VERSION ""

NS_ :

BS_:

BU_: WPC2 RLPSU DPSU APSU PSB SHVU_RR vHS_B2 FCS EMCU SLB ARS RCM CGW_CCU vDummy_HS_B ATS RLHV SGU PFSU ALBCU DSAU SWRC SHVU_FR RCS RRPSU BLTN_CAM SCM DLBCU OHCL RWPC RRHV WPC HOD ASAU

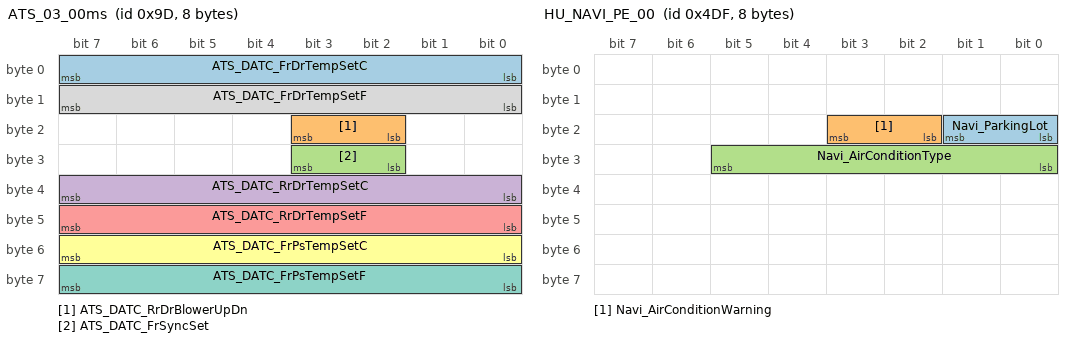
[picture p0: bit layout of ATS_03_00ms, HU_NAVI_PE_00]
BO_ 157 ATS_03_00ms: 8 ATS
 SG_ ATS_DATC_FrDrTempSetC : 0|8@1+ (0.5,14) [0|0] ""  CGW_CCU
 SG_ ATS_DATC_RrDrBlowerUpDn : 18|2@1+ (1,0) [0|0] ""  CGW_CCU
 SG_ ATS_DATC_FrSyncSet : 26|2@1+ (1,0) [0|0] ""  CGW_CCU
 SG_ ATS_DATC_RrDrTempSetC : 32|8@1+ (0.5,14) [0|0] ""  CGW_CCU
 SG_ ATS_DATC_RrDrTempSetF : 40|8@1+ (1,56) [0|0] ""  CGW_CCU
 SG_ ATS_DATC_FrPsTempSetC : 48|8@1+ (0.5,14) [0|0] ""  CGW_CCU
 SG_ ATS_DATC_FrPsTempSetF : 56|8@1+ (1,56) [0|0] ""  CGW_CCU
 SG_ ATS_DATC_FrDrTempSetF : 8|8@1+ (1,56) [0|0] ""  CGW_CCU

BO_ 2176872452 HTCU_05_10ms_4: 8 CGW_CCU

BO_ 158 ATS_02_00ms: 8 ATS
 SG_ ATS_DATC_FrDrBlowerSet : 12|4@1+ (1,0) [0|0] ""  CGW_CCU
 SG_ ATS_DATC_RrDrTempUpDn : 2|2@1+ (1,0) [0|0] ""  CGW_CCU
 SG_ ATS_DATC_RrDrBlowerSet : 20|4@1+ (1,0) [0|0] ""  CGW_CCU
 SG_ ATS_DATC_RrDrModeSet : 24|4@1+ (1,0) [0|0] ""  CGW_CCU
 SG_ ATS_DATC_FrDrModeSet : 28|4@1+ (1,0) [0|0] ""  CGW_CCU
 SG_ ATS_DATC_RrOnOffSet : 32|2@1+ (1,0) [0|0] ""  Vector__XXX
 SG_ ATS_DATC_IntakeSet : 34|2@1+ (1,0) [0|0] ""  CGW_CCU
 SG_ ATS_DATC_OffReq : 36|2@1+ (1,0) [0|0] ""  Vector__XXX
 SG_ ATS_DATC_FrDrAutoSet : 38|2@1+ (1,0) [0|0] ""  CGW_CCU
 SG_ ATS_DATC_FrPsTempUpDn : 4|2@1+ (1,0) [0|0] ""  CGW_CCU
 SG_ ATS_DATC_FrDefog : 42|2@1+ (1,0) [0|0] ""  CGW_CCU
 SG_ ATS_DATC_RrSyncSet : 44|2@1+ (1,0) [0|0] ""  CGW_CCU
 SG_ ATS_DATC_AcSet : 46|2@1+ (1,0) [0|0] ""  CGW_CCU
 SG_ ATS_DATC_AirCleaningSet : 56|2@1+ (1,0) [0|0] ""  CGW_CCU
 SG_ ATS_DATC_FrDrBlowerUpDn : 58|2@1+ (1,0) [0|0] ""  CGW_CCU
 SG_ ATS_DATC_FrDrTempUpDn : 6|2@1+ (1,0) [0|0] ""  CGW_CCU
 SG_ ATS_DATC_RrDrAutoSet : 62|2@1+ (1,0) [0|0] ""  CGW_CCU

BO_ 694 ASAU_02_00ms: 8 APSU
 SG_ ASAU_NotFootMsgOperStaWarn : 0|2@1+ (1,0) [0|0] ""  Vector__XXX

BO_ 1247 HU_NAVI_PE_00: 8 CGW_CCU
 SG_ Navi_ParkingLot : 16|2@1+ (1,0) [0|0] ""  Vector__XXX
 SG_ Navi_AirConditionWarning : 18|2@1+ (1,0) [0|0] ""  RCM
 SG_ Navi_AirConditionType : 24|6@1+ (1,0) [0|0] ""  Vector__XXX

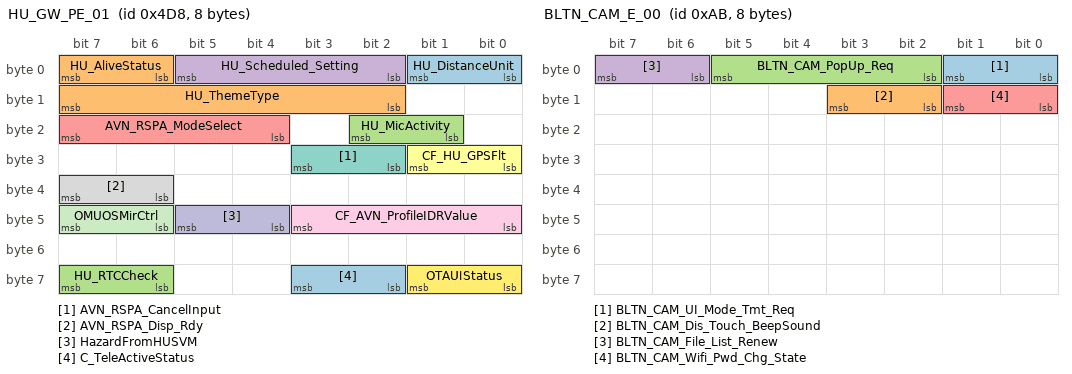
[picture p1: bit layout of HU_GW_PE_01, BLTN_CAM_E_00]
BO_ 1240 HU_GW_PE_01: 8 CGW_CCU
 SG_ HU_DistanceUnit : 0|2@1+ (1,0) [0|0] ""  Vector__XXX
 SG_ HU_ThemeType : 10|6@1+ (1,0) [0|0] ""  ATS,BLTN_CAM
 SG_ HU_MicActivity : 17|2@1+ (1,0) [0|0] ""  Vector__XXX
 SG_ HU_Scheduled_Setting : 2|4@1+ (1,0) [0|0] ""  Vector__XXX
 SG_ AVN_RSPA_ModeSelect : 20|4@1+ (1,0) [0|0] ""  Vector__XXX
 SG_ CF_HU_GPSFlt : 24|2@1+ (1,0) [0|0] ""  Vector__XXX
 SG_ AVN_RSPA_CancelInput : 26|2@1+ (1,0) [0|3] ""  Vector__XXX
 SG_ AVN_RSPA_Disp_Rdy : 38|2@1+ (1,0) [0|0] ""  Vector__XXX
 SG_ CF_AVN_ProfileIDRValue : 40|4@1+ (1,0) [0|0] ""  WPC,RWPC,DPSU,DLBCU,RCM,BLTN_CAM,SGU,WPC2
 SG_ HazardFromHUSVM : 44|2@1+ (1,0) [0|0] ""  Vector__XXX
 SG_ OMUOSMirCtrl : 46|2@1+ (1,0) [0|0] ""  Vector__XXX
 SG_ OTAUIStatus : 56|2@1+ (1,0) [0|0] ""  Vector__XXX
 SG_ C_TeleActiveStatus : 58|2@1+ (1,0) [0|0] ""  Vector__XXX
 SG_ HU_AliveStatus : 6|2@1+ (1,0) [0|0] ""  Vector__XXX
 SG_ HU_RTCCheck : 62|2@1+ (1,0) [0|0] ""  APSU

BO_ 2424580353 DATC_12_200ms_1: 8 CGW_CCU
 SG_ DATC_Crc12Val : 0|16@1+ (1,0) [0|0] ""  Vector__XXX
 SG_ DATC_AlvCnt12Val : 16|8@1+ (1,0) [0|0] ""  Vector__XXX
 SG_ DATC_StrWhlHtrSwReq : 24|2@1+ (1,0) [0|0] ""  Vector__XXX
 SG_ DATC_FRStHtrSwReq : 26|2@1+ (1,0) [0|0] ""  APSU,SHVU_FR,SHVU_RR,DPSU
 SG_ DATC_FRStVentSwReq : 28|2@1+ (1,0) [0|0] ""  APSU,SHVU_FR,SHVU_RR,DPSU
 SG_ DATC_RrDefSw : 30|2@1+ (1,0) [0|0] ""  Vector__XXX
 SG_ DATC_FLStOpReq : 32|4@1+ (1,0) [0|0] ""  APSU,SHVU_FR,SHVU_RR,DPSU
 SG_ DATC_FRStOpReq : 36|4@1+ (1,0) [0|0] ""  APSU,SHVU_FR,SHVU_RR
 SG_ DATC_FLStHtrSwReq : 40|2@1+ (1,0) [0|0] ""  APSU,SHVU_FR,SHVU_RR,DPSU
 SG_ DATC_FLStVentSwReq : 42|2@1+ (1,0) [0|0] ""  APSU,SHVU_FR,SHVU_RR,DPSU
 SG_ DATC_FLStTmblrSwReq : 44|2@1+ (1,0) [0|0] ""  APSU,SHVU_FR
 SG_ DATC_FRStTmblrSwReq : 46|2@1+ (1,0) [0|0] ""  APSU,SHVU_FR
 SG_ DATC_RRStHtrSwReq : 48|2@1+ (1,0) [0|0] ""  RRHV,SHVU_FR,SHVU_RR,RRPSU,RLPSU
 SG_ DATC_RRStVentSwReq : 50|2@1+ (1,0) [0|0] ""  RRHV,SHVU_FR,SHVU_RR,RRPSU,RLPSU
 SG_ DATC_RLStHtrSwReq : 52|2@1+ (1,0) [0|0] ""  RLHV,SHVU_FR,SHVU_RR,RRPSU,RLPSU
 SG_ DATC_RLStVentSwReq : 54|2@1+ (1,0) [0|0] ""  RLHV,SHVU_FR,SHVU_RR,RRPSU,RLPSU
 SG_ DATC_FRWndShldHtSW : 56|2@1+ (1,0) [0|0] ""  Vector__XXX
 SG_ DATC_WhistlelNoise : 58|2@1+ (1,0) [0|0] ""  Vector__XXX
 SG_ DATC_WdwClsReq : 60|2@1+ (1,0) [0|0] ""  Vector__XXX
 SG_ DATC_RRSyncDis : 62|2@1+ (1,0) [0|0] ""  ATS

BO_ 171 BLTN_CAM_E_00: 8 BLTN_CAM
 SG_ BLTN_CAM_UI_Mode_Tmt_Req : 0|2@1+ (1,0) [0|0] ""  CGW_CCU
 SG_ BLTN_CAM_Dis_Touch_BeepSound : 10|2@1+ (1,0) [0|0] ""  Vector__XXX
 SG_ BLTN_CAM_PopUp_Req : 2|4@1+ (1,0) [0|0] ""  CGW_CCU
 SG_ BLTN_CAM_File_List_Renew : 6|2@1+ (1,0) [0|0] ""  CGW_CCU
 SG_ BLTN_CAM_Wifi_Pwd_Chg_State : 8|2@1+ (1,0) [0|0] ""  CGW_CCU

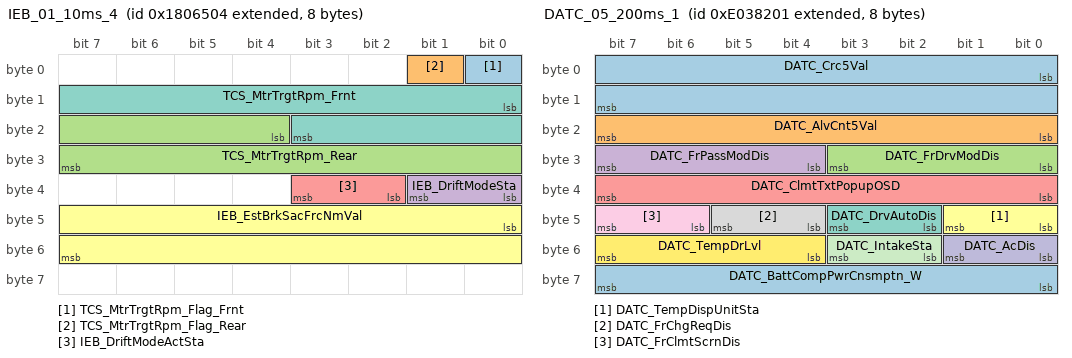
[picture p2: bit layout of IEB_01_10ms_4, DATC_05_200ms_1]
BO_ 2172675332 IEB_01_10ms_4: 8 CGW_CCU
 SG_ TCS_MtrTrgtRpm_Flag_Frnt : 0|1@1+ (1,0) [0|0] ""  Vector__XXX
 SG_ TCS_MtrTrgtRpm_Flag_Rear : 1|1@1+ (1,0) [0|0] ""  Vector__XXX
 SG_ TCS_MtrTrgtRpm_Rear : 20|12@1+ (8,0) [0|0] "rpm"  Vector__XXX
 SG_ IEB_DriftModeSta : 32|2@1+ (1,0) [0|0] ""  Vector__XXX
 SG_ IEB_DriftModeActSta : 34|2@1+ (1,0) [0|0] ""  Vector__XXX
 SG_ IEB_EstBrkSacFrcNmVal : 40|16@1+ (1,0) [0|0] ""  Vector__XXX
 SG_ TCS_MtrTrgtRpm_Frnt : 8|12@1+ (8,0) [0|0] "rpm"  Vector__XXX

BO_ 2382594561 DATC_05_200ms_1: 8 CGW_CCU
 SG_ DATC_Crc5Val : 0|16@1+ (1,0) [0|0] ""  Vector__XXX
 SG_ DATC_AlvCnt5Val : 16|8@1+ (1,0) [0|0] ""  Vector__XXX
 SG_ DATC_FrDrvModDis : 24|4@1+ (1,0) [0|0] ""  ATS
 SG_ DATC_FrPassModDis : 28|4@1+ (1,0) [0|0] ""  ATS
 SG_ DATC_ClmtTxtPopupOSD : 32|8@1+ (1,0) [0|0] ""  ATS
 SG_ DATC_TempDispUnitSta : 40|2@1+ (1,0) [0|0] ""  ATS
 SG_ DATC_DrvAutoDis : 42|2@1+ (1,0) [0|0] ""  ATS
 SG_ DATC_FrChgReqDis : 44|2@1+ (1,0) [0|0] ""  Vector__XXX
 SG_ DATC_FrClmtScrnDis : 46|2@1+ (1,0) [0|0] ""  ATS
 SG_ DATC_AcDis : 48|2@1+ (1,0) [0|0] ""  ATS
 SG_ DATC_IntakeSta : 50|2@1+ (1,0) [0|0] ""  Vector__XXX
 SG_ DATC_TempDrLvl : 52|4@1+ (1,0) [0|0] ""  Vector__XXX
 SG_ DATC_BattCompPwrCnsmptn_W : 56|8@1+ (40,0) [0|0] "W"  Vector__XXX

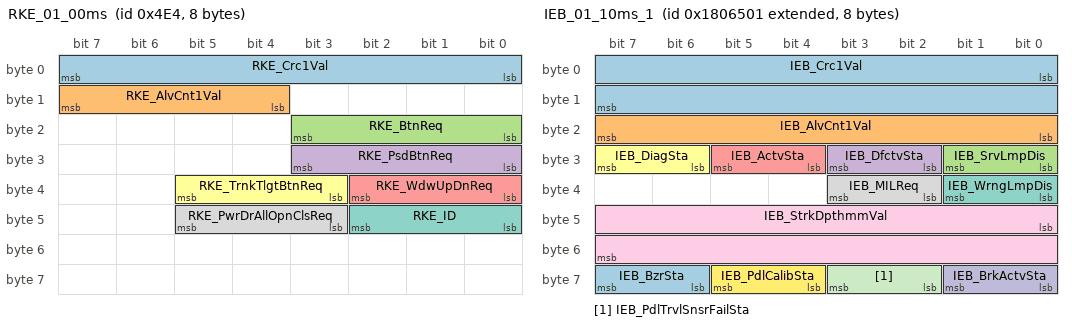
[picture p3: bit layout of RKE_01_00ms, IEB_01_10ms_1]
BO_ 1252 RKE_01_00ms: 8 CGW_CCU
 SG_ RKE_Crc1Val : 0|8@1+ (1,0) [0|0] ""  Vector__XXX
 SG_ RKE_AlvCnt1Val : 12|4@1+ (1,0) [0|0] ""  Vector__XXX
 SG_ RKE_BtnReq : 16|4@1+ (1,0) [0|0] ""  ATS
 SG_ RKE_PsdBtnReq : 24|4@1+ (1,0) [0|0] ""  Vector__XXX
 SG_ RKE_WdwUpDnReq : 32|3@1+ (1,0) [0|0] ""  RCM
 SG_ RKE_TrnkTlgtBtnReq : 35|3@1+ (1,0) [0|0] ""  Vector__XXX
 SG_ RKE_ID : 40|3@1+ (1,0) [0|0] ""  Vector__XXX
 SG_ RKE_PwrDrAllOpnClsReq : 43|3@1+ (1,0) [0|0] ""  Vector__XXX

BO_ 2172675329 IEB_01_10ms_1: 8 CGW_CCU
 SG_ IEB_Crc1Val : 0|16@1+ (1,0) [0|0] ""  Vector__XXX
 SG_ IEB_AlvCnt1Val : 16|8@1+ (1,0) [0|0] ""  Vector__XXX
 SG_ IEB_SrvLmpDis : 24|2@1+ (1,0) [0|0] ""  Vector__XXX
 SG_ IEB_DfctvSta : 26|2@1+ (1,0) [0|0] ""  Vector__XXX
 SG_ IEB_ActvSta : 28|2@1+ (1,0) [0|0] ""  Vector__XXX
 SG_ IEB_DiagSta : 30|2@1+ (1,0) [0|0] ""  Vector__XXX
 SG_ IEB_WrngLmpDis : 32|2@1+ (1,0) [0|0] ""  Vector__XXX
 SG_ IEB_MILReq : 34|2@1+ (1,0) [0|0] ""  Vector__XXX
 SG_ IEB_StrkDpthmmVal : 40|16@1- (0.1,0) [0|0] "mm"  Vector__XXX
 SG_ IEB_BrkActvSta : 56|2@1+ (1,0) [0|0] ""  BLTN_CAM
 SG_ IEB_PdlTrvlSnsrFailSta : 58|2@1+ (1,0) [0|0] ""  Vector__XXX
 SG_ IEB_PdlCalibSta : 60|2@1+ (1,0) [0|0] ""  Vector__XXX
 SG_ IEB_BzrSta : 62|2@1+ (1,0) [0|0] ""  Vector__XXX

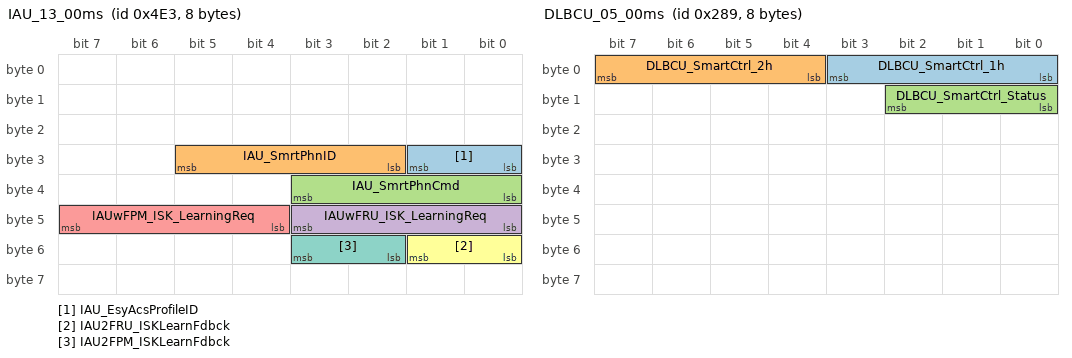
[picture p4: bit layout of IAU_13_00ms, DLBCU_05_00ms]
BO_ 1251 IAU_13_00ms: 8 CGW_CCU
 SG_ IAU_EsyAcsProfileID : 24|2@1+ (1,0) [0|0] ""  DPSU
 SG_ IAU_SmrtPhnID : 26|4@1+ (1,0) [0|0] ""  Vector__XXX
 SG_ IAU_SmrtPhnCmd : 32|4@1+ (1,0) [0|0] ""  Vector__XXX
 SG_ IAUwFRU_ISK_LearningReq : 40|4@1+ (1,0) [0|0] ""  Vector__XXX
 SG_ IAUwFPM_ISK_LearningReq : 44|4@1+ (1,0) [0|0] ""  Vector__XXX
 SG_ IAU2FRU_ISKLearnFdbck : 48|2@1+ (1,0) [0|0] ""  Vector__XXX
 SG_ IAU2FPM_ISKLearnFdbck : 50|2@1+ (1,0) [0|0] ""  Vector__XXX

BO_ 649 DLBCU_05_00ms: 8 DLBCU
 SG_ DLBCU_SmartCtrl_1h : 0|4@1+ (1,0) [0|0] ""  CGW_CCU
 SG_ DLBCU_SmartCtrl_2h : 4|4@1+ (1,0) [0|0] ""  CGW_CCU
 SG_ DLBCU_SmartCtrl_Status : 8|3@1+ (1,0) [0|0] ""  CGW_CCU

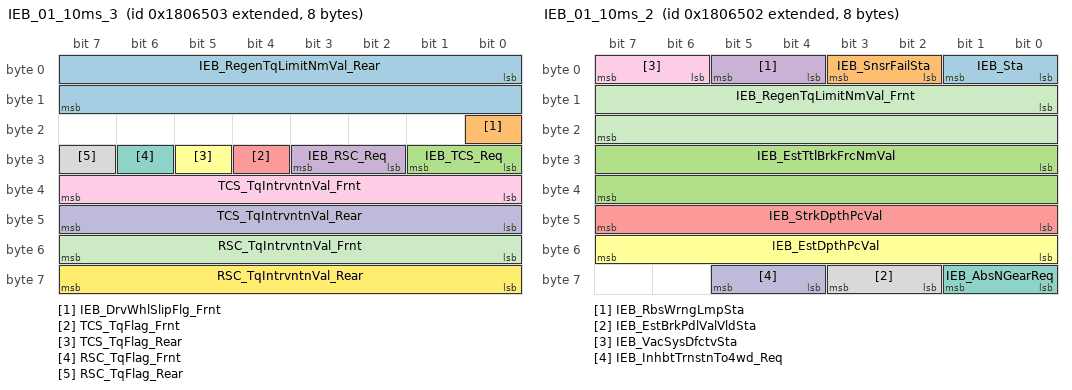
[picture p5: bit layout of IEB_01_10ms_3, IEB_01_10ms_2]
BO_ 2172675331 IEB_01_10ms_3: 8 CGW_CCU
 SG_ IEB_RegenTqLimitNmVal_Rear : 0|16@1+ (1,0) [0|0] "Nm"  Vector__XXX
 SG_ IEB_DrvWhlSlipFlg_Frnt : 16|1@1+ (1,0) [0|0] ""  Vector__XXX
 SG_ IEB_TCS_Req : 24|2@1+ (1,0) [0|0] ""  Vector__XXX
 SG_ IEB_RSC_Req : 26|2@1+ (1,0) [0|0] ""  Vector__XXX
 SG_ TCS_TqFlag_Frnt : 28|1@1+ (1,0) [0|0] ""  Vector__XXX
 SG_ TCS_TqFlag_Rear : 29|1@1+ (1,0) [0|0] ""  Vector__XXX
 SG_ RSC_TqFlag_Frnt : 30|1@1+ (1,0) [0|0] ""  Vector__XXX
 SG_ RSC_TqFlag_Rear : 31|1@1+ (1,0) [0|0] ""  Vector__XXX
 SG_ TCS_TqIntrvntnVal_Frnt : 32|8@1+ (0.390625,0) [0|0] "%"  Vector__XXX
 SG_ TCS_TqIntrvntnVal_Rear : 40|8@1+ (0.390625,0) [0|0] "%"  Vector__XXX
 SG_ RSC_TqIntrvntnVal_Frnt : 48|8@1+ (0.390625,0) [0|0] "%"  Vector__XXX
 SG_ RSC_TqIntrvntnVal_Rear : 56|8@1+ (0.390625,0) [0|0] "%"  Vector__XXX

BO_ 2172675330 IEB_01_10ms_2: 8 CGW_CCU
 SG_ IEB_Sta : 0|2@1+ (1,0) [0|0] ""  Vector__XXX
 SG_ IEB_SnsrFailSta : 2|2@1+ (1,0) [0|0] ""  Vector__XXX
 SG_ IEB_EstTtlBrkFrcNmVal : 24|16@1+ (1,0) [0|0] "Nm"  Vector__XXX
 SG_ IEB_RbsWrngLmpSta : 4|2@1+ (1,0) [0|0] ""  Vector__XXX
 SG_ IEB_StrkDpthPcVal : 40|8@1+ (0.39215,0) [0|0] "%"  Vector__XXX
 SG_ IEB_EstDpthPcVal : 48|8@1+ (0.390625,0) [0|0] "%"  Vector__XXX
 SG_ IEB_AbsNGearReq : 56|2@1+ (1,0) [0|0] ""  Vector__XXX
 SG_ IEB_EstBrkPdlValVldSta : 58|2@1+ (1,0) [0|0] ""  Vector__XXX
 SG_ IEB_VacSysDfctvSta : 6|2@1+ (1,0) [0|0] ""  Vector__XXX
 SG_ IEB_InhbtTrnstnTo4wd_Req : 60|2@1+ (1,0) [0|0] ""  Vector__XXX
 SG_ IEB_RegenTqLimitNmVal_Frnt : 8|16@1+ (1,0) [0|0] "Nm"  Vector__XXX

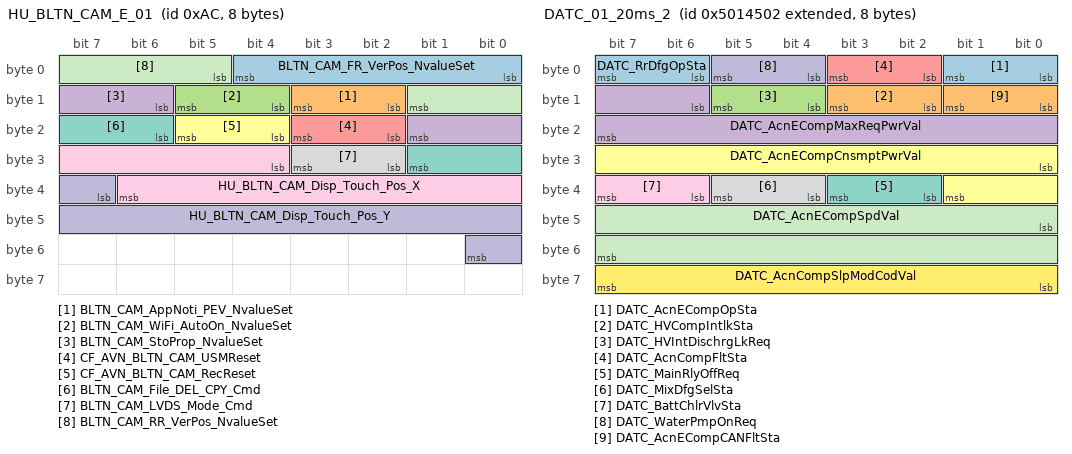
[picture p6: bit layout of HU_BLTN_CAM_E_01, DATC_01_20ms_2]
BO_ 172 HU_BLTN_CAM_E_01: 8 CGW_CCU
 SG_ BLTN_CAM_FR_VerPos_NvalueSet : 0|5@1+ (1,0) [0|0] ""  BLTN_CAM
 SG_ BLTN_CAM_AppNoti_PEV_NvalueSet : 10|2@1+ (1,0) [0|0] ""  BLTN_CAM
 SG_ BLTN_CAM_WiFi_AutoOn_NvalueSet : 12|2@1+ (1,0) [0|0] ""  BLTN_CAM
 SG_ BLTN_CAM_StoProp_NvalueSet : 14|4@1+ (1,0) [0|0] ""  BLTN_CAM
 SG_ CF_AVN_BLTN_CAM_USMReset : 18|2@1+ (1,0) [0|0] ""  BLTN_CAM
 SG_ CF_AVN_BLTN_CAM_RecReset : 20|2@1+ (1,0) [0|0] ""  BLTN_CAM
 SG_ BLTN_CAM_File_DEL_CPY_Cmd : 22|4@1+ (1,0) [0|0] ""  BLTN_CAM
 SG_ BLTN_CAM_LVDS_Mode_Cmd : 26|2@1+ (1,0) [0|0] ""  BLTN_CAM
 SG_ HU_BLTN_CAM_Disp_Touch_Pos_X : 28|11@1+ (1,0) [0|0] ""  BLTN_CAM
 SG_ HU_BLTN_CAM_Disp_Touch_Pos_Y : 39|10@1+ (1,0) [0|0] ""  BLTN_CAM
 SG_ BLTN_CAM_RR_VerPos_NvalueSet : 5|5@1+ (1,0) [0|0] ""  BLTN_CAM

BO_ 2231452930 DATC_01_20ms_2: 8 CGW_CCU
 SG_ DATC_AcnECompOpSta : 0|2@1+ (1,0) [0|0] "flag"  Vector__XXX
 SG_ DATC_HVCompIntlkSta : 10|2@1+ (1,0) [0|0] "flag"  Vector__XXX
 SG_ DATC_HVIntDischrgLkReq : 12|2@1+ (1,0) [0|0] "flag"  Vector__XXX
 SG_ DATC_AcnECompMaxReqPwrVal : 14|10@1+ (20,0) [0|0] "W"  Vector__XXX
 SG_ DATC_AcnCompFltSta : 2|2@1+ (1,0) [0|0] "flag"  Vector__XXX
 SG_ DATC_AcnECompCnsmptPwrVal : 24|10@1+ (20,0) [0|0] "W"  Vector__XXX
 SG_ DATC_MainRlyOffReq : 34|2@1+ (1,0) [0|0] "flag"  Vector__XXX
 SG_ DATC_MixDfgSelSta : 36|2@1+ (1,0) [0|0] "flag"  Vector__XXX
 SG_ DATC_BattChlrVlvSta : 38|2@1+ (1,0) [0|0] ""  Vector__XXX
 SG_ DATC_WaterPmpOnReq : 4|2@1+ (1,0) [0|0] "flag"  Vector__XXX
 SG_ DATC_AcnECompSpdVal : 40|16@1+ (1,0) [0|0] "rpm"  Vector__XXX
 SG_ DATC_AcnCompSlpModCodVal : 56|8@1+ (1,0) [0|0] ""  Vector__XXX
 SG_ DATC_RrDfgOpSta : 6|2@1+ (1,0) [0|0] "flag"  Vector__XXX
 SG_ DATC_AcnECompCANFltSta : 8|2@1+ (1,0) [0|0] "flag"  Vector__XXX

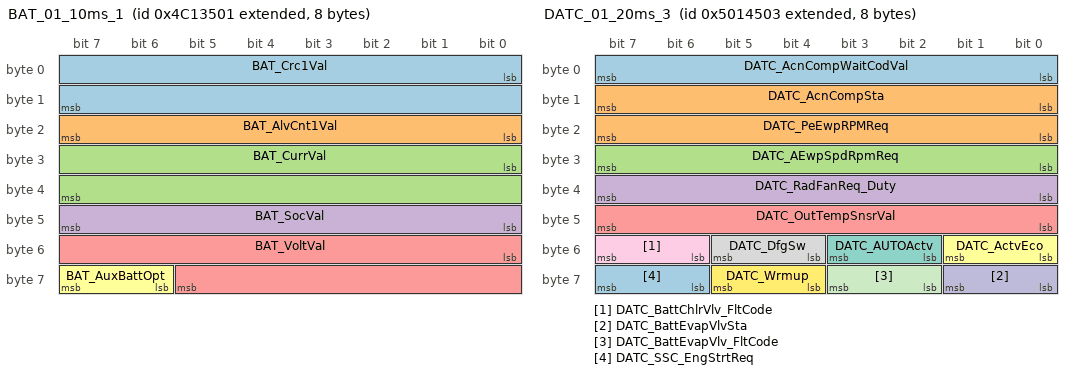
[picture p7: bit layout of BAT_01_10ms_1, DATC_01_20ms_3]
BO_ 2227254529 BAT_01_10ms_1: 8 CGW_CCU
 SG_ BAT_Crc1Val : 0|16@1+ (1,0) [0|0] ""  Vector__XXX
 SG_ BAT_AlvCnt1Val : 16|8@1+ (1,0) [0|0] ""  Vector__XXX
 SG_ BAT_CurrVal : 24|16@1+ (0.01,-327) [0|0] "A"  Vector__XXX
 SG_ BAT_SocVal : 40|8@1+ (1,0) [0|0] "%"  BLTN_CAM
 SG_ BAT_VoltVal : 48|14@1+ (0.001,6) [0|0] "V"  Vector__XXX
 SG_ BAT_AuxBattOpt : 62|2@1+ (1,0) [0|0] ""  Vector__XXX

BO_ 2231452931 DATC_01_20ms_3: 8 CGW_CCU
 SG_ DATC_AcnCompWaitCodVal : 0|8@1+ (1,0) [0|0] ""  Vector__XXX
 SG_ DATC_PeEwpRPMReq : 16|8@1+ (30,0) [0|0] ""  Vector__XXX
 SG_ DATC_AEwpSpdRpmReq : 24|8@1+ (20,0) [0|0] "rpm"  Vector__XXX
 SG_ DATC_RadFanReq_Duty : 32|8@1+ (1,0) [0|0] "%"  Vector__XXX
 SG_ DATC_OutTempSnsrVal : 40|8@1+ (0.5,-40) [0|0] "¡É"  RCM
 SG_ DATC_ActvEco : 48|2@1+ (1,0) [0|0] ""  Vector__XXX
 SG_ DATC_AUTOActv : 50|2@1+ (1,0) [0|0] ""  Vector__XXX
 SG_ DATC_DfgSw : 52|2@1+ (1,0) [0|0] ""  Vector__XXX
 SG_ DATC_BattChlrVlv_FltCode : 54|2@1+ (1,0) [0|0] ""  Vector__XXX
 SG_ DATC_BattEvapVlvSta : 56|2@1+ (1,0) [0|0] ""  Vector__XXX
 SG_ DATC_BattEvapVlv_FltCode : 58|2@1+ (1,0) [0|0] ""  Vector__XXX
 SG_ DATC_Wrmup : 60|2@1+ (1,0) [0|0] ""  Vector__XXX
 SG_ DATC_SSC_EngStrtReq : 62|2@1+ (1,0) [0|0] ""  Vector__XXX
 SG_ DATC_AcnCompSta : 8|8@1+ (1,0) [0|0] ""  Vector__XXX

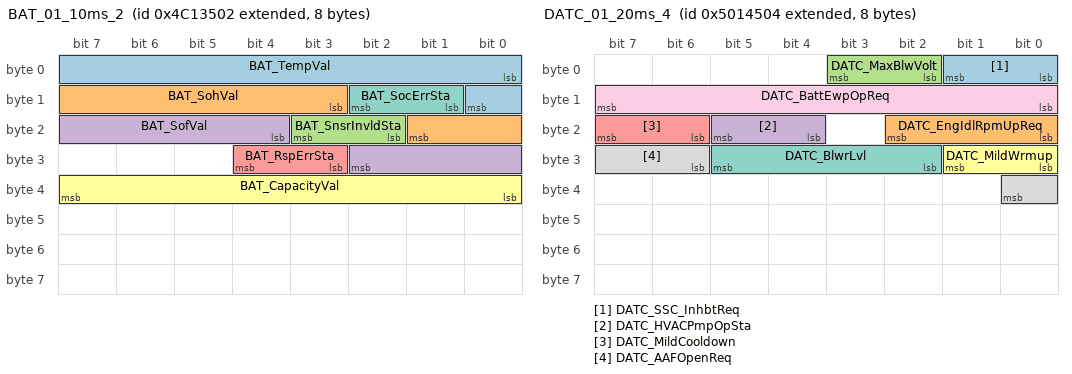
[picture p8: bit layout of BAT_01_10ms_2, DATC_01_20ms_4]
BO_ 2227254530 BAT_01_10ms_2: 8 CGW_CCU
 SG_ BAT_TempVal : 0|9@1+ (0.5,-40) [0|0] "¡É"  Vector__XXX
 SG_ BAT_SohVal : 11|7@1+ (1,0) [0|0] "%"  Vector__XXX
 SG_ BAT_SnsrInvldSta : 18|2@1+ (1,0) [0|0] ""  Vector__XXX
 SG_ BAT_SofVal : 20|7@1+ (0.1,0) [0|0] "V"  Vector__XXX
 SG_ BAT_RspErrSta : 27|2@1+ (1,0) [0|0] ""  Vector__XXX
 SG_ BAT_CapacityVal : 32|8@1+ (1,0) [0|0] ""  Vector__XXX
 SG_ BAT_SocErrSta : 9|2@1+ (1,0) [0|0] ""  Vector__XXX

BO_ 2231452929 DATC_01_20ms_1: 8 CGW_CCU
 SG_ DATC_Crc1Val : 0|16@1+ (1,0) [0|0] ""  Vector__XXX
 SG_ DATC_AlvCnt1Val : 16|8@1+ (1,0) [0|0] ""  Vector__XXX
 SG_ DATC_PtcRlySta : 24|3@1+ (1,0) [0|0] ""  Vector__XXX
 SG_ DATC_ManufacturerTyp : 27|3@1+ (1,0) [0|0] ""  Vector__XXX
 SG_ DATC_DatcPwmSts : 30|2@1+ (1,0) [0|0] ""  Vector__XXX
 SG_ DATC_AcnCompTyp : 32|3@1+ (1,0) [0|0] "flag"  Vector__XXX
 SG_ DATC_EewpRpmLvlReq : 35|3@1+ (1,0) [0|0] ""  Vector__XXX
 SG_ DATC_Cooldown : 38|2@1+ (1,0) [0|0] ""  Vector__XXX
 SG_ DATC_AcnReq : 40|2@1+ (1,0) [0|0] ""  Vector__XXX
 SG_ DATC_BlwSta : 42|2@1+ (1,0) [0|0] ""  Vector__XXX
 SG_ DATC_BlwMaxSta : 44|2@1+ (1,0) [0|0] ""  Vector__XXX
 SG_ DATC_EngStrtReq : 46|2@1+ (1,0) [0|0] ""  Vector__XXX
 SG_ DATC_IsgInhbtReq : 48|2@1+ (1,0) [0|0] ""  Vector__XXX
 SG_ DATC_AcnCompOnReq : 50|2@1+ (1,0) [0|0] "flag"  Vector__XXX
 SG_ DATC_SrvLmpReq : 52|2@1+ (1,0) [0|0] ""  Vector__XXX
 SG_ DATC_EcvFltSta : 54|2@1+ (1,0) [0|0] ""  Vector__XXX
 SG_ DATC_CalcAcnCompTqVal : 56|8@1+ (0.2,0) [0|0] "Nm"  Vector__XXX

BO_ 2231452932 DATC_01_20ms_4: 8 CGW_CCU
 SG_ DATC_SSC_InhbtReq : 0|2@1+ (1,0) [0|0] ""  Vector__XXX
 SG_ DATC_EngIdlRpmUpReq : 16|3@1+ (1,0) [0|0] ""  Vector__XXX
 SG_ DATC_MaxBlwVolt : 2|2@1+ (1,0) [0|0] ""  Vector__XXX
 SG_ DATC_HVACPmpOpSta : 20|2@1+ (1,0) [0|0] ""  Vector__XXX
 SG_ DATC_MildCooldown : 22|2@1+ (1,0) [0|0] ""  Vector__XXX
 SG_ DATC_MildWrmup : 24|2@1+ (1,0) [0|0] ""  Vector__XXX
 SG_ DATC_BlwrLvl : 26|4@1+ (1,0) [0|0] ""  Vector__XXX
 SG_ DATC_AAFOpenReq : 30|3@1+ (1,0) [0|0] ""  Vector__XXX
 SG_ DATC_BattEwpOpReq : 8|8@1+ (30,0) [0|0] "rpm"  Vector__XXX

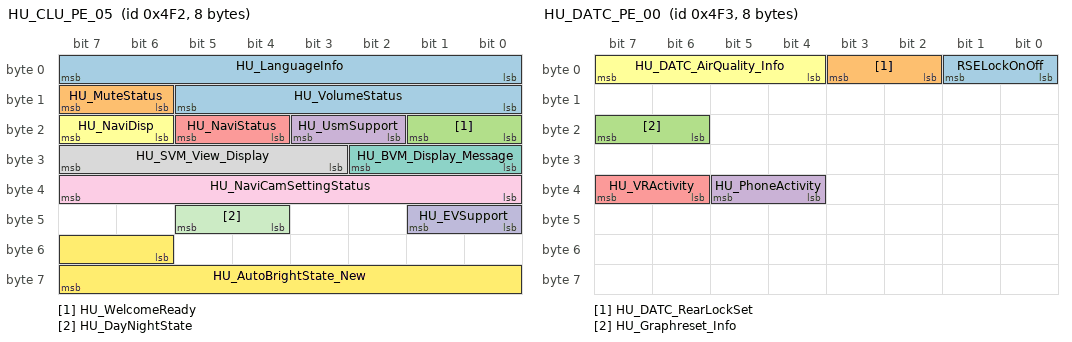
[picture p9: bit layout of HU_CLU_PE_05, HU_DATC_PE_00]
BO_ 1266 HU_CLU_PE_05: 8 CGW_CCU
 SG_ HU_LanguageInfo : 0|8@1+ (1,0) [0|0] ""  ATS,BLTN_CAM
 SG_ HU_MuteStatus : 14|2@1+ (1,0) [0|0] ""  Vector__XXX
 SG_ HU_WelcomeReady : 16|2@1+ (1,0) [0|0] ""  Vector__XXX
 SG_ HU_UsmSupport : 18|2@1+ (1,0) [0|0] ""  Vector__XXX
 SG_ HU_NaviStatus : 20|2@1+ (1,0) [0|0] ""  Vector__XXX
 SG_ HU_NaviDisp : 22|2@1+ (1,0) [0|0] ""  Vector__XXX
 SG_ HU_BVM_Display_Message : 24|3@1+ (1,0) [0|0] ""  Vector__XXX
 SG_ HU_SVM_View_Display : 27|5@1+ (1,0) [0|0] ""  Vector__XXX
 SG_ HU_NaviCamSettingStatus : 32|8@1+ (1,0) [0|0] ""  Vector__XXX
 SG_ HU_EVSupport : 40|2@1+ (1,0) [0|0] ""  Vector__XXX
 SG_ HU_DayNightState : 44|2@1+ (1,0) [0|0] ""  Vector__XXX
 SG_ HU_AutoBrightState_New : 54|10@1+ (1,0) [0|0] ""  Vector__XXX
 SG_ HU_VolumeStatus : 8|6@1+ (1,0) [0|0] ""  Vector__XXX

BO_ 191 RL_SHVU_03_200ms: 8 SHVU_RR
 SG_ RL_SHVU_DTCdisplay : 0|8@1+ (1,0) [0|0] ""  ATS
 SG_ RL_SHVU_DiagMode : 8|2@1+ (1,0) [0|0] ""  ATS

BO_ 1267 HU_DATC_PE_00: 8 CGW_CCU
 SG_ RSELockOnOff : 0|2@1+ (1,0) [0|0] ""  APSU,ATS
 SG_ HU_DATC_RearLockSet : 2|2@1+ (1,0) [0|0] ""  Vector__XXX
 SG_ HU_Graphreset_Info : 22|2@1+ (1,0) [0|0] ""  Vector__XXX
 SG_ HU_PhoneActivity : 36|2@1+ (1,0) [0|0] ""  Vector__XXX
 SG_ HU_VRActivity : 38|2@1+ (1,0) [0|0] ""  Vector__XXX
 SG_ HU_DATC_AirQuality_Info : 4|4@1+ (1,0) [0|0] ""  Vector__XXX

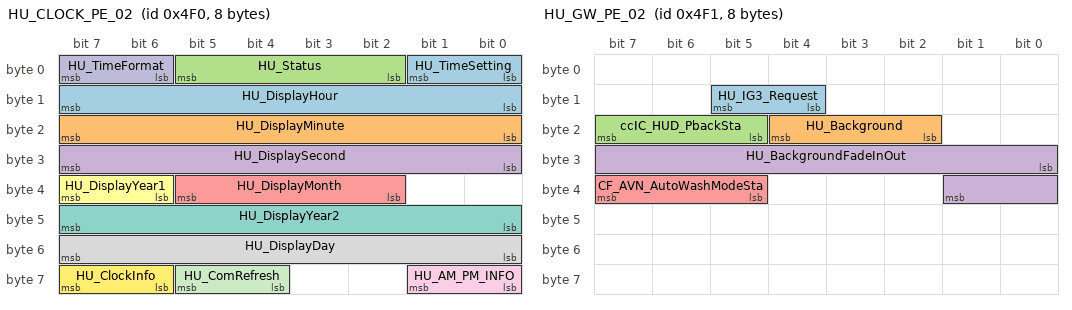
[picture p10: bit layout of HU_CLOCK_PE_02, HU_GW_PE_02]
BO_ 1264 HU_CLOCK_PE_02: 8 CGW_CCU
 SG_ HU_TimeSetting : 0|2@1+ (1,0) [0|0] ""  ATS,BLTN_CAM
 SG_ HU_DisplayMinute : 16|8@1+ (1,0) [0|0] ""  ATS,BLTN_CAM
 SG_ HU_Status : 2|4@1+ (1,0) [0|0] ""  ATS,BLTN_CAM
 SG_ HU_DisplaySecond : 24|8@1+ (1,0) [0|0] ""  ATS,BLTN_CAM
 SG_ HU_DisplayMonth : 34|4@1+ (1,0) [0|0] ""  ATS,BLTN_CAM
 SG_ HU_DisplayYear1 : 38|2@1+ (1,0) [0|0] ""  ATS,BLTN_CAM
 SG_ HU_DisplayYear2 : 40|8@1+ (1,0) [0|0] ""  ATS,BLTN_CAM
 SG_ HU_DisplayDay : 48|8@1+ (1,0) [0|0] ""  ATS,BLTN_CAM
 SG_ HU_AM_PM_INFO : 56|2@1+ (1,0) [0|0] ""  ATS,BLTN_CAM
 SG_ HU_TimeFormat : 6|2@1+ (1,0) [0|0] ""  ATS,BLTN_CAM
 SG_ HU_ComRefresh : 60|2@1+ (1,0) [0|0] ""  ATS,BLTN_CAM
 SG_ HU_ClockInfo : 62|2@1+ (1,0) [0|0] ""  ATS,BLTN_CAM
 SG_ HU_DisplayHour : 8|8@1+ (1,0) [0|0] ""  ATS,BLTN_CAM

BO_ 1265 HU_GW_PE_02: 8 CGW_CCU
 SG_ HU_IG3_Request : 12|2@1+ (1,0) [0|0] ""  Vector__XXX
 SG_ HU_Background : 18|3@1+ (1,0) [0|0] ""  ATS,BLTN_CAM
 SG_ ccIC_HUD_PbackSta : 21|3@1+ (1,0) [0|0] ""  DPSU
 SG_ HU_BackgroundFadeInOut : 24|10@1+ (0.1,0) [0|0] "%"  ATS,BLTN_CAM
 SG_ CF_AVN_AutoWashModeSta : 37|3@1+ (1,0) [0|0] ""  RCM

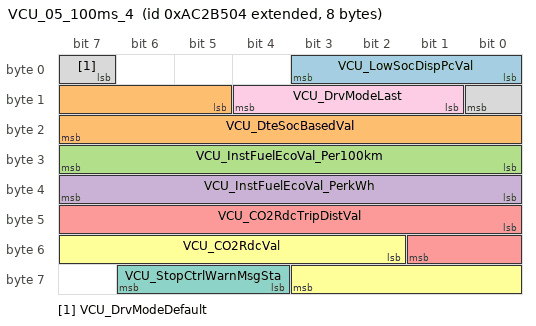
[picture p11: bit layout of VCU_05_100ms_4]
BO_ 2328016132 VCU_05_100ms_4: 8 CGW_CCU
 SG_ VCU_LowSocDispPcVal : 0|4@1+ (1,0) [0|0] ""  Vector__XXX
 SG_ VCU_DteSocBasedVal : 13|11@1+ (1,0) [0|0] "km"  Vector__XXX
 SG_ VCU_InstFuelEcoVal_Per100km : 24|8@1+ (0.5,0) [0|126.5] "kWh/100km"  Vector__XXX
 SG_ VCU_InstFuelEcoVal_PerkWh : 32|8@1+ (0.1,0) [0|25.5] "km/kWh"  Vector__XXX
 SG_ VCU_CO2RdcTripDistVal : 40|10@1+ (1,0) [0|1023] "km"  Vector__XXX
 SG_ VCU_CO2RdcVal : 50|10@1+ (100,0) [0|102300] "g"  Vector__XXX
 SG_ VCU_StopCtrlWarnMsgSta : 60|3@1+ (1,0) [0|0] ""  Vector__XXX
 SG_ VCU_DrvModeDefault : 7|2@1+ (1,0) [0|0] ""  Vector__XXX
 SG_ VCU_DrvModeLast : 9|4@1+ (1,0) [0|0] ""  Vector__XXX

BO_TX_BU_ 191 : SHVU_RR,SHVU_FR,RLHV;
BO_TX_BU_ 694 : APSU,ASAU;
CM_ BO_ 694 "[EC] On Event and On Change";
CM_ SG_ 694 ASAU_NotFootMsgOperStaWarn "Passenger Foot Massage Operation Disable Mode";
CM_ BO_ 158 "[EC] On Event and On Change";
CM_ SG_ 158 ATS_DATC_FrDrBlowerSet "Front Driver side Blower Set";
CM_ SG_ 158 ATS_DATC_RrDrTempUpDn "Rear Driver side Temp Up Down";
CM_ SG_ 158 ATS_DATC_RrDrBlowerSet "Rear Driver side Blower Up Down";
CM_ SG_ 158 ATS_DATC_RrDrModeSet "Rear Driver side Mode Set";
CM_ SG_ 158 ATS_DATC_FrDrModeSet "Front Driver side Mode Set";
CM_ SG_ 158 ATS_DATC_RrOnOffSet "Rear Climate On/Off Set";
CM_ SG_ 158 ATS_DATC_IntakeSet "Intake Set";
CM_ SG_ 158 ATS_DATC_OffReq "Front Climate Off Set";
CM_ SG_ 158 ATS_DATC_FrDrAutoSet "Front Driver side Auto Set";
CM_ SG_ 158 ATS_DATC_FrPsTempUpDn "Front Passenger side Temp Up Down";
CM_ SG_ 158 ATS_DATC_FrDefog "Front Defog set";
CM_ SG_ 158 ATS_DATC_RrSyncSet "Rear Sync Set";
CM_ SG_ 158 ATS_DATC_AcSet "Ac Set";
CM_ SG_ 158 ATS_DATC_AirCleaningSet "AirCleaning Set";
CM_ SG_ 158 ATS_DATC_FrDrBlowerUpDn "Front Driver Blower Up Down";
CM_ SG_ 158 ATS_DATC_FrDrTempUpDn "Front Driver side Temp Up Down";
CM_ SG_ 158 ATS_DATC_RrDrAutoSet "Rear Driver side Auto Set";
CM_ BO_ 157 "[EC] On Event and On Change";
CM_ SG_ 157 ATS_DATC_FrDrTempSetC "Front Driver side Temp Set (Celsius)";
CM_ SG_ 157 ATS_DATC_RrDrBlowerUpDn "Rear Driver side Blower Up Down";
CM_ SG_ 157 ATS_DATC_FrSyncSet "Front Sync Set";
CM_ SG_ 157 ATS_DATC_RrDrTempSetC "Rear Driver side Temp Set (Celsius)";
CM_ SG_ 157 ATS_DATC_RrDrTempSetF "Rear Driver side Temp Set (Fahrenheit)";
CM_ SG_ 157 ATS_DATC_FrPsTempSetC "Front Passenger side Temp Set (Celsius)";
CM_ SG_ 157 ATS_DATC_FrPsTempSetF "Front Passenger side Temp Set (Fahrenheit)";
CM_ SG_ 157 ATS_DATC_FrDrTempSetF "Front Driver side Temp Set (Fahrenheit)";
CM_ BO_ 2227254529 "[P] Periodic";
CM_ SG_ 2227254529 BAT_Crc1Val "BAT_CyclicRedundancyCheck1Value";
CM_ SG_ 2227254529 BAT_AlvCnt1Val "BAT_AliveCounter1Value";
CM_ SG_ 2227254529 BAT_CurrVal "BAT_CurrentValue";
CM_ SG_ 2227254529 BAT_SocVal "BAT_StateOfChargeValue";
CM_ SG_ 2227254529 BAT_VoltVal "BAT_VoltageValue";
CM_ SG_ 2227254529 BAT_AuxBattOpt "12V Battery Option Value(LFP 12V Battery)";
CM_ BO_ 2227254530 "[P] Periodic";
CM_ SG_ 2227254530 BAT_TempVal "BAT_TemperatureValue";
CM_ SG_ 2227254530 BAT_SohVal "BAT_StateOfHealthValue";
CM_ SG_ 2227254530 BAT_SnsrInvldSta "BAT_SensorInvalidStatus";
CM_ SG_ 2227254530 BAT_SofVal "BAT_StateOfFunctionValue";
CM_ SG_ 2227254530 BAT_RspErrSta "BAT_ResponseErrorStatus";
CM_ SG_ 2227254530 BAT_CapacityVal "12V Battery Capacity Value";
CM_ SG_ 2227254530 BAT_SocErrSta "BAT_SoCErrorStatus";
CM_ BO_ 171 "[EC] On Event and On Change";
CM_ SG_ 171 BLTN_CAM_UI_Mode_Tmt_Req "Built-in Cam UI Mode terminate request.";
CM_ SG_ 171 BLTN_CAM_Dis_Touch_BeepSound "Display Touch Beep Sound of valid space touch.";
CM_ SG_ 171 BLTN_CAM_PopUp_Req "Built-in Cam Operating and SD Card related Popup Request on HU Display.";
CM_ SG_ 171 BLTN_CAM_File_List_Renew "The Storage information is renewed inform to HU.";
CM_ SG_ 171 BLTN_CAM_Wifi_Pwd_Chg_State "The Response, when HU change Wifi Passowrd via SOME/IP";
CM_ BO_ 2231452929 "[P] Periodic";
CM_ SG_ 2231452929 DATC_Crc1Val "DATC_CyclicRedundancyCheck1Value";
CM_ SG_ 2231452929 DATC_AlvCnt1Val "DATC_AliveCounter1Value";
CM_ SG_ 2231452929 DATC_PtcRlySta "DATC_PtcRelayStatus";
CM_ SG_ 2231452929 DATC_ManufacturerTyp "DATC_ManufacturerType";
CM_ SG_ 2231452929 DATC_DatcPwmSts "Status of E-comp";
CM_ SG_ 2231452929 DATC_AcnCompTyp "DATC_AirconCompressorType";
CM_ SG_ 2231452929 DATC_EewpRpmLvlReq "DATC_EewpRpmlevelReq";
CM_ SG_ 2231452929 DATC_Cooldown "Complete of cooldown";
CM_ SG_ 2231452929 DATC_AcnReq "DATC_AirconRequest";
CM_ SG_ 2231452929 DATC_BlwSta "DATC_BlowerStatus";
CM_ SG_ 2231452929 DATC_BlwMaxSta "DATC_BlowerMaxStatus";
CM_ SG_ 2231452929 DATC_EngStrtReq "DATC_EngineStartRequest";
CM_ SG_ 2231452929 DATC_IsgInhbtReq "DATC_IsgInhibitRequset";
CM_ SG_ 2231452929 DATC_AcnCompOnReq "DATC_AirconCompressorOnRequest";
CM_ SG_ 2231452929 DATC_SrvLmpReq "DATC_ServiceLampRequest";
CM_ SG_ 2231452929 DATC_EcvFltSta "DATC_EcvFaultStatus";
CM_ SG_ 2231452929 DATC_CalcAcnCompTqVal "DATC_CalculatedAirconCompressortorqueValue";
CM_ BO_ 2231452930 "[P] Periodic";
CM_ SG_ 2231452930 DATC_AcnECompOpSta "DATC_AirconElectricCompressorOperationStatus";
CM_ SG_ 2231452930 DATC_HVCompIntlkSta "DATC_HighVoltageCompressorInterlockStatus";
CM_ SG_ 2231452930 DATC_HVIntDischrgLkReq "DATC_HighVoltageInterlockDischargeRequest";
CM_ SG_ 2231452930 DATC_AcnECompMaxReqPwrVal "DATC_AirconElectricalCompressorMaximumRequestPowerValue";
CM_ SG_ 2231452930 DATC_AcnCompFltSta "DATC_AirconElectricCompressorFaultStatus";
CM_ SG_ 2231452930 DATC_AcnECompCnsmptPwrVal "DATC_AirconElectricalCompressorConsumptionPowerValue";
CM_ SG_ 2231452930 DATC_MainRlyOffReq "DATC_MainRelayoffRequest";
CM_ SG_ 2231452930 DATC_MixDfgSelSta "DATC_MixDefogSelectStatus";
CM_ SG_ 2231452930 DATC_BattChlrVlvSta "Battery chiller valve status";
CM_ SG_ 2231452930 DATC_WaterPmpOnReq "DATC_WaterPumpOnRequest";
CM_ SG_ 2231452930 DATC_AcnECompSpdVal "DATC_AirconElectricalCompressorSpeedValue";
CM_ SG_ 2231452930 DATC_AcnCompSlpModCodVal "DATC_AirconCompressorSleepModeCodeValue";
CM_ SG_ 2231452930 DATC_RrDfgOpSta "DATC_RearDefogOperatingState";
CM_ SG_ 2231452930 DATC_AcnECompCANFltSta "DATC_AirconElectricalCompressorCANFaultStatus";
CM_ BO_ 2231452931 "[P] Periodic";
CM_ SG_ 2231452931 DATC_AcnCompWaitCodVal "DATC_AirconCompressorWaitCode";
CM_ SG_ 2231452931 DATC_PeEwpRPMReq "DATC_PeEwpRpmRequest";
CM_ SG_ 2231452931 DATC_AEwpSpdRpmReq "DATC_AsistenceEwpSpeedRpmRequest";
CM_ SG_ 2231452931 DATC_RadFanReq_Duty "This signal indicates Request cooling fan speed to cool HVAC System (Duty)";
CM_ SG_ 2231452931 DATC_OutTempSnsrVal "DATC_OutsideTemperatureSensorValue";
CM_ SG_ 2231452931 DATC_ActvEco "DATC_ActiveEco";
CM_ SG_ 2231452931 DATC_AUTOActv "DATCAutoActivation";
CM_ SG_ 2231452931 DATC_DfgSw "DATC_DefogSwitch";
CM_ SG_ 2231452931 DATC_BattChlrVlv_FltCode "Battery Chiller Filt Code";
CM_ SG_ 2231452931 DATC_BattEvapVlvSta "BATTERY COOL V/V (EVAP) STATUS";
CM_ SG_ 2231452931 DATC_BattEvapVlv_FltCode "BATTERY COOL V/V (EVAP) FltCode";
CM_ SG_ 2231452931 DATC_Wrmup "Complete of warmup";
CM_ SG_ 2231452931 DATC_SSC_EngStrtReq "Engine start request in SSC state";
CM_ SG_ 2231452931 DATC_AcnCompSta "DATC_AirconCompressorStatus";
CM_ BO_ 2231452932 "[P] Periodic";
CM_ SG_ 2231452932 DATC_SSC_InhbtReq "Request to EMS not to enter SSC";
CM_ SG_ 2231452932 DATC_EngIdlRpmUpReq "DATC_EngineIdleRpmUpRequest";
CM_ SG_ 2231452932 DATC_MaxBlwVolt "DATC_MaxBlowerVoltage";
CM_ SG_ 2231452932 DATC_HVACPmpOpSta "HVAC Pump Operation Status";
CM_ SG_ 2231452932 DATC_MildWrmup "Mild Warmup State";
CM_ SG_ 2231452932 DATC_BattEwpOpReq "Battery EWP Operating Request";
CM_ BO_ 2382594561 "[PE] Periodic and On Event";
CM_ SG_ 2382594561 DATC_Crc5Val "DATC_CyclicRedundancyCheck5Value";
CM_ SG_ 2382594561 DATC_AlvCnt5Val "DATC_AliveCounter5Value";
CM_ SG_ 2382594561 DATC_FrDrvModDis "DATC_FrontDriverModeDisplay";
CM_ SG_ 2382594561 DATC_FrPassModDis "DATC_FrontPassengerModeDisplay";
CM_ SG_ 2382594561 DATC_ClmtTxtPopupOSD "Climate Text Pop-up OSD";
CM_ SG_ 2382594561 DATC_TempDispUnitSta "DATC_TemperatureDiplayUnitStatus";
CM_ SG_ 2382594561 DATC_DrvAutoDis "DATC_DriverAutoDisplay";
CM_ SG_ 2382594561 DATC_FrChgReqDis "DATC_FrontChangeRequestDisplay";
CM_ SG_ 2382594561 DATC_FrClmtScrnDis "DATC_FrontClimateScreenDisplay";
CM_ SG_ 2382594561 DATC_AcDis "DATC_ACDisplay";
CM_ SG_ 2382594561 DATC_IntakeSta "DATC_IntakeStatus";
CM_ SG_ 2382594561 DATC_TempDrLvl "Level of temp door";
CM_ SG_ 2382594561 DATC_BattCompPwrCnsmptn_W "This signal indicates consumption power by e-compressor for battery";
CM_ BO_ 2424580353 "[PE] Periodic and On Event";
CM_ SG_ 2424580353 DATC_Crc12Val "DATC_CyclicRedundancyCheck12Value";
CM_ SG_ 2424580353 DATC_AlvCnt12Val "DATC_AliveCounter12Value";
CM_ SG_ 2424580353 DATC_StrWhlHtrSwReq "DATC_SteeringWheelHeaterSwitchRequest";
CM_ SG_ 2424580353 DATC_FRStHtrSwReq "DATC_FrontRightSeatHeaterSwitchRequest";
CM_ SG_ 2424580353 DATC_FRStVentSwReq "DATC_FrontRightSeatVentilationSwitchRequest";
CM_ SG_ 2424580353 DATC_RrDefSw "Rear Defog Switch";
CM_ SG_ 2424580353 DATC_FLStOpReq "DATC_FrontLeftSeatOperationRequest";
CM_ SG_ 2424580353 DATC_FRStOpReq "DATC_FrontRightSeatOperationRequest";
CM_ SG_ 2424580353 DATC_FLStHtrSwReq "DATC_FrontLeftSeatHeaterSwitchRequest";
CM_ SG_ 2424580353 DATC_FLStVentSwReq "DATC_FrontLefttSeatVentilationSwitchRequest";
CM_ SG_ 2424580353 DATC_FLStTmblrSwReq "DATC_FrontLefttSeatTumblerSwitchRequest";
CM_ SG_ 2424580353 DATC_FRStTmblrSwReq "DATC_FrontRightSeatTumblerSwitchRequest";
CM_ SG_ 2424580353 DATC_RRStHtrSwReq "DATC_RearRightSeatHeaterSwitchRequest";
CM_ SG_ 2424580353 DATC_RRStVentSwReq "DATC_RearRightSeatVentilationSwitchRequest";
CM_ SG_ 2424580353 DATC_RLStHtrSwReq "DATC_RearLeftSeatHeaterSwitchRequest";
CM_ SG_ 2424580353 DATC_RLStVentSwReq "DATC_RearLefttSeatVentilationSwitchRequest";
CM_ SG_ 2424580353 DATC_WdwClsReq "DATC_WindowCloseRequest";
CM_ SG_ 2424580353 DATC_RRSyncDis "DATC_RRSyncDisplay";
CM_ BO_ 649 "[EC] On Event and On Change";
CM_ SG_ 649 DLBCU_SmartCtrl_1h "½º¸¶Æ® ÀÚ¼¼Á¦¾î DLBCU ¿¬µ¿ Á¶Àý¿¡ µû¸¥ °³¼±ÇöÈ² AVN Ç¥½Ã¹®±¸_1½Ã°£";
CM_ SG_ 649 DLBCU_SmartCtrl_2h "½º¸¶Æ® ÀÚ¼¼Á¦¾î DLBCU ¿¬µ¿ Á¶Àý¿¡ µû¸¥ °³¼±ÇöÈ² AVN Ç¥½Ã ¹®±¸_2½Ã°£";
CM_ SG_ 649 DLBCU_SmartCtrl_Status "½º¸¶Æ® ÀÚ¼¼Á¦¾î 2´Ü°è DLBCU ¿¬µ¿ Á¶Àý µ¿ÀÛ ½ÃÀÛ / Á¾·á / Áß´Ü AVN ÆË¾÷";
CM_ BO_ 2176872452 "[P] Periodic";
CM_ BO_ 172 "[EC] On Event and On Change";
CM_ SG_ 172 BLTN_CAM_FR_VerPos_NvalueSet "Front Camera Vertical position setting value.";
CM_ SG_ 172 BLTN_CAM_AppNoti_PEV_NvalueSet "Parked Event notification to Connectivity Phone App. On/Off";
CM_ SG_ 172 BLTN_CAM_WiFi_AutoOn_NvalueSet "Wifi On/Off User setting";
CM_ SG_ 172 BLTN_CAM_StoProp_NvalueSet "Propotion of built-in Cam SD card Propotion set of the Recording Categories";
CM_ SG_ 172 CF_AVN_BLTN_CAM_USMReset "Buit-in Cam USM Reset Request.";
CM_ SG_ 172 CF_AVN_BLTN_CAM_RecReset "Buit-in Cam format(all file delete/Reset) Request.";
CM_ SG_ 172 BLTN_CAM_File_DEL_CPY_Cmd "Buit-in Cam operation control of copying and deleting.";
CM_ SG_ 172 BLTN_CAM_LVDS_Mode_Cmd "This Signal is for LVDS output commend to BLTN_CAM";
CM_ SG_ 172 HU_BLTN_CAM_Disp_Touch_Pos_X "X position of touch of display when BLTN-in CAM Engineer mode in";
CM_ SG_ 172 HU_BLTN_CAM_Disp_Touch_Pos_Y "Y position of touch of display when BLTN-in CAM Engineer mode in";
CM_ SG_ 172 BLTN_CAM_RR_VerPos_NvalueSet "Rear Camera Vertical position setting value.";
CM_ BO_ 1264 "[PE] Periodic and On Event";
CM_ SG_ 1264 HU_TimeSetting "Information for current time setting";
CM_ SG_ 1264 HU_DisplayMinute "Information for time display in Minute unit";
CM_ SG_ 1264 HU_Status "Information for H/U status
Transmitted on H/U status changing";
CM_ SG_ 1264 HU_DisplaySecond "Information for time display in Second unit";
CM_ SG_ 1264 HU_DisplayMonth "Information for Month";
CM_ SG_ 1264 HU_DisplayYear1 "Information for Year (XXOO)
XX : HU_DisplayYear1
OO: HU_DisplayYear2";
CM_ SG_ 1264 HU_DisplayYear2 "Information for Year (XXOO)
XX : HU_DisplayYear1
OO: HU_DisplayYear2";
CM_ SG_ 1264 HU_DisplayDay "Information for Day";
CM_ SG_ 1264 HU_AM_PM_INFO "Information for AM/PM";
CM_ SG_ 1264 HU_TimeFormat "Information for time format
Digital CLOCK only";
CM_ SG_ 1264 HU_DisplayHour "Information for time display in Hour unit";
CM_ BO_ 1266 "[PE] Periodic and On Event";
CM_ SG_ 1266 HU_LanguageInfo "Information for System Language (for Display Font)";
CM_ SG_ 1266 HU_MuteStatus "Information for System Mute Display";
CM_ SG_ 1266 HU_WelcomeReady "HU playback ready signal to play welcome animation video";
CM_ SG_ 1266 HU_UsmSupport "Information whether HU can support USM or not";
CM_ SG_ 1266 HU_NaviStatus "Information for Navigation Status (Booting, Normal Operation, No SD card)
-AVN NAVI Transmission Signal";
CM_ SG_ 1266 HU_NaviDisp "Information for Navi Display status on Front Monitor";
CM_ SG_ 1266 HU_BVM_Display_Message "BVM Operation Message";
CM_ SG_ 1266 HU_SVM_View_Display "BVM View display to cluster";
CM_ SG_ 1266 HU_NaviCamSettingStatus "Information for Navi Camera alert setting status

+ Bit-coded field (On 1, Off 0)
   - bit 0 : Fixed Camera
   - bit 1 : Signal/Speed Violation Camera
   - bit 2 : Movable Camera
   - bit 3 : User Registration Fixed Camera
   - bit 4 : User Registration Signal/Speed Violation Camera
   - bit 5~6 : Reserved
-AVN NAVI Transmission Signal";
CM_ SG_ 1266 HU_EVSupport "Notification whether EV function support or not.";
CM_ SG_ 1266 HU_AutoBrightState_New "HU Display Brightness State(When automatically adjusted)";
CM_ SG_ 1266 HU_VolumeStatus "Information for AVN Volume";
CM_ BO_ 1267 "[PE] Periodic and On Event";
CM_ SG_ 1267 RSELockOnOff "Command for RSE Lock Requst from Head Unit";
CM_ SG_ 1267 HU_DATC_RearLockSet "This signal is rear DATC(MTC) lock siganl when no RRC option";
CM_ SG_ 1267 HU_Graphreset_Info "Command for Hybrid Vehicle Fuel Economy Graph Reset Information
-Transmitting to Cluster when drivers agree 'Graph Reset'
-Keep the Value of Avergae Fuel Consumption and Line on the Graph";
CM_ SG_ 1267 HU_PhoneActivity "Information for Acitivity of Phone Call (For All area)";
CM_ SG_ 1267 HU_VRActivity "Information for Acitivity of VR (For All area)";
CM_ SG_ 1267 HU_DATC_AirQuality_Info "AirQuality Information";
CM_ BO_ 1240 "[PE] Periodic and On Event";
CM_ SG_ 1240 HU_DistanceUnit "Request to set CLU Distance Unit";
CM_ SG_ 1240 HU_MicActivity "HU send this signal to eCall for MIC using status.
eCall unit stop the diagonosis when received 0x1:Activated from HU
Otherwise, eCall unit keep diagnosis every 1 sec. and HU can not use MIC";
CM_ SG_ 1240 CF_HU_GPSFlt "Information of GPS Fault 

0x0: Normal
0x1 : Fault operation
0x2 : Reserved
0x3:Invalid";
CM_ SG_ 1240 AVN_RSPA_CancelInput "Request Signal to cancel RSPA function";
CM_ SG_ 1240 AVN_RSPA_Disp_Rdy "Signal to inform RSPA of AVN's display ready status
(RSPA È­¸é Ç¥½Ã °¡´É/ºÒ°¡´É »óÅÂ¸¦ ¾Ë¸®±â À§ÇÑ ½ÅÈ£)";
CM_ SG_ 1240 CF_AVN_ProfileIDRValue "This signal is User ID value in H/Unit.";
CM_ SG_ 1240 HazardFromHUSVM "This signal is for Hazard control";
CM_ SG_ 1240 OMUOSMirCtrl "This signal is for the OutSide Mirror Control (Fold or Unfold)";
CM_ SG_ 1240 OTAUIStatus "Information of the status of Head Unit";
CM_ SG_ 1240 C_TeleActiveStatus "This signal is for check TMS active status";
CM_ SG_ 1240 HU_AliveStatus "Information of the status of Head Unit
0x00 : Headunit is booting so, Headunit cant display any state
0x01 : Headunit is normal state, Headunit could display according to MM CAN  command.
0x02 : Headunit is doing their internal process, so Headunit cant communicate with other node.
For CLU/SCC/eCall
-AVN System transmission signal";
CM_ SG_ 1240 HU_RTCCheck "Checking whether RTC of AVN and HCU is operationg normally.";
CM_ BO_ 1265 "[PE] Periodic and On Event";
CM_ SG_ 1265 HU_IG3_Request "IG3 wake up and sleep request for EV/PHEV";
CM_ SG_ 1265 HU_Background "HU Backgound image info";
CM_ SG_ 1265 ccIC_HUD_PbackSta "Status signal for HUD interoperation with IMS";
CM_ SG_ 1265 HU_BackgroundFadeInOut "HU Background Fade in/out info - (HEX * Factor) %";
CM_ BO_ 1247 "[PE] Periodic and On Event";
CM_ SG_ 1247 Navi_ParkingLot "Parking Lot Information";
CM_ SG_ 1247 Navi_AirConditionWarning "this signal describe the circumstance and window state.";
CM_ SG_ 1247 Navi_AirConditionType "bit1 : Odour(On : 1, Off : 0)
bit2 : Tunnel(On : 1, Off : 0)
bit3 ~ 5 : Reserved";
CM_ BO_ 1251 "[EC] On Event and On Change";
CM_ BO_ 2172675329 "[P] Periodic";
CM_ SG_ 2172675329 IEB_Crc1Val "IEB_CyclicRedundancyCheck1Value";
CM_ SG_ 2172675329 IEB_AlvCnt1Val "IEB_AliveCounter1Value";
CM_ SG_ 2172675329 IEB_SrvLmpDis "IEB_ServiceLampDisplay ##2G##ESC - AHB1 - CF_Ahb_SLmp";
CM_ SG_ 2172675329 IEB_DfctvSta "IEB_DefectiveStatus ##2G##ESC - AHB1 - CF_Ahb_Def";
CM_ SG_ 2172675329 IEB_ActvSta "IEB_ActiveStatus ##2G##ESC - AHB1 - CF_Ahb_Act";
CM_ SG_ 2172675329 IEB_DiagSta "IEB_DiagnosticStatus ##2G##ESC - AHB1 - CF_Ahb_Diag";
CM_ SG_ 2172675329 IEB_WrngLmpDis "IEB_WarningLampDisplay ##2G##ESC - AHB1 - CF_Ahb_WLmp";
CM_ SG_ 2172675329 IEB_MILReq "MIL Requeset";
CM_ SG_ 2172675329 IEB_StrkDpthmmVal "IEB_StrokeDepthmmValue ##2G##ESC - AHB1 - CR_Ahb_StDep_mm";
CM_ SG_ 2172675329 IEB_BrkActvSta "IEB_BrakeActiveStatus ##2G##ESC - AHB1 - CF_Esc_BrakeAct";
CM_ SG_ 2172675329 IEB_PdlTrvlSnsrFailSta "IEB_PedalTravelSensorFailStatus ##2G##ESC - AHB1 - CF_Ahb_SnsFail";
CM_ SG_ 2172675329 IEB_PdlCalibSta "IEB_PedalCalibrationStatus ##2G##ESC - AHB1 - CF_Ahb_PedalCalStat";
CM_ SG_ 2172675329 IEB_BzrSta "IEB_BuzzerStatus ##2G##ESC - AHB1 - CF_Ahb_Bzzr";
CM_ BO_ 2172675330 "[P] Periodic";
CM_ SG_ 2172675330 IEB_Sta "IEB_Status ##2G##ESC - EBS1 - CF_Brk_EBSStat";
CM_ SG_ 2172675330 IEB_SnsrFailSta "IEB_SensorFailStatus ##2G##ESC - EBS1 - CF_Brk_SnsFail";
CM_ SG_ 2172675330 IEB_EstTtlBrkFrcNmVal "IEB_EstimatedTotalBrakeForceValue ##2G##ESC - EBS1 - CR_Brk_EstTot_Nm";
CM_ SG_ 2172675330 IEB_RbsWrngLmpSta "IEB_RbsWarningLamp ##2G##ESC - EBS1 - CF_Brk_RBSWLamp";
CM_ SG_ 2172675330 IEB_StrkDpthPcVal "IEB_StrokeDepthPcValue ##2G##ESC - EBS2 - CR_Brk_StkDep_Pc";
CM_ SG_ 2172675330 IEB_EstDpthPcVal "IEB_EstimatedPedalDepthValue ##2G##ESC - EBS2 - CR_Brk_Est_StkDep_Pc";
CM_ SG_ 2172675330 IEB_AbsNGearReq "IEB_AbsNGearRequest ##2G##ESC - TCS11 - CF_Brk_AbsNReq";
CM_ SG_ 2172675330 IEB_EstBrkPdlValVldSta "IEB_EstimatedBrakePedalValueValidityStatus ##2G##ESC - EBS2 - CF_Brk_Est_StkValid";
CM_ SG_ 2172675330 IEB_VacSysDfctvSta "IEB_VacuumSystemDefectiveStatus ##2G##ESC - EBS1 - CF_Brk_VacuumSysDef";
CM_ SG_ 2172675330 IEB_RegenTqLimitNmVal_Frnt "IEB_RegenTorqueLimitValue ##2G##ESC - EBS1 - CR_Brk_RegenTqLimit_Nm";
CM_ BO_ 2172675331 "[P] Periodic";
CM_ SG_ 2172675331 IEB_RegenTqLimitNmVal_Rear "IEB_RegenTorqueLimitValue Rear";
CM_ SG_ 2172675331 IEB_DrvWhlSlipFlg_Frnt "Slip status of driving wheel ##2G##ESC ? EBS2 ? CF_Brk_DrvWhlSlipFlg";
CM_ SG_ 2172675331 IEB_TCS_Req "IEB_TCS_Request";
CM_ SG_ 2172675331 IEB_RSC_Req "IEB_RSC_Request";
CM_ SG_ 2172675331 TCS_TqFlag_Frnt "TCS_TorqueFlag_Front";
CM_ SG_ 2172675331 TCS_TqFlag_Rear "TCS_TorqueFlag_Rear";
CM_ SG_ 2172675331 RSC_TqFlag_Frnt "RSC_TorqueFlag_Front";
CM_ SG_ 2172675331 RSC_TqFlag_Rear "RSC_TorqueFlag_Rear";
CM_ SG_ 2172675331 TCS_TqIntrvntnVal_Frnt "TCS_TorqueInterventionValue_Front";
CM_ SG_ 2172675331 TCS_TqIntrvntnVal_Rear "TCS_TorqueInterventionValue_Rear";
CM_ SG_ 2172675331 RSC_TqIntrvntnVal_Frnt "RSC_TorqueInterventionValue_Front";
CM_ SG_ 2172675331 RSC_TqIntrvntnVal_Rear "RSC_TorqueInterventionValue_Rear";
CM_ BO_ 2172675332 "[P] Periodic";
CM_ SG_ 2172675332 TCS_MtrTrgtRpm_Flag_Frnt "TCS_MotorTargetRPM_Flag_Front";
CM_ SG_ 2172675332 TCS_MtrTrgtRpm_Flag_Rear "TCS_MotorTargetRPM_Flag_Rear";
CM_ SG_ 2172675332 TCS_MtrTrgtRpm_Rear "TCS_MotorTargetRPM_Rear";
CM_ SG_ 2172675332 IEB_DriftModeSta "Display";
CM_ SG_ 2172675332 IEB_DriftModeActSta "ON/OFF status, Symbol";
CM_ SG_ 2172675332 IEB_EstBrkSacFrcNmVal "Estimated brake force value for stop assist control";
CM_ SG_ 2172675332 TCS_MtrTrgtRpm_Frnt "TCS_MotorTargetRPM_Front";
CM_ BO_ 1252 "[EC] On Event and On Change";
CM_ SG_ 1252 RKE_Crc1Val "RKE_CyclicRedundancyCheck1Value";
CM_ SG_ 1252 RKE_AlvCnt1Val "RKE_AliveCounter1Value";
CM_ SG_ 1252 RKE_BtnReq "RemoteKey_ButtonRequest ##2G##BCM - BCMmsg01 - C_RKECmd";
CM_ SG_ 1252 RKE_PsdBtnReq "RemoteKey_PowerSlindingDoorButtonRequest ##2G##BCM - BCMmsg01 - C_RKEPSDCmd";
CM_ SG_ 1252 RKE_WdwUpDnReq "RemoteKey_WindowUpDownRequest ##2G##BCM - BCMmsg01 - C_WdwComfortCMDBCM";
CM_ SG_ 1252 RKE_TrnkTlgtBtnReq "RemoteKey_Trunk/TailgateButtonRequest ##2G##BCM - BCMmsg01 - C_TailgateTrunkRKECMD";
CM_ SG_ 1252 RKE_ID "RemoteKey_ID ##2G##BCM - BCMmsg01 - C_BCMRKEID";
CM_ BO_ 191 "[PE] Periodic and On Event";
CM_ SG_ 191 RL_SHVU_DTCdisplay "0x00: DTC is not exist(Fail is not exist)/0x01:IGN2 Fuse Open Detection/0x02:Switch Input Detection at Same Time/0x03:NTC/Heating wire Open Detection/0x04:NTC+/NTC- Terminal Short Detection/0x05:NTC+/Heater+ Terminal Short Detection/0x06:NTC+/Heater-, Heater+/Heater-, Heater+/NTC- Terminal Short Detection/0x07:NTC+/Heater- Wiring Short Detection/0x08:NTC+/Heater-, Heater+/Heater-, Heater+/NTC- Wiring Short Detection/0x09:Target Temperature Dissatisfied/0x0A:Blower+/Blower- Short, Blower+/Blower Speed, Blower-/Blower Speed Wiring Short Detection/0x0B:Blower+/Blower RPM, Blower-/Blower RPM, Blower Speed/Blower RPM Short Detection/0x0C:Blower+, Blower-, Blower Speed Signal open Detection/0x0D:Blower RPM signal Open Detection/0x0E~0xFD:Unused/0xFE:No Display/0xFF:Invalid";
CM_ SG_ 191 RL_SHVU_DiagMode "0x0:Default/0x1:DTC Mode/0x2:Normal Mode/0x3:Invalid";
CM_ BO_ 2328016132 "[P] Periodic";
CM_ SG_ 2328016132 VCU_LowSocDispPcVal "VCU_LowSocDisplayPercentValue";
CM_ SG_ 2328016132 VCU_DteSocBasedVal "VCU_DteSocBasedValue";
CM_ SG_ 2328016132 VCU_InstFuelEcoVal_Per100km "VCU_InstantFuelEconomy(kWh/100km) ##2G##VCU - VCU5 - CR_Vcu_FuelEco_KP100km";
CM_ SG_ 2328016132 VCU_InstFuelEcoVal_PerkWh "VCU_InstantFuelEconomyValue_(km/kWh) ##2G##VCU - VCU5 - CR_Vcu_FuelEco_KPK";
CM_ SG_ 2328016132 VCU_CO2RdcTripDistVal "VCU_CO2ReductionTripDistanceValue ##2G##VCU - VCU4 - CF_Vcu_CO2RdcTripDist";
CM_ SG_ 2328016132 VCU_CO2RdcVal "VCU_CO2ReductionValue ##2G##VCU - VCU4 - CF_Vcu_CO2Rdc";
CM_ SG_ 2328016132 VCU_StopCtrlWarnMsgSta "i-Pedal Warning Message Status";
CM_ SG_ 2328016132 VCU_DrvModeDefault "Drive Mode(Default Mode) Value for Cluster Display(EV)";
CM_ SG_ 2328016132 VCU_DrvModeLast "This signal is the drive mode that needs to maintain on restart";
BA_DEF_ BO_ "DiagState" ENUM "No","Yes" ;
BA_DEF_ BO_ "DiagResponse" ENUM "No","Yes" ;
BA_DEF_ BO_ "DiagRequest" ENUM "No","Yes" ;
BA_DEF_ BO_ "TpMessage" ENUM "No","Yes" ;
BA_DEF_ BO_ "UsrMsgIDSforwardDeviation" INT 0 100 ;
BA_DEF_ BO_ "UsrMsgIDSbackwardDeviation" INT 50 1000 ;
BA_DEF_ BO_ "GenMsgCycleTime" INT 0 2000 ;
BA_DEF_ BO_ "GenMsgStartDelayTime" INT 0 2000 ;
BA_DEF_ BO_ "GenMsgSendType" ENUM "Cyclic","NoMsgSendType" ;
BA_DEF_ BO_ "GenMsgCycleTimeFast" INT 0 500 ;
BA_DEF_ BO_ "GenMsgDelayTime" INT 0 20 ;
BA_DEF_ BO_ "GenMsgILSupport" ENUM "No","Yes" ;
BA_DEF_ BO_ "GenMsgNrOfRepetition" INT 0 3 ;
BA_DEF_ BO_ "NmMessage" ENUM "No","Yes" ;
BA_DEF_ BO_ "NWM-Botschaft" ENUM "No","Yes" ;
BA_DEF_ BO_ "TpTxIndex" INT 0 255 ;
BA_DEF_ BO_ "VFrameFormat" ENUM "StandardCAN","ExtendedCAN","reserved","reserved","reserved","reserved","reserved","reserved","reserved","reserved","reserved","reserved","reserved","reserved","StandardCAN_FD","ExtendedCAN_FD" ;
BA_DEF_ SG_ "UserSigValidity" ENUM "B+","ACC","IG","IG1","IG2","IG3","IG1 or IG2","IG1 or IG3","Undef" ;
BA_DEF_ SG_ "TimeoutValue" STRING ;
BA_DEF_ SG_ "UsrSigPurpose" ENUM "Undef","FN","DIAG","DIAG(Req)","DIAG(Res)","DIAG(Phy)","DEV","CCP(Req)","CCP(Res)","NM","TP" ;
BA_DEF_ SG_ "GenSigStartValue" INT 0 1215752192 ;
BA_DEF_ SG_ "NetworkRequest" ENUM "Yes","No" ;
BA_DEF_ SG_ "NetworkRequestHoldingTime" INT 0 65535 ;
BA_DEF_ SG_ "Description" STRING ;
BA_DEF_ SG_ "Version" STRING ;
BA_DEF_ SG_ "GenSigEnvVarType" ENUM "Int","Float","Undef" ;
BA_DEF_ SG_ "GenSigSendType" ENUM "Cyclic","OnWrite","OnWriteWithRepetition","OnChange","OnChangeWithRepetition","IfActive","IfActiveWithRepetition","NoSigSendType","OnChangeAndIfActive","OnChangeAndIfActiveWithRepetition" ;
BA_DEF_ SG_ "GwSigLatencyTime" INT 0 65536 ;
BA_DEF_ SG_ "GwSigMissingSourceType" ENUM "Undef","OldValue","DefaultValue","InitialValue" ;
BA_DEF_ SG_ "NWM-WakeupAllowed" ENUM "<n.a.>" ;
BA_DEF_ SG_ "RoutingFactor" INT 1 1215752192 ;
BA_DEF_REL_ BU_SG_REL_ "GenSigTimeoutTime" INT 0 7000 ;
BA_DEF_DEF_ "DiagState" "No" ;
BA_DEF_DEF_ "DiagResponse" "No" ;
BA_DEF_DEF_ "DiagRequest" "No" ;
BA_DEF_DEF_ "TpMessage" "No" ;
BA_DEF_DEF_ "UsrMsgIDSforwardDeviation" 10 ;
BA_DEF_DEF_ "UsrMsgIDSbackwardDeviation" 100 ;
BA_DEF_DEF_ "GenMsgCycleTime" 200 ;
BA_DEF_DEF_ "GenMsgStartDelayTime" 0 ;
BA_DEF_DEF_ "GenMsgSendType" "NoMsgSendType" ;
BA_DEF_DEF_ "GenMsgCycleTimeFast" 40 ;
BA_DEF_DEF_ "GenMsgDelayTime" 20 ;
BA_DEF_DEF_ "GenMsgILSupport" "Yes" ;
BA_DEF_DEF_ "GenMsgNrOfRepetition" 3 ;
BA_DEF_DEF_ "NmMessage" "No" ;
BA_DEF_DEF_ "NWM-Botschaft" "No" ;
BA_DEF_DEF_ "TpTxIndex" 0 ;
BA_DEF_DEF_ "VFrameFormat" "StandardCAN" ;
BA_DEF_DEF_ "UserSigValidity" "IG" ;
BA_DEF_DEF_ "TimeoutValue" "" ;
BA_DEF_DEF_ "UsrSigPurpose" "FN" ;
BA_DEF_DEF_ "GenSigStartValue" 0 ;
BA_DEF_DEF_ "NetworkRequest" "No" ;
BA_DEF_DEF_ "NetworkRequestHoldingTime" 0 ;
BA_DEF_DEF_ "Description" "" ;
BA_DEF_DEF_ "Version" "" ;
BA_DEF_DEF_ "GenSigEnvVarType" "Undef" ;
BA_DEF_DEF_ "GenSigSendType" "NoSigSendType" ;
BA_DEF_DEF_ "GwSigLatencyTime" 40 ;
BA_DEF_DEF_ "GwSigMissingSourceType" "Undef" ;
BA_DEF_DEF_ "NWM-WakeupAllowed" "<n.a.>" ;
BA_DEF_DEF_ "RoutingFactor" 1 ;
BA_DEF_DEF_REL_ "GenSigTimeoutTime" 500 ;
BA_ "GenMsgCycleTime" BO_ 694 0;
BA_ "Description" SG_ 694 ASAU_NotFootMsgOperStaWarn "Passenger Foot Massage Operation Disable Mode";
BA_ "GenSigSendType" SG_ 694 ASAU_NotFootMsgOperStaWarn 4;
BA_ "UserSigValidity" SG_ 694 ASAU_NotFootMsgOperStaWarn 3;
BA_ "NetworkRequest" SG_ 694 ASAU_NotFootMsgOperStaWarn 0;
BA_ "NetworkRequestHoldingTime" SG_ 694 ASAU_NotFootMsgOperStaWarn 5000;
BA_ "RoutingFactor" SG_ 694 ASAU_NotFootMsgOperStaWarn 0;
BA_ "Version" SG_ 694 ASAU_NotFootMsgOperStaWarn "20.08.00";
BA_ "GenMsgCycleTime" BO_ 158 0;
BA_ "Description" SG_ 158 ATS_DATC_FrDrBlowerSet "Àü¼® ¿îÀü¼® Ãø ºí·Î¿ö ´Ü¼ö ¼³Á¤";
BA_ "GenSigSendType" SG_ 158 ATS_DATC_FrDrBlowerSet 4;
BA_ "GenSigStartValue" SG_ 158 ATS_DATC_FrDrBlowerSet 15;
BA_ "UserSigValidity" SG_ 158 ATS_DATC_FrDrBlowerSet 3;
BA_REL_ "GenSigTimeoutTime" BU_SG_REL_ CGW_CCU SG_ 158 ATS_DATC_FrDrBlowerSet 0;
BA_ "Version" SG_ 158 ATS_DATC_FrDrBlowerSet "19.12.08";
BA_ "Description" SG_ 158 ATS_DATC_RrDrTempUpDn "ÈÄ¼® ¿îÀü¼® Ãø ¼³Á¤¿Âµµ Áõ°¨ ¼³Á¤";
BA_ "GenSigSendType" SG_ 158 ATS_DATC_RrDrTempUpDn 4;
BA_ "UserSigValidity" SG_ 158 ATS_DATC_RrDrTempUpDn 3;
BA_REL_ "GenSigTimeoutTime" BU_SG_REL_ CGW_CCU SG_ 158 ATS_DATC_RrDrTempUpDn 0;
BA_ "Version" SG_ 158 ATS_DATC_RrDrTempUpDn "19.12.08";
BA_ "Description" SG_ 158 ATS_DATC_RrDrBlowerSet "ÈÄ¼® ¿îÀü¼® Ãø ºí·Î¿ö Áõ°¨ ¼³Á¤";
BA_ "GenSigSendType" SG_ 158 ATS_DATC_RrDrBlowerSet 4;
BA_ "GenSigStartValue" SG_ 158 ATS_DATC_RrDrBlowerSet 15;
BA_ "UserSigValidity" SG_ 158 ATS_DATC_RrDrBlowerSet 3;
BA_REL_ "GenSigTimeoutTime" BU_SG_REL_ CGW_CCU SG_ 158 ATS_DATC_RrDrBlowerSet 0;
BA_ "Version" SG_ 158 ATS_DATC_RrDrBlowerSet "19.12.08";
BA_ "Description" SG_ 158 ATS_DATC_RrDrModeSet "ÈÄ¼® ¿îÀü¼® Ãø ¸ðµå ¼³Á¤";
BA_ "GenSigSendType" SG_ 158 ATS_DATC_RrDrModeSet 4;
BA_ "GenSigStartValue" SG_ 158 ATS_DATC_RrDrModeSet 15;
BA_ "UserSigValidity" SG_ 158 ATS_DATC_RrDrModeSet 3;
BA_REL_ "GenSigTimeoutTime" BU_SG_REL_ CGW_CCU SG_ 158 ATS_DATC_RrDrModeSet 0;
BA_ "Version" SG_ 158 ATS_DATC_RrDrModeSet "19.12.08";
BA_ "Description" SG_ 158 ATS_DATC_FrDrModeSet "Àü¼® ¿îÀü¼® Ãø ¸ðµå ¼³Á¤";
BA_ "GenSigSendType" SG_ 158 ATS_DATC_FrDrModeSet 4;
BA_ "UserSigValidity" SG_ 158 ATS_DATC_FrDrModeSet 3;
BA_REL_ "GenSigTimeoutTime" BU_SG_REL_ CGW_CCU SG_ 158 ATS_DATC_FrDrModeSet 0;
BA_ "Version" SG_ 158 ATS_DATC_FrDrModeSet "19.12.08";
BA_ "Description" SG_ 158 ATS_DATC_RrOnOffSet "ÈÄ¼® °øÁ¶ ¿Â¿ÀÇÁ ¼³Á¤";
BA_ "GenSigSendType" SG_ 158 ATS_DATC_RrOnOffSet 4;
BA_ "GenSigStartValue" SG_ 158 ATS_DATC_RrOnOffSet 3;
BA_ "UserSigValidity" SG_ 158 ATS_DATC_RrOnOffSet 3;
BA_ "Version" SG_ 158 ATS_DATC_RrOnOffSet "19.12.08";
BA_ "Description" SG_ 158 ATS_DATC_IntakeSet "³»¿Ü±â ¼³Á¤";
BA_ "GenSigSendType" SG_ 158 ATS_DATC_IntakeSet 4;
BA_ "GenSigStartValue" SG_ 158 ATS_DATC_IntakeSet 3;
BA_ "UserSigValidity" SG_ 158 ATS_DATC_IntakeSet 3;
BA_REL_ "GenSigTimeoutTime" BU_SG_REL_ CGW_CCU SG_ 158 ATS_DATC_IntakeSet 0;
BA_ "Version" SG_ 158 ATS_DATC_IntakeSet "19.12.08";
BA_ "Description" SG_ 158 ATS_DATC_OffReq "Àü¼® °øÁ¶ ¿ÀÇÁ ¼³Á¤";
BA_ "GenSigSendType" SG_ 158 ATS_DATC_OffReq 4;
BA_ "UserSigValidity" SG_ 158 ATS_DATC_OffReq 3;
BA_ "Version" SG_ 158 ATS_DATC_OffReq "19.12.08";
BA_ "Description" SG_ 158 ATS_DATC_FrDrAutoSet "Àü¼® ¿îÀü¼® Ãø AUTO ¼³Á¤";
BA_ "GenSigSendType" SG_ 158 ATS_DATC_FrDrAutoSet 4;
BA_ "UserSigValidity" SG_ 158 ATS_DATC_FrDrAutoSet 3;
BA_REL_ "GenSigTimeoutTime" BU_SG_REL_ CGW_CCU SG_ 158 ATS_DATC_FrDrAutoSet 0;
BA_ "Version" SG_ 158 ATS_DATC_FrDrAutoSet "19.12.08";
BA_ "Description" SG_ 158 ATS_DATC_FrPsTempUpDn "Àü¼® Á¶¼ö¼® Ãø ¼³Á¤¿Âµµ Áõ°¨ ¼³Á¤";
BA_ "GenSigSendType" SG_ 158 ATS_DATC_FrPsTempUpDn 4;
BA_ "UserSigValidity" SG_ 158 ATS_DATC_FrPsTempUpDn 3;
BA_REL_ "GenSigTimeoutTime" BU_SG_REL_ CGW_CCU SG_ 158 ATS_DATC_FrPsTempUpDn 0;
BA_ "Version" SG_ 158 ATS_DATC_FrPsTempUpDn "19.12.08";
BA_ "Description" SG_ 158 ATS_DATC_FrDefog "Àü¼® DEF ¼³Á¤";
BA_ "GenSigSendType" SG_ 158 ATS_DATC_FrDefog 4;
BA_ "GenSigStartValue" SG_ 158 ATS_DATC_FrDefog 3;
BA_ "UserSigValidity" SG_ 158 ATS_DATC_FrDefog 3;
BA_REL_ "GenSigTimeoutTime" BU_SG_REL_ CGW_CCU SG_ 158 ATS_DATC_FrDefog 0;
BA_ "Version" SG_ 158 ATS_DATC_FrDefog "19.12.08";
BA_ "Description" SG_ 158 ATS_DATC_RrSyncSet "ÈÄ¼® SYNC ¼³Á¤";
BA_ "GenSigSendType" SG_ 158 ATS_DATC_RrSyncSet 4;
BA_ "UserSigValidity" SG_ 158 ATS_DATC_RrSyncSet 3;
BA_REL_ "GenSigTimeoutTime" BU_SG_REL_ CGW_CCU SG_ 158 ATS_DATC_RrSyncSet 0;
BA_ "Version" SG_ 158 ATS_DATC_RrSyncSet "19.12.08";
BA_ "Description" SG_ 158 ATS_DATC_AcSet "AC ¼³Á¤";
BA_ "GenSigSendType" SG_ 158 ATS_DATC_AcSet 4;
BA_ "GenSigStartValue" SG_ 158 ATS_DATC_AcSet 3;
BA_ "UserSigValidity" SG_ 158 ATS_DATC_AcSet 3;
BA_REL_ "GenSigTimeoutTime" BU_SG_REL_ CGW_CCU SG_ 158 ATS_DATC_AcSet 0;
BA_ "Version" SG_ 158 ATS_DATC_AcSet "19.12.08";
BA_ "Description" SG_ 158 ATS_DATC_AirCleaningSet "°ø±âÃ»Á¤¸ðµå ¼³Á¤";
BA_ "GenSigSendType" SG_ 158 ATS_DATC_AirCleaningSet 4;
BA_ "GenSigStartValue" SG_ 158 ATS_DATC_AirCleaningSet 3;
BA_ "UserSigValidity" SG_ 158 ATS_DATC_AirCleaningSet 3;
BA_REL_ "GenSigTimeoutTime" BU_SG_REL_ CGW_CCU SG_ 158 ATS_DATC_AirCleaningSet 0;
BA_ "Version" SG_ 158 ATS_DATC_AirCleaningSet "19.12.08";
BA_ "Description" SG_ 158 ATS_DATC_FrDrBlowerUpDn "Àü¼® ¿îÀü¼® Ãø ºí·Î¿ö Áõ°¨ ¼³Á¤";
BA_ "GenSigSendType" SG_ 158 ATS_DATC_FrDrBlowerUpDn 4;
BA_ "UserSigValidity" SG_ 158 ATS_DATC_FrDrBlowerUpDn 3;
BA_REL_ "GenSigTimeoutTime" BU_SG_REL_ CGW_CCU SG_ 158 ATS_DATC_FrDrBlowerUpDn 0;
BA_ "Version" SG_ 158 ATS_DATC_FrDrBlowerUpDn "19.12.08";
BA_ "Description" SG_ 158 ATS_DATC_FrDrTempUpDn "Àü¼® ¿îÀü¼® Ãø ¼³Á¤¿Âµµ Áõ°¨ ¼³Á¤";
BA_ "GenSigSendType" SG_ 158 ATS_DATC_FrDrTempUpDn 4;
BA_ "UserSigValidity" SG_ 158 ATS_DATC_FrDrTempUpDn 3;
BA_REL_ "GenSigTimeoutTime" BU_SG_REL_ CGW_CCU SG_ 158 ATS_DATC_FrDrTempUpDn 0;
BA_ "Version" SG_ 158 ATS_DATC_FrDrTempUpDn "19.12.08";
BA_ "Description" SG_ 158 ATS_DATC_RrDrAutoSet "ÈÄ¼® ¿îÀü¼® Ãø AUTO ¼³Á¤";
BA_ "GenSigSendType" SG_ 158 ATS_DATC_RrDrAutoSet 4;
BA_ "GenSigStartValue" SG_ 158 ATS_DATC_RrDrAutoSet 3;
BA_ "UserSigValidity" SG_ 158 ATS_DATC_RrDrAutoSet 3;
BA_REL_ "GenSigTimeoutTime" BU_SG_REL_ CGW_CCU SG_ 158 ATS_DATC_RrDrAutoSet 0;
BA_ "Version" SG_ 158 ATS_DATC_RrDrAutoSet "19.12.08";
BA_ "GenMsgCycleTime" BO_ 157 0;
BA_ "Description" SG_ 157 ATS_DATC_FrDrTempSetC "Àü¼® ¿îÀü¼® Ãø ¼³Á¤¿Âµµ°ª(¼·¾¾) ¼³Á¤";
BA_ "GenSigSendType" SG_ 157 ATS_DATC_FrDrTempSetC 4;
BA_ "GenSigStartValue" SG_ 157 ATS_DATC_FrDrTempSetC 255;
BA_ "UserSigValidity" SG_ 157 ATS_DATC_FrDrTempSetC 3;
BA_REL_ "GenSigTimeoutTime" BU_SG_REL_ CGW_CCU SG_ 157 ATS_DATC_FrDrTempSetC 0;
BA_ "Version" SG_ 157 ATS_DATC_FrDrTempSetC "19.12.08";
BA_ "Description" SG_ 157 ATS_DATC_RrDrBlowerUpDn "ÈÄ¼® ¿îÀü¼® Ãø ºí·Î¿ö Áõ°¨ ¼³Á¤";
BA_ "GenSigSendType" SG_ 157 ATS_DATC_RrDrBlowerUpDn 4;
BA_ "UserSigValidity" SG_ 157 ATS_DATC_RrDrBlowerUpDn 3;
BA_REL_ "GenSigTimeoutTime" BU_SG_REL_ CGW_CCU SG_ 157 ATS_DATC_RrDrBlowerUpDn 0;
BA_ "Version" SG_ 157 ATS_DATC_RrDrBlowerUpDn "19.12.08";
BA_ "Description" SG_ 157 ATS_DATC_FrSyncSet "Àü¼® SYNC ¼³Á¤";
BA_ "GenSigSendType" SG_ 157 ATS_DATC_FrSyncSet 4;
BA_ "UserSigValidity" SG_ 157 ATS_DATC_FrSyncSet 3;
BA_REL_ "GenSigTimeoutTime" BU_SG_REL_ CGW_CCU SG_ 157 ATS_DATC_FrSyncSet 0;
BA_ "Version" SG_ 157 ATS_DATC_FrSyncSet "19.12.08";
BA_ "Description" SG_ 157 ATS_DATC_RrDrTempSetC "ÈÄ¼® ¿îÀü¼® Ãø ¼³Á¤¿Âµµ°ª(¼·¾¾) ¼³Á¤";
BA_ "GenSigSendType" SG_ 157 ATS_DATC_RrDrTempSetC 4;
BA_ "GenSigStartValue" SG_ 157 ATS_DATC_RrDrTempSetC 255;
BA_ "UserSigValidity" SG_ 157 ATS_DATC_RrDrTempSetC 3;
BA_REL_ "GenSigTimeoutTime" BU_SG_REL_ CGW_CCU SG_ 157 ATS_DATC_RrDrTempSetC 0;
BA_ "Version" SG_ 157 ATS_DATC_RrDrTempSetC "19.12.08";
BA_ "Description" SG_ 157 ATS_DATC_RrDrTempSetF "ÈÄ¼® ¿îÀü¼® Ãø ¼³Á¤¿Âµµ°ª(È­¾¾) ¼³Á¤";
BA_ "GenSigSendType" SG_ 157 ATS_DATC_RrDrTempSetF 4;
BA_ "GenSigStartValue" SG_ 157 ATS_DATC_RrDrTempSetF 255;
BA_ "UserSigValidity" SG_ 157 ATS_DATC_RrDrTempSetF 3;
BA_REL_ "GenSigTimeoutTime" BU_SG_REL_ CGW_CCU SG_ 157 ATS_DATC_RrDrTempSetF 0;
BA_ "Version" SG_ 157 ATS_DATC_RrDrTempSetF "19.12.08";
BA_ "Description" SG_ 157 ATS_DATC_FrPsTempSetC "Àü¼® Á¶¼ö¼® Ãø ¼³Á¤¿Âµµ°ª(¼·¾¾) ¼³Á¤";
BA_ "GenSigSendType" SG_ 157 ATS_DATC_FrPsTempSetC 4;
BA_ "GenSigStartValue" SG_ 157 ATS_DATC_FrPsTempSetC 255;
BA_ "UserSigValidity" SG_ 157 ATS_DATC_FrPsTempSetC 3;
BA_REL_ "GenSigTimeoutTime" BU_SG_REL_ CGW_CCU SG_ 157 ATS_DATC_FrPsTempSetC 0;
BA_ "Version" SG_ 157 ATS_DATC_FrPsTempSetC "19.12.08";
BA_ "Description" SG_ 157 ATS_DATC_FrPsTempSetF "Àü¼® Á¶¼ö¼® Ãø ¼³Á¤¿Âµµ°ª(È­¾¾) ¼³Á¤";
BA_ "GenSigSendType" SG_ 157 ATS_DATC_FrPsTempSetF 4;
BA_ "GenSigStartValue" SG_ 157 ATS_DATC_FrPsTempSetF 255;
BA_ "UserSigValidity" SG_ 157 ATS_DATC_FrPsTempSetF 3;
BA_REL_ "GenSigTimeoutTime" BU_SG_REL_ CGW_CCU SG_ 157 ATS_DATC_FrPsTempSetF 0;
BA_ "Version" SG_ 157 ATS_DATC_FrPsTempSetF "19.12.08";
BA_ "Description" SG_ 157 ATS_DATC_FrDrTempSetF "Àü¼® ¿îÀü¼® Ãø ¼³Á¤¿Âµµ°ª(È­¾¾) ¼³Á¤";
BA_ "GenSigSendType" SG_ 157 ATS_DATC_FrDrTempSetF 4;
BA_ "GenSigStartValue" SG_ 157 ATS_DATC_FrDrTempSetF 255;
BA_ "UserSigValidity" SG_ 157 ATS_DATC_FrDrTempSetF 3;
BA_REL_ "GenSigTimeoutTime" BU_SG_REL_ CGW_CCU SG_ 157 ATS_DATC_FrDrTempSetF 0;
BA_ "Version" SG_ 157 ATS_DATC_FrDrTempSetF "19.12.08";
BA_ "GenMsgSendType" BO_ 2227254529 0;
BA_ "GenMsgCycleTime" BO_ 2227254529 50;
BA_ "GenMsgCycleTimeFast" BO_ 2227254529 0;
BA_ "GenMsgNrOfRepetition" BO_ 2227254529 0;
BA_ "VFrameFormat" BO_ 2227254529 1;
BA_ "Description" SG_ 2227254529 BAT_Crc1Val "The data area for CRC calculation is based on the data length (DLC) of the message DB.

The CRC shall be calculated over the entire data block (excluding the CRC bytes) including the user data, alive counter and Data ID

 

- CRC Polynomial (0x1021) , Initial Value : 0xFFFF, XOR value : 0x0000, Data ID : Message ID + 0xF800 

- The initial value is for CRC calculation and the message should be sent with the calculated result value. 

- The mathematical expression to 16 bit CRC polynomial is given here. G(x) = x16 + x12 + x5 + 1";
BA_ "GenSigStartValue" SG_ 2227254529 BAT_Crc1Val 65535;
BA_ "UserSigValidity" SG_ 2227254529 BAT_Crc1Val 7;
BA_ "RoutingFactor" SG_ 2227254529 BAT_Crc1Val 5;
BA_ "Version" SG_ 2227254529 BAT_Crc1Val "18.11.08";
BA_ "Description" SG_ 2227254529 BAT_AlvCnt1Val "For the first transmission request for a data element the counter shall be initialized with 0 and shall be incremented by 1 for every subsequent send request. 

When the counter reaches the maximum value(0xFF), then it shall restart with 0 for the next send request";
BA_ "UserSigValidity" SG_ 2227254529 BAT_AlvCnt1Val 7;
BA_ "RoutingFactor" SG_ 2227254529 BAT_AlvCnt1Val 5;
BA_ "Version" SG_ 2227254529 BAT_AlvCnt1Val "18.11.08";
BA_ "Description" SG_ 2227254529 BAT_CurrVal "[For 12V Lithium Battery vehicle model]

This is Battery current as measured by battery sensor.

This value is  

   - IRANGE : 1 (medium current)

   - Resolution : 10mA";
BA_ "GenSigStartValue" SG_ 2227254529 BAT_CurrVal 65535;
BA_ "UserSigValidity" SG_ 2227254529 BAT_CurrVal 7;
BA_ "RoutingFactor" SG_ 2227254529 BAT_CurrVal 5;
BA_ "Version" SG_ 2227254529 BAT_CurrVal "17.11.00";
BA_ "Description" SG_ 2227254529 BAT_SocVal "[For 12V Lithium Battery vehicle model]

This signal is battery State of Charge as calculated by battery sensor.";
BA_ "UserSigValidity" SG_ 2227254529 BAT_SocVal 7;
BA_ "RoutingFactor" SG_ 2227254529 BAT_SocVal 5;
BA_ "Version" SG_ 2227254529 BAT_SocVal "19.01.00";
BA_ "Description" SG_ 2227254529 BAT_VoltVal "[For 12V Lithium Battery vehicle model]

This is the actual battery voltage as measured on the battery pole by battery sensor.

The Resolution is 1mV.";
BA_ "GenSigStartValue" SG_ 2227254529 BAT_VoltVal 16383;
BA_ "UserSigValidity" SG_ 2227254529 BAT_VoltVal 7;
BA_ "RoutingFactor" SG_ 2227254529 BAT_VoltVal 5;
BA_ "Version" SG_ 2227254529 BAT_VoltVal "17.11.00";
BA_ "Description" SG_ 2227254529 BAT_AuxBattOpt "12V Battery Option Value(LFP 12V Battery)";
BA_ "UserSigValidity" SG_ 2227254529 BAT_AuxBattOpt 7;
BA_ "RoutingFactor" SG_ 2227254529 BAT_AuxBattOpt 5;
BA_ "Version" SG_ 2227254529 BAT_AuxBattOpt "21.10.05";
BA_ "GenMsgSendType" BO_ 2227254530 0;
BA_ "GenMsgCycleTime" BO_ 2227254530 50;
BA_ "GenMsgCycleTimeFast" BO_ 2227254530 0;
BA_ "GenMsgNrOfRepetition" BO_ 2227254530 0;
BA_ "VFrameFormat" BO_ 2227254530 1;
BA_ "Description" SG_ 2227254530 BAT_TempVal "This is actual battery electrolyte temperature value by battery sensor.

The value is calculated by a Battery Temperature Model, depending on measured temperature of the battery pole.

The resolution is 0.5¡É.";
BA_ "GenSigStartValue" SG_ 2227254530 BAT_TempVal 511;
BA_ "UserSigValidity" SG_ 2227254530 BAT_TempVal 7;
BA_ "RoutingFactor" SG_ 2227254530 BAT_TempVal 5;
BA_ "Version" SG_ 2227254530 BAT_TempVal "20.03.05";
BA_ "Description" SG_ 2227254530 BAT_SohVal "[For 12V Lithium Battery vehicle model]

This signal is battery State of Health(SOH) as calculated by battery sensor.

This value shows reduction rate of nominal capacity.

This value can be used for diagnosis information of application system.";
BA_ "GenSigStartValue" SG_ 2227254530 BAT_SohVal 127;
BA_ "UserSigValidity" SG_ 2227254530 BAT_SohVal 7;
BA_ "RoutingFactor" SG_ 2227254530 BAT_SohVal 5;
BA_ "Version" SG_ 2227254530 BAT_SohVal "17.11.00";
BA_ "Description" SG_ 2227254530 BAT_SnsrInvldSta "[For 12V Lithium Battery vehicle model]

This bit is Battery Sensor Invalid flag and setting condition is depending on Battery Sensor self diagnosis information.

 BS Invalid = 0 : BS is Valid Condition

 BS Invalid = 1 : BS is Invalid Condition";
BA_ "GenSigStartValue" SG_ 2227254530 BAT_SnsrInvldSta 1;
BA_ "UserSigValidity" SG_ 2227254530 BAT_SnsrInvldSta 7;
BA_ "RoutingFactor" SG_ 2227254530 BAT_SnsrInvldSta 5;
BA_ "Version" SG_ 2227254530 BAT_SnsrInvldSta "17.11.00";
BA_ "Description" SG_ 2227254530 BAT_SofVal "[For 12V Lithium Battery vehicle model]

This signal is battery State of Function(SOF) as calculated by battery sensor.

This value shows information about the battery ability to crank the engine (both of warm & cold cranking).

This value is prediction value of the minimum voltage for the next cranking.";
BA_ "GenSigStartValue" SG_ 2227254530 BAT_SofVal 127;
BA_ "UserSigValidity" SG_ 2227254530 BAT_SofVal 7;
BA_ "RoutingFactor" SG_ 2227254530 BAT_SofVal 5;
BA_ "Version" SG_ 2227254530 BAT_SofVal "17.11.00";
BA_ "Description" SG_ 2227254530 BAT_RspErrSta "[For 12V Lithium Battery vehicle model]

Battery Sensor shall send one status bit signal, Response_Error. Response_Error shall be set whenever a frame received by the node or a frame transmitted by the node contains an error in the response field.

Response_Error shall be cleared after transmission.

Based on this single bit the master node can conclude the following:

 -Response_Error = 0 : the node is operating correctly

 -Response_Error = 1 : the node has intermittent problems

 -The node did not answer : the node (or bus or master) has serious problems.";
BA_ "GenSigStartValue" SG_ 2227254530 BAT_RspErrSta 1;
BA_ "UserSigValidity" SG_ 2227254530 BAT_RspErrSta 7;
BA_ "RoutingFactor" SG_ 2227254530 BAT_RspErrSta 5;
BA_ "Version" SG_ 2227254530 BAT_RspErrSta "17.11.00";
BA_ "Description" SG_ 2227254530 BAT_CapacityVal "12V Battery Capacity Value";
BA_ "UserSigValidity" SG_ 2227254530 BAT_CapacityVal 7;
BA_ "RoutingFactor" SG_ 2227254530 BAT_CapacityVal 5;
BA_ "Version" SG_ 2227254530 BAT_CapacityVal "21.07.06";
BA_ "Description" SG_ 2227254530 BAT_SocErrSta "[For 12V Lithium Battery vehicle model]

This bit is flags for indication whether battery SOC detection value is plausible or not by battery sensor.

If it is set to value 0, then it means battery SOC is normal state.

If it is set to value 1, then it means battery SOC is implausible state.

 * Conditions to set value = 1

  1) There has no chance to recalibrate SOC after power on reset

  2) There has no SOC recalibration after last recalibration

  3) There has no chance to get a plausible CNOM value";
BA_ "GenSigStartValue" SG_ 2227254530 BAT_SocErrSta 1;
BA_ "UserSigValidity" SG_ 2227254530 BAT_SocErrSta 7;
BA_ "RoutingFactor" SG_ 2227254530 BAT_SocErrSta 5;
BA_ "Version" SG_ 2227254530 BAT_SocErrSta "19.01.00";
BA_ "GenMsgCycleTime" BO_ 171 0;
BA_ "Description" SG_ 171 BLTN_CAM_UI_Mode_Tmt_Req "Built-in Cam UI Mode terminate request.";
BA_ "GenSigSendType" SG_ 171 BLTN_CAM_UI_Mode_Tmt_Req 4;
BA_ "UserSigValidity" SG_ 171 BLTN_CAM_UI_Mode_Tmt_Req 1;
BA_REL_ "GenSigTimeoutTime" BU_SG_REL_ CGW_CCU SG_ 171 BLTN_CAM_UI_Mode_Tmt_Req 0;
BA_ "Version" SG_ 171 BLTN_CAM_UI_Mode_Tmt_Req "21.05.02";
BA_ "Description" SG_ 171 BLTN_CAM_Dis_Touch_BeepSound "Display Touch Beep Sound of valid space touch.";
BA_ "GenSigSendType" SG_ 171 BLTN_CAM_Dis_Touch_BeepSound 4;
BA_ "UserSigValidity" SG_ 171 BLTN_CAM_Dis_Touch_BeepSound 1;
BA_ "Version" SG_ 171 BLTN_CAM_Dis_Touch_BeepSound "21.05.02";
BA_ "Description" SG_ 171 BLTN_CAM_PopUp_Req "Built-in Cam Operating and SD Card related Popup Request on HU Display.";
BA_ "GenSigSendType" SG_ 171 BLTN_CAM_PopUp_Req 4;
BA_ "UserSigValidity" SG_ 171 BLTN_CAM_PopUp_Req 1;
BA_REL_ "GenSigTimeoutTime" BU_SG_REL_ CGW_CCU SG_ 171 BLTN_CAM_PopUp_Req 0;
BA_ "Version" SG_ 171 BLTN_CAM_PopUp_Req "21.11.07";
BA_ "Description" SG_ 171 BLTN_CAM_File_List_Renew "The Storage information is renewed inform to HU.";
BA_ "GenSigSendType" SG_ 171 BLTN_CAM_File_List_Renew 4;
BA_ "UserSigValidity" SG_ 171 BLTN_CAM_File_List_Renew 1;
BA_REL_ "GenSigTimeoutTime" BU_SG_REL_ CGW_CCU SG_ 171 BLTN_CAM_File_List_Renew 0;
BA_ "Version" SG_ 171 BLTN_CAM_File_List_Renew "21.05.02";
BA_ "Description" SG_ 171 BLTN_CAM_Wifi_Pwd_Chg_State "The Response, when HU change Wifi Passowrd via SOME/IP";
BA_ "GenSigSendType" SG_ 171 BLTN_CAM_Wifi_Pwd_Chg_State 4;
BA_ "UserSigValidity" SG_ 171 BLTN_CAM_Wifi_Pwd_Chg_State 1;
BA_REL_ "GenSigTimeoutTime" BU_SG_REL_ CGW_CCU SG_ 171 BLTN_CAM_Wifi_Pwd_Chg_State 0;
BA_ "Version" SG_ 171 BLTN_CAM_Wifi_Pwd_Chg_State "21.05.04";
BA_ "GenMsgSendType" BO_ 2231452929 0;
BA_ "GenMsgCycleTime" BO_ 2231452929 100;
BA_ "GenMsgCycleTimeFast" BO_ 2231452929 0;
BA_ "GenMsgNrOfRepetition" BO_ 2231452929 0;
BA_ "VFrameFormat" BO_ 2231452929 1;
BA_ "Description" SG_ 2231452929 DATC_Crc1Val "The data area for CRC calculation is based on the data length (DLC) of the message DB.

The CRC shall be calculated over the entire data block (excluding the CRC bytes) including the user data, alive counter and Data ID

 

- CRC Polynomial (0x1021) , Initial Value : 0xFFFF, XOR value : 0x0000, Data ID : Message ID + 0xF800 

- The initial value is for CRC calculation and the message should be sent with the calculated result value. 

- The mathematical expression to 16 bit CRC polynomial is given here. G(x) = x16 + x12 + x5 + 1";
BA_ "GenSigStartValue" SG_ 2231452929 DATC_Crc1Val 65535;
BA_ "UserSigValidity" SG_ 2231452929 DATC_Crc1Val 7;
BA_ "RoutingFactor" SG_ 2231452929 DATC_Crc1Val 5;
BA_ "Version" SG_ 2231452929 DATC_Crc1Val "18.11.08";
BA_ "Description" SG_ 2231452929 DATC_AlvCnt1Val "For the first transmission request for a data element the counter shall be initialized with 0 and shall be incremented by 1 for every subsequent send request. 

When the counter reaches the maximum value(0xFF), then it shall restart with 0 for the next send request";
BA_ "UserSigValidity" SG_ 2231452929 DATC_AlvCnt1Val 7;
BA_ "RoutingFactor" SG_ 2231452929 DATC_AlvCnt1Val 5;
BA_ "Version" SG_ 2231452929 DATC_AlvCnt1Val "18.11.08";
BA_ "Description" SG_ 2231452929 DATC_PtcRlySta "This signal indicates PTC relay operation condition of gasoline engine. This signal is used for EMS to decide engine RPM up.";
BA_ "UserSigValidity" SG_ 2231452929 DATC_PtcRlySta 7;
BA_ "RoutingFactor" SG_ 2231452929 DATC_PtcRlySta 5;
BA_ "Version" SG_ 2231452929 DATC_PtcRlySta "17.11.00";
BA_ "Description" SG_ 2231452929 DATC_ManufacturerTyp "This signal FATC_ID identifies FATC Maker.";
BA_ "UserSigValidity" SG_ 2231452929 DATC_ManufacturerTyp 3;
BA_ "RoutingFactor" SG_ 2231452929 DATC_ManufacturerTyp 5;
BA_ "Version" SG_ 2231452929 DATC_ManufacturerTyp "17.11.00";
BA_ "Description" SG_ 2231452929 DATC_DatcPwmSts "This signal indicates operating status of E-comp.";
BA_ "UserSigValidity" SG_ 2231452929 DATC_DatcPwmSts 3;
BA_ "RoutingFactor" SG_ 2231452929 DATC_DatcPwmSts 5;
BA_ "Version" SG_ 2231452929 DATC_DatcPwmSts "18.09.00";
BA_ "Description" SG_ 2231452929 DATC_AcnCompTyp "Heater Control(FATC/MTC) information generated by HVAC Compressor type.";
BA_ "UserSigValidity" SG_ 2231452929 DATC_AcnCompTyp 3;
BA_ "RoutingFactor" SG_ 2231452929 DATC_AcnCompTyp 5;
BA_ "Version" SG_ 2231452929 DATC_AcnCompTyp "17.11.00";
BA_ "Description" SG_ 2231452929 DATC_EewpRpmLvlReq "EEWP Target RPM level



00h : MAX A/C

01h : Low

02h : Mid

03h : High";
BA_ "UserSigValidity" SG_ 2231452929 DATC_EewpRpmLvlReq 3;
BA_ "RoutingFactor" SG_ 2231452929 DATC_EewpRpmLvlReq 5;
BA_ "Version" SG_ 2231452929 DATC_EewpRpmLvlReq "17.11.00";
BA_ "Description" SG_ 2231452929 DATC_Cooldown "This signal indicates complete of cooldown.";
BA_ "UserSigValidity" SG_ 2231452929 DATC_Cooldown 3;
BA_ "RoutingFactor" SG_ 2231452929 DATC_Cooldown 5;
BA_ "Version" SG_ 2231452929 DATC_Cooldown "18.09.00";
BA_ "Description" SG_ 2231452929 DATC_AcnReq "This signal indicates A/C request switch by FATC

This signal occurs when A/C switch(button) is selected either manually or automatically.

EMS decides the torque compensation value to avoid torque shortage while A/C on";
BA_ "UserSigValidity" SG_ 2231452929 DATC_AcnReq 7;
BA_ "RoutingFactor" SG_ 2231452929 DATC_AcnReq 5;
BA_ "Version" SG_ 2231452929 DATC_AcnReq "17.11.00";
BA_ "Description" SG_ 2231452929 DATC_BlwSta "This signal indicates HVAC blower motor operation condition.

The signal is used for EMS to decide PTC on or manage battery level.";
BA_ "UserSigValidity" SG_ 2231452929 DATC_BlwSta 7;
BA_ "RoutingFactor" SG_ 2231452929 DATC_BlwSta 5;
BA_ "Version" SG_ 2231452929 DATC_BlwSta "17.11.00";
BA_ "Description" SG_ 2231452929 DATC_BlwMaxSta "This signal indicates that FATC operates HVAC blower by maximum speed.";
BA_ "UserSigValidity" SG_ 2231452929 DATC_BlwMaxSta 7;
BA_ "RoutingFactor" SG_ 2231452929 DATC_BlwMaxSta 5;
BA_ "Version" SG_ 2231452929 DATC_BlwMaxSta "17.11.00";
BA_ "Description" SG_ 2231452929 DATC_EngStrtReq "FATC requests Engine Auto Start to EMS by this signal during idle stop.";
BA_ "UserSigValidity" SG_ 2231452929 DATC_EngStrtReq 3;
BA_ "RoutingFactor" SG_ 2231452929 DATC_EngStrtReq 5;
BA_ "Version" SG_ 2231452929 DATC_EngStrtReq "17.11.00";
BA_ "Description" SG_ 2231452929 DATC_IsgInhbtReq "FATC requests EMS that ISG is prohibited (ISG function is not operating) by this signal.

FATC send the disable signal in the condition, for example HVAC Blower is Max.";
BA_ "UserSigValidity" SG_ 2231452929 DATC_IsgInhbtReq 3;
BA_ "RoutingFactor" SG_ 2231452929 DATC_IsgInhbtReq 5;
BA_ "Version" SG_ 2231452929 DATC_IsgInhbtReq "17.11.00";
BA_ "Description" SG_ 2231452929 DATC_AcnCompOnReq "FATC requests A/C compressor clutch on or off to EMS by this signal

This signal is off to maintain a/c refrigerant flow and air flow smoothly and avoid abnormal a/c compressor torque rising even though A/C request switch on, if the surface temperature of evaporator is below the certain icing temperature.";
BA_ "UserSigValidity" SG_ 2231452929 DATC_AcnCompOnReq 3;
BA_ "RoutingFactor" SG_ 2231452929 DATC_AcnCompOnReq 5;
BA_ "Version" SG_ 2231452929 DATC_AcnCompOnReq "17.11.00";
BA_ "Description" SG_ 2231452929 DATC_SrvLmpReq "This signal indicates request of service Lamp";
BA_ "UserSigValidity" SG_ 2231452929 DATC_SrvLmpReq 7;
BA_ "RoutingFactor" SG_ 2231452929 DATC_SrvLmpReq 5;
BA_ "Version" SG_ 2231452929 DATC_SrvLmpReq "19.08.04";
BA_ "Description" SG_ 2231452929 DATC_EcvFltSta "This signal indicates ECV control fault.

The detailed fault state is in the error identifiers of CR_Fatc_TqAcnOut signal";
BA_ "UserSigValidity" SG_ 2231452929 DATC_EcvFltSta 3;
BA_ "RoutingFactor" SG_ 2231452929 DATC_EcvFltSta 5;
BA_ "Version" SG_ 2231452929 DATC_EcvFltSta "17.11.00";
BA_ "Description" SG_ 2231452929 DATC_CalcAcnCompTqVal "This signal indicates the torque output of A/C compressor calculated by FATC.

EMS decides the torque compensation value or A/C compressor clutch disengagement (off) by receiving of this signal.";
BA_ "UserSigValidity" SG_ 2231452929 DATC_CalcAcnCompTqVal 3;
BA_ "RoutingFactor" SG_ 2231452929 DATC_CalcAcnCompTqVal 5;
BA_ "Version" SG_ 2231452929 DATC_CalcAcnCompTqVal "17.11.00";
BA_ "GenMsgSendType" BO_ 2231452930 0;
BA_ "GenMsgCycleTime" BO_ 2231452930 100;
BA_ "GenMsgCycleTimeFast" BO_ 2231452930 0;
BA_ "GenMsgNrOfRepetition" BO_ 2231452930 0;
BA_ "VFrameFormat" BO_ 2231452930 1;
BA_ "UserSigValidity" SG_ 2231452930 DATC_AcnECompOpSta 7;
BA_ "RoutingFactor" SG_ 2231452930 DATC_AcnECompOpSta 5;
BA_ "Version" SG_ 2231452930 DATC_AcnECompOpSta "17.11.00";
BA_ "UserSigValidity" SG_ 2231452930 DATC_HVCompIntlkSta 7;
BA_ "RoutingFactor" SG_ 2231452930 DATC_HVCompIntlkSta 5;
BA_ "Version" SG_ 2231452930 DATC_HVCompIntlkSta "17.11.00";
BA_ "Description" SG_ 2231452930 DATC_HVIntDischrgLkReq "This signal indicates forced discharge request when HV PTC Interlock or E-Compressor Interlock is open.";
BA_ "UserSigValidity" SG_ 2231452930 DATC_HVIntDischrgLkReq 7;
BA_ "RoutingFactor" SG_ 2231452930 DATC_HVIntDischrgLkReq 5;
BA_ "Version" SG_ 2231452930 DATC_HVIntDischrgLkReq "17.11.00";
BA_ "Description" SG_ 2231452930 DATC_AcnECompMaxReqPwrVal "0....20440[W] = 00H...3FEH (PH)= 20 * (HEX)[W]";
BA_ "UserSigValidity" SG_ 2231452930 DATC_AcnECompMaxReqPwrVal 7;
BA_ "RoutingFactor" SG_ 2231452930 DATC_AcnECompMaxReqPwrVal 5;
BA_ "Version" SG_ 2231452930 DATC_AcnECompMaxReqPwrVal "19.08.04";
BA_ "UserSigValidity" SG_ 2231452930 DATC_AcnCompFltSta 7;
BA_ "RoutingFactor" SG_ 2231452930 DATC_AcnCompFltSta 5;
BA_ "Version" SG_ 2231452930 DATC_AcnCompFltSta "17.11.00";
BA_ "Description" SG_ 2231452930 DATC_AcnECompCnsmptPwrVal "0¡¦20440[W] = 00H...3FEH (PH)= 20 * (HEX)[W]";
BA_ "UserSigValidity" SG_ 2231452930 DATC_AcnECompCnsmptPwrVal 7;
BA_ "RoutingFactor" SG_ 2231452930 DATC_AcnECompCnsmptPwrVal 5;
BA_ "Version" SG_ 2231452930 DATC_AcnECompCnsmptPwrVal "19.08.04";
BA_ "UserSigValidity" SG_ 2231452930 DATC_MainRlyOffReq 3;
BA_ "RoutingFactor" SG_ 2231452930 DATC_MainRlyOffReq 5;
BA_ "Version" SG_ 2231452930 DATC_MainRlyOffReq "17.11.00";
BA_ "Description" SG_ 2231452930 DATC_MixDfgSelSta "DATC will send this request signal to BMS when controlled in Mix/Def mode.";
BA_ "UserSigValidity" SG_ 2231452930 DATC_MixDfgSelSta 3;
BA_ "RoutingFactor" SG_ 2231452930 DATC_MixDfgSelSta 5;
BA_ "Version" SG_ 2231452930 DATC_MixDfgSelSta "17.11.00";
BA_ "Description" SG_ 2231452930 DATC_BattChlrVlvSta "Battery chiller valve status";
BA_ "UserSigValidity" SG_ 2231452930 DATC_BattChlrVlvSta 3;
BA_ "RoutingFactor" SG_ 2231452930 DATC_BattChlrVlvSta 5;
BA_ "Version" SG_ 2231452930 DATC_BattChlrVlvSta "19.07.02";
BA_ "UserSigValidity" SG_ 2231452930 DATC_WaterPmpOnReq 3;
BA_ "RoutingFactor" SG_ 2231452930 DATC_WaterPmpOnReq 5;
BA_ "Version" SG_ 2231452930 DATC_WaterPmpOnReq "17.11.00";
BA_ "Description" SG_ 2231452930 DATC_AcnECompSpdVal "0 ¡¦65534 [rpm] = 0000H ¡¦ FFFEH, (PH) = 1*(HEX) [rpm]";
BA_ "UserSigValidity" SG_ 2231452930 DATC_AcnECompSpdVal 7;
BA_ "RoutingFactor" SG_ 2231452930 DATC_AcnECompSpdVal 5;
BA_ "Version" SG_ 2231452930 DATC_AcnECompSpdVal "17.11.00";
BA_ "Description" SG_ 2231452930 DATC_AcnCompSlpModCodVal "(PH) = 1 * (HEX) [-]";
BA_ "UserSigValidity" SG_ 2231452930 DATC_AcnCompSlpModCodVal 7;
BA_ "RoutingFactor" SG_ 2231452930 DATC_AcnCompSlpModCodVal 5;
BA_ "Version" SG_ 2231452930 DATC_AcnCompSlpModCodVal "17.11.00";
BA_ "UserSigValidity" SG_ 2231452930 DATC_RrDfgOpSta 3;
BA_ "RoutingFactor" SG_ 2231452930 DATC_RrDfgOpSta 5;
BA_ "Version" SG_ 2231452930 DATC_RrDfgOpSta "17.11.00";
BA_ "UserSigValidity" SG_ 2231452930 DATC_AcnECompCANFltSta 3;
BA_ "RoutingFactor" SG_ 2231452930 DATC_AcnECompCANFltSta 5;
BA_ "Version" SG_ 2231452930 DATC_AcnECompCANFltSta "17.11.00";
BA_ "GenMsgSendType" BO_ 2231452931 0;
BA_ "GenMsgCycleTime" BO_ 2231452931 100;
BA_ "GenMsgCycleTimeFast" BO_ 2231452931 0;
BA_ "GenMsgNrOfRepetition" BO_ 2231452931 0;
BA_ "VFrameFormat" BO_ 2231452931 1;
BA_ "Description" SG_ 2231452931 DATC_AcnCompWaitCodVal "(PH) = 1 * (HEX) [-]";
BA_ "UserSigValidity" SG_ 2231452931 DATC_AcnCompWaitCodVal 7;
BA_ "RoutingFactor" SG_ 2231452931 DATC_AcnCompWaitCodVal 5;
BA_ "Version" SG_ 2231452931 DATC_AcnCompWaitCodVal "17.11.00";
BA_ "Description" SG_ 2231452931 DATC_PeEwpRPMReq "This signal indicates Cooling For High V Component (for A/C or Heatpump)

ÀüÀå¿ë ³Ã°¢¼ö¿ë, ÀüÀåÆó¿­À» ÀÌ¿ëÇÑ ¸®È÷ÆÃ¿ë";
BA_ "UserSigValidity" SG_ 2231452931 DATC_PeEwpRPMReq 3;
BA_ "RoutingFactor" SG_ 2231452931 DATC_PeEwpRPMReq 5;
BA_ "Version" SG_ 2231452931 DATC_PeEwpRPMReq "20.05.02";
BA_ "Description" SG_ 2231452931 DATC_AEwpSpdRpmReq "This signal indicates Request EWP speed to recover heat in HVAC System.(ENG COOLING ¿ë È¸·Î / È÷ÅÍÄÚ¾î ¿¬°ü)";
BA_ "UserSigValidity" SG_ 2231452931 DATC_AEwpSpdRpmReq 7;
BA_ "RoutingFactor" SG_ 2231452931 DATC_AEwpSpdRpmReq 5;
BA_ "Version" SG_ 2231452931 DATC_AEwpSpdRpmReq "17.11.00";
BA_ "Description" SG_ 2231452931 DATC_RadFanReq_Duty "This signal indicates Request cooling fan speed to cool HVAC System (Duty)

(0xFE value is only used to wake up EMS )";
BA_ "UserSigValidity" SG_ 2231452931 DATC_RadFanReq_Duty 5;
BA_ "RoutingFactor" SG_ 2231452931 DATC_RadFanReq_Duty 5;
BA_ "Version" SG_ 2231452931 DATC_RadFanReq_Duty "20.02.05";
BA_ "Description" SG_ 2231452931 DATC_OutTempSnsrVal "Actual temperature of Ambient Sensor via an A/D converter; converted into degrees

centigrade (¡É).

This is raw data of ambient sensor; just transferred from Ambient Sensor Voltage.";
BA_ "UserSigValidity" SG_ 2231452931 DATC_OutTempSnsrVal 7;
BA_REL_ "GenSigTimeoutTime" BU_SG_REL_ RCM SG_ 2231452931 DATC_OutTempSnsrVal 1500;
BA_ "RoutingFactor" SG_ 2231452931 DATC_OutTempSnsrVal 5;
BA_ "Version" SG_ 2231452931 DATC_OutTempSnsrVal "17.11.00";
BA_ "Description" SG_ 2231452931 DATC_ActvEco "This signal indicates the operating condition (ON or OFF) of Active ECO Button.";
BA_ "UserSigValidity" SG_ 2231452931 DATC_ActvEco 7;
BA_ "RoutingFactor" SG_ 2231452931 DATC_ActvEco 5;
BA_ "Version" SG_ 2231452931 DATC_ActvEco "17.11.00";
BA_ "Description" SG_ 2231452931 DATC_AUTOActv "As soon as FATC receive activation message from TMU, 

For 5 Seconds, FATC Send The massage ¡° Automatic control is Active(01H) ¡° and 

control 23¡É Auto.

After 5 seconds FATC send the initial value(00H) massage";
BA_ "UserSigValidity" SG_ 2231452931 DATC_AUTOActv 7;
BA_ "RoutingFactor" SG_ 2231452931 DATC_AUTOActv 5;
BA_ "Version" SG_ 2231452931 DATC_AUTOActv "17.11.00";
BA_ "Description" SG_ 2231452931 DATC_DfgSw "This signal indicates whether FRONT DEF switch is selected or not.";
BA_ "UserSigValidity" SG_ 2231452931 DATC_DfgSw 7;
BA_ "RoutingFactor" SG_ 2231452931 DATC_DfgSw 5;
BA_ "Version" SG_ 2231452931 DATC_DfgSw "17.11.00";
BA_ "Description" SG_ 2231452931 DATC_BattChlrVlv_FltCode "Battery Chiller Filt Code";
BA_ "UserSigValidity" SG_ 2231452931 DATC_BattChlrVlv_FltCode 3;
BA_ "RoutingFactor" SG_ 2231452931 DATC_BattChlrVlv_FltCode 5;
BA_ "Version" SG_ 2231452931 DATC_BattChlrVlv_FltCode "18.09.00";
BA_ "Description" SG_ 2231452931 DATC_BattEvapVlvSta "BATTERY COOL V/V (EVAP) STATUS";
BA_ "UserSigValidity" SG_ 2231452931 DATC_BattEvapVlvSta 5;
BA_ "RoutingFactor" SG_ 2231452931 DATC_BattEvapVlvSta 5;
BA_ "Version" SG_ 2231452931 DATC_BattEvapVlvSta "18.09.00";
BA_ "Description" SG_ 2231452931 DATC_BattEvapVlv_FltCode "BATTERY COOL V/V (EVAP) FltCode";
BA_ "UserSigValidity" SG_ 2231452931 DATC_BattEvapVlv_FltCode 5;
BA_ "RoutingFactor" SG_ 2231452931 DATC_BattEvapVlv_FltCode 5;
BA_ "Version" SG_ 2231452931 DATC_BattEvapVlv_FltCode "18.09.00";
BA_ "Description" SG_ 2231452931 DATC_Wrmup "This signal indicates complete of warmup";
BA_ "UserSigValidity" SG_ 2231452931 DATC_Wrmup 5;
BA_ "RoutingFactor" SG_ 2231452931 DATC_Wrmup 5;
BA_ "Version" SG_ 2231452931 DATC_Wrmup "18.09.00";
BA_ "Description" SG_ 2231452931 DATC_SSC_EngStrtReq "Engine start request in SSC state";
BA_ "UserSigValidity" SG_ 2231452931 DATC_SSC_EngStrtReq 3;
BA_ "RoutingFactor" SG_ 2231452931 DATC_SSC_EngStrtReq 5;
BA_ "Version" SG_ 2231452931 DATC_SSC_EngStrtReq "19.04.00";
BA_ "Description" SG_ 2231452931 DATC_AcnCompSta "1 : Initialize Mode, 2: Standby Mode, 4 : Wait Mode, 8 : Sleep Mode, 10H: Operating Mode";
BA_ "UserSigValidity" SG_ 2231452931 DATC_AcnCompSta 3;
BA_ "RoutingFactor" SG_ 2231452931 DATC_AcnCompSta 5;
BA_ "Version" SG_ 2231452931 DATC_AcnCompSta "17.11.00";
BA_ "GenMsgSendType" BO_ 2231452932 0;
BA_ "GenMsgCycleTime" BO_ 2231452932 100;
BA_ "GenMsgCycleTimeFast" BO_ 2231452932 0;
BA_ "GenMsgNrOfRepetition" BO_ 2231452932 0;
BA_ "VFrameFormat" BO_ 2231452932 1;
BA_ "Description" SG_ 2231452932 DATC_SSC_InhbtReq "Request to EMS not to enter SSC";
BA_ "UserSigValidity" SG_ 2231452932 DATC_SSC_InhbtReq 3;
BA_ "RoutingFactor" SG_ 2231452932 DATC_SSC_InhbtReq 5;
BA_ "Version" SG_ 2231452932 DATC_SSC_InhbtReq "19.04.00";
BA_ "Description" SG_ 2231452932 DATC_EngIdlRpmUpReq "This signal is information of A/C Comp_Load by FATC.";
BA_ "UserSigValidity" SG_ 2231452932 DATC_EngIdlRpmUpReq 3;
BA_ "RoutingFactor" SG_ 2231452932 DATC_EngIdlRpmUpReq 5;
BA_ "Version" SG_ 2231452932 DATC_EngIdlRpmUpReq "20.07.12";
BA_ "Description" SG_ 2231452932 DATC_MaxBlwVolt "Max blower voltage that only B+ status send to LDC";
BA_ "UserSigValidity" SG_ 2231452932 DATC_MaxBlwVolt 7;
BA_ "RoutingFactor" SG_ 2231452932 DATC_MaxBlwVolt 5;
BA_ "Version" SG_ 2231452932 DATC_MaxBlwVolt "20.05.01";
BA_ "Description" SG_ 2231452932 DATC_HVACPmpOpSta "HVAC Pump Operation Status";
BA_ "UserSigValidity" SG_ 2231452932 DATC_HVACPmpOpSta 3;
BA_ "RoutingFactor" SG_ 2231452932 DATC_HVACPmpOpSta 5;
BA_ "Version" SG_ 2231452932 DATC_HVACPmpOpSta "18.09.00";
BA_ "Description" SG_ 2231452932 DATC_MildCooldown "Mild Cooldown State";
BA_ "UserSigValidity" SG_ 2231452932 DATC_MildCooldown 7;
BA_ "RoutingFactor" SG_ 2231452932 DATC_MildCooldown 5;
BA_ "Version" SG_ 2231452932 DATC_MildCooldown "18.10.06";
BA_ "Description" SG_ 2231452932 DATC_MildWrmup "Mild Warmup State";
BA_ "UserSigValidity" SG_ 2231452932 DATC_MildWrmup 5;
BA_ "RoutingFactor" SG_ 2231452932 DATC_MildWrmup 5;
BA_ "Version" SG_ 2231452932 DATC_MildWrmup "18.09.00";
BA_ "Description" SG_ 2231452932 DATC_BlwrLvl "This signal indicates step of Front blower operation .";
BA_ "UserSigValidity" SG_ 2231452932 DATC_BlwrLvl 7;
BA_ "RoutingFactor" SG_ 2231452932 DATC_BlwrLvl 5;
BA_ "Version" SG_ 2231452932 DATC_BlwrLvl "18.10.06";
BA_ "Description" SG_ 2231452932 DATC_AAFOpenReq "Open Reqest Active Air Flap(AAF) before Compressor max rpm";
BA_ "UserSigValidity" SG_ 2231452932 DATC_AAFOpenReq 7;
BA_ "RoutingFactor" SG_ 2231452932 DATC_AAFOpenReq 5;
BA_ "Version" SG_ 2231452932 DATC_AAFOpenReq "19.06.03";
BA_ "Description" SG_ 2231452932 DATC_BattEwpOpReq "This signal requests the operation of BATT EWP for heat recovery technique.";
BA_ "UserSigValidity" SG_ 2231452932 DATC_BattEwpOpReq 5;
BA_ "RoutingFactor" SG_ 2231452932 DATC_BattEwpOpReq 5;
BA_ "Version" SG_ 2231452932 DATC_BattEwpOpReq "18.12.03";
BA_ "GenMsgSendType" BO_ 2382594561 0;
BA_ "VFrameFormat" BO_ 2382594561 1;
BA_ "Description" SG_ 2382594561 DATC_Crc5Val "The data area for CRC calculation is based on the data length (DLC) of the message DB.

The CRC shall be calculated over the entire data block (excluding the CRC bytes) including the user data, alive counter and Data ID

 

- CRC Polynomial (0x1021) , Initial Value : 0xFFFF, XOR value : 0x0000, Data ID : Message ID + 0xF800 

- The initial value is for CRC calculation and the message should be sent with the calculated result value. 

- The mathematical expression to 16 bit CRC polynomial is given here. G(x) = x16 + x12 + x5 + 1";
BA_ "GenSigSendType" SG_ 2382594561 DATC_Crc5Val 4;
BA_ "GenSigStartValue" SG_ 2382594561 DATC_Crc5Val 65535;
BA_ "UserSigValidity" SG_ 2382594561 DATC_Crc5Val 3;
BA_ "Version" SG_ 2382594561 DATC_Crc5Val "18.11.08";
BA_ "Description" SG_ 2382594561 DATC_AlvCnt5Val "For the first transmission request for a data element the counter shall be initialized with 0 and shall be incremented by 1 for every subsequent send request. 

When the counter reaches the maximum value(0xFF), then it shall restart with 0 for the next send request";
BA_ "GenSigSendType" SG_ 2382594561 DATC_AlvCnt5Val 4;
BA_ "UserSigValidity" SG_ 2382594561 DATC_AlvCnt5Val 3;
BA_ "Version" SG_ 2382594561 DATC_AlvCnt5Val "18.11.08";
BA_ "Description" SG_ 2382594561 DATC_FrDrvModDis "This signal indicates MODE of HTR Control (VENT, B/L, FLOOR, MIX, DEF, AUTO Defog).

This signal occurs when MODE switch(button) is selected either manually or automatically.";
BA_ "GenSigSendType" SG_ 2382594561 DATC_FrDrvModDis 4;
BA_ "UserSigValidity" SG_ 2382594561 DATC_FrDrvModDis 7;
BA_REL_ "GenSigTimeoutTime" BU_SG_REL_ ATS SG_ 2382594561 DATC_FrDrvModDis 1500;
BA_ "Version" SG_ 2382594561 DATC_FrDrvModDis "18.11.06";
BA_ "Description" SG_ 2382594561 DATC_FrPassModDis "This signal indicates Passenger MODE of HTR Control

 (VENT, B/L, FLOOR, MIX, DEF, AUTO Defog)

This signal occurs when MODE switch(button) is selected either manually or automatically";
BA_ "GenSigSendType" SG_ 2382594561 DATC_FrPassModDis 4;
BA_ "UserSigValidity" SG_ 2382594561 DATC_FrPassModDis 7;
BA_REL_ "GenSigTimeoutTime" BU_SG_REL_ ATS SG_ 2382594561 DATC_FrPassModDis 1500;
BA_ "Version" SG_ 2382594561 DATC_FrPassModDis "18.11.05";
BA_ "Description" SG_ 2382594561 DATC_ClmtTxtPopupOSD "Climate Text Pop-up OSD";
BA_ "GenSigSendType" SG_ 2382594561 DATC_ClmtTxtPopupOSD 4;
BA_ "TimeoutValue" SG_ 2382594561 DATC_ClmtTxtPopupOSD "0x0";
BA_ "UserSigValidity" SG_ 2382594561 DATC_ClmtTxtPopupOSD 7;
BA_REL_ "GenSigTimeoutTime" BU_SG_REL_ ATS SG_ 2382594561 DATC_ClmtTxtPopupOSD 1500;
BA_ "Version" SG_ 2382594561 DATC_ClmtTxtPopupOSD "21.04.10";
BA_ "Description" SG_ 2382594561 DATC_TempDispUnitSta "This signal indicates Temp unit of HTR Control (¡É, ¢µ).";
BA_ "GenSigSendType" SG_ 2382594561 DATC_TempDispUnitSta 4;
BA_ "UserSigValidity" SG_ 2382594561 DATC_TempDispUnitSta 6;
BA_REL_ "GenSigTimeoutTime" BU_SG_REL_ ATS SG_ 2382594561 DATC_TempDispUnitSta 1500;
BA_ "Version" SG_ 2382594561 DATC_TempDispUnitSta "17.11.00";
BA_ "Description" SG_ 2382594561 DATC_DrvAutoDis "This signal indicates AUTO Graphic On & Off.

This signal occurs when AUTO switch(button) is selected either manually or automatically.";
BA_ "GenSigSendType" SG_ 2382594561 DATC_DrvAutoDis 4;
BA_ "UserSigValidity" SG_ 2382594561 DATC_DrvAutoDis 6;
BA_REL_ "GenSigTimeoutTime" BU_SG_REL_ ATS SG_ 2382594561 DATC_DrvAutoDis 1500;
BA_ "Version" SG_ 2382594561 DATC_DrvAutoDis "17.11.00";
BA_ "Description" SG_ 2382594561 DATC_FrChgReqDis "This signal indicates to show Climate Pop-up screen.

This signal occurs when any kinds of climate switch(button)s are selected manually.";
BA_ "GenSigSendType" SG_ 2382594561 DATC_FrChgReqDis 4;
BA_ "UserSigValidity" SG_ 2382594561 DATC_FrChgReqDis 6;
BA_ "Version" SG_ 2382594561 DATC_FrChgReqDis "17.11.00";
BA_ "Description" SG_ 2382594561 DATC_FrClmtScrnDis "This signal indicates that screen change to Climate Full screen.



This signal occurs when Climate switch(button) is selected manually.";
BA_ "GenSigSendType" SG_ 2382594561 DATC_FrClmtScrnDis 4;
BA_ "UserSigValidity" SG_ 2382594561 DATC_FrClmtScrnDis 6;
BA_REL_ "GenSigTimeoutTime" BU_SG_REL_ ATS SG_ 2382594561 DATC_FrClmtScrnDis 1500;
BA_ "Version" SG_ 2382594561 DATC_FrClmtScrnDis "17.11.00";
BA_ "Description" SG_ 2382594561 DATC_AcDis "This signal indicates A/C Graphic On & Off.

This signal occurs when A/C switch(button) is selected either manually or automatically.";
BA_ "GenSigSendType" SG_ 2382594561 DATC_AcDis 4;
BA_ "UserSigValidity" SG_ 2382594561 DATC_AcDis 6;
BA_REL_ "GenSigTimeoutTime" BU_SG_REL_ ATS SG_ 2382594561 DATC_AcDis 1500;
BA_ "Version" SG_ 2382594561 DATC_AcDis "17.11.00";
BA_ "Description" SG_ 2382594561 DATC_IntakeSta "This signal indicates Intake status (REC or FRE).";
BA_ "GenSigSendType" SG_ 2382594561 DATC_IntakeSta 4;
BA_ "UserSigValidity" SG_ 2382594561 DATC_IntakeSta 7;
BA_ "Version" SG_ 2382594561 DATC_IntakeSta "17.11.00";
BA_ "Description" SG_ 2382594561 DATC_TempDrLvl "This signal indicates level of temp door.";
BA_ "GenSigSendType" SG_ 2382594561 DATC_TempDrLvl 4;
BA_ "UserSigValidity" SG_ 2382594561 DATC_TempDrLvl 3;
BA_ "Version" SG_ 2382594561 DATC_TempDrLvl "18.09.00";
BA_ "Description" SG_ 2382594561 DATC_BattCompPwrCnsmptn_W "This signal indicates consumption power by e-compressor for battery";
BA_ "GenSigSendType" SG_ 2382594561 DATC_BattCompPwrCnsmptn_W 4;
BA_ "UserSigValidity" SG_ 2382594561 DATC_BattCompPwrCnsmptn_W 5;
BA_ "Version" SG_ 2382594561 DATC_BattCompPwrCnsmptn_W "18.09.00";
BA_ "GenMsgSendType" BO_ 2424580353 0;
BA_ "VFrameFormat" BO_ 2424580353 1;
BA_ "Description" SG_ 2424580353 DATC_Crc12Val "The data area for CRC calculation is based on the data length (DLC) of the message DB.

The CRC shall be calculated over the entire data block (excluding the CRC bytes) including the user data, alive counter and Data ID

 

- CRC Polynomial (0x1021) , Initial Value : 0xFFFF, XOR value : 0x0000, Data ID : Message ID + 0xF800 

- The initial value is for CRC calculation and the message should be sent with the calculated result value. 

- The mathematical expression to 16 bit CRC polynomial is given here. G(x) = x16 + x12 + x5 + 1";
BA_ "GenSigSendType" SG_ 2424580353 DATC_Crc12Val 4;
BA_ "GenSigStartValue" SG_ 2424580353 DATC_Crc12Val 65535;
BA_ "UserSigValidity" SG_ 2424580353 DATC_Crc12Val 3;
BA_ "Version" SG_ 2424580353 DATC_Crc12Val "18.11.08";
BA_ "Description" SG_ 2424580353 DATC_AlvCnt12Val "For the first transmission request for a data element the counter shall be initialized with 0 and shall be incremented by 1 for every subsequent send request. 

When the counter reaches the maximum value(0xFF), then it shall restart with 0 for the next send request";
BA_ "GenSigSendType" SG_ 2424580353 DATC_AlvCnt12Val 4;
BA_ "UserSigValidity" SG_ 2424580353 DATC_AlvCnt12Val 3;
BA_ "Version" SG_ 2424580353 DATC_AlvCnt12Val "18.11.08";
BA_ "Description" SG_ 2424580353 DATC_StrWhlHtrSwReq "Steering Wheel heater S/W";
BA_ "GenSigSendType" SG_ 2424580353 DATC_StrWhlHtrSwReq 4;
BA_ "UserSigValidity" SG_ 2424580353 DATC_StrWhlHtrSwReq 7;
BA_ "Version" SG_ 2424580353 DATC_StrWhlHtrSwReq "17.11.00";
BA_ "Description" SG_ 2424580353 DATC_FRStHtrSwReq "Front Right Seat heater S/W";
BA_ "GenSigSendType" SG_ 2424580353 DATC_FRStHtrSwReq 4;
BA_ "UserSigValidity" SG_ 2424580353 DATC_FRStHtrSwReq 7;
BA_REL_ "GenSigTimeoutTime" BU_SG_REL_ APSU SG_ 2424580353 DATC_FRStHtrSwReq 1500;
BA_REL_ "GenSigTimeoutTime" BU_SG_REL_ SHVU_FR SG_ 2424580353 DATC_FRStHtrSwReq 1500;
BA_REL_ "GenSigTimeoutTime" BU_SG_REL_ SHVU_RR SG_ 2424580353 DATC_FRStHtrSwReq 1500;
BA_REL_ "GenSigTimeoutTime" BU_SG_REL_ DPSU SG_ 2424580353 DATC_FRStHtrSwReq 1500;
BA_ "Version" SG_ 2424580353 DATC_FRStHtrSwReq "17.11.00";
BA_ "Description" SG_ 2424580353 DATC_FRStVentSwReq "Front Right Seat cooler S/W";
BA_ "GenSigSendType" SG_ 2424580353 DATC_FRStVentSwReq 4;
BA_ "UserSigValidity" SG_ 2424580353 DATC_FRStVentSwReq 7;
BA_REL_ "GenSigTimeoutTime" BU_SG_REL_ APSU SG_ 2424580353 DATC_FRStVentSwReq 1500;
BA_REL_ "GenSigTimeoutTime" BU_SG_REL_ SHVU_FR SG_ 2424580353 DATC_FRStVentSwReq 1500;
BA_REL_ "GenSigTimeoutTime" BU_SG_REL_ SHVU_RR SG_ 2424580353 DATC_FRStVentSwReq 1500;
BA_REL_ "GenSigTimeoutTime" BU_SG_REL_ DPSU SG_ 2424580353 DATC_FRStVentSwReq 1500;
BA_ "Version" SG_ 2424580353 DATC_FRStVentSwReq "17.11.00";
BA_ "Description" SG_ 2424580353 DATC_RrDefSw "Rear Defog Switch";
BA_ "GenSigSendType" SG_ 2424580353 DATC_RrDefSw 4;
BA_ "UserSigValidity" SG_ 2424580353 DATC_RrDefSw 3;
BA_ "Version" SG_ 2424580353 DATC_RrDefSw "19.04.06";
BA_ "Description" SG_ 2424580353 DATC_FLStOpReq "Left Seat warmer / Ventilation Operation request";
BA_ "GenSigSendType" SG_ 2424580353 DATC_FLStOpReq 4;
BA_ "UserSigValidity" SG_ 2424580353 DATC_FLStOpReq 7;
BA_REL_ "GenSigTimeoutTime" BU_SG_REL_ APSU SG_ 2424580353 DATC_FLStOpReq 1500;
BA_REL_ "GenSigTimeoutTime" BU_SG_REL_ SHVU_FR SG_ 2424580353 DATC_FLStOpReq 1500;
BA_REL_ "GenSigTimeoutTime" BU_SG_REL_ SHVU_RR SG_ 2424580353 DATC_FLStOpReq 1500;
BA_REL_ "GenSigTimeoutTime" BU_SG_REL_ DPSU SG_ 2424580353 DATC_FLStOpReq 1500;
BA_ "Version" SG_ 2424580353 DATC_FLStOpReq "17.11.00";
BA_ "Description" SG_ 2424580353 DATC_FRStOpReq "Right Seat Warmer / Ventilation Operation request";
BA_ "GenSigSendType" SG_ 2424580353 DATC_FRStOpReq 4;
BA_ "UserSigValidity" SG_ 2424580353 DATC_FRStOpReq 7;
BA_REL_ "GenSigTimeoutTime" BU_SG_REL_ APSU SG_ 2424580353 DATC_FRStOpReq 1500;
BA_REL_ "GenSigTimeoutTime" BU_SG_REL_ SHVU_FR SG_ 2424580353 DATC_FRStOpReq 1500;
BA_REL_ "GenSigTimeoutTime" BU_SG_REL_ SHVU_RR SG_ 2424580353 DATC_FRStOpReq 1500;
BA_ "Version" SG_ 2424580353 DATC_FRStOpReq "17.11.00";
BA_ "Description" SG_ 2424580353 DATC_FLStHtrSwReq "Front Left Seat heater S/W";
BA_ "GenSigSendType" SG_ 2424580353 DATC_FLStHtrSwReq 4;
BA_ "UserSigValidity" SG_ 2424580353 DATC_FLStHtrSwReq 7;
BA_REL_ "GenSigTimeoutTime" BU_SG_REL_ APSU SG_ 2424580353 DATC_FLStHtrSwReq 1500;
BA_REL_ "GenSigTimeoutTime" BU_SG_REL_ SHVU_FR SG_ 2424580353 DATC_FLStHtrSwReq 1500;
BA_REL_ "GenSigTimeoutTime" BU_SG_REL_ SHVU_RR SG_ 2424580353 DATC_FLStHtrSwReq 1500;
BA_REL_ "GenSigTimeoutTime" BU_SG_REL_ DPSU SG_ 2424580353 DATC_FLStHtrSwReq 1500;
BA_ "Version" SG_ 2424580353 DATC_FLStHtrSwReq "17.11.00";
BA_ "Description" SG_ 2424580353 DATC_FLStVentSwReq "Front Left Seat cooler S/W";
BA_ "GenSigSendType" SG_ 2424580353 DATC_FLStVentSwReq 4;
BA_ "UserSigValidity" SG_ 2424580353 DATC_FLStVentSwReq 7;
BA_REL_ "GenSigTimeoutTime" BU_SG_REL_ APSU SG_ 2424580353 DATC_FLStVentSwReq 1500;
BA_REL_ "GenSigTimeoutTime" BU_SG_REL_ SHVU_FR SG_ 2424580353 DATC_FLStVentSwReq 1500;
BA_REL_ "GenSigTimeoutTime" BU_SG_REL_ SHVU_RR SG_ 2424580353 DATC_FLStVentSwReq 1500;
BA_REL_ "GenSigTimeoutTime" BU_SG_REL_ DPSU SG_ 2424580353 DATC_FLStVentSwReq 1500;
BA_ "Version" SG_ 2424580353 DATC_FLStVentSwReq "17.11.00";
BA_ "Description" SG_ 2424580353 DATC_FLStTmblrSwReq "Front Left Seat cooler S/W";
BA_ "GenSigSendType" SG_ 2424580353 DATC_FLStTmblrSwReq 4;
BA_ "UserSigValidity" SG_ 2424580353 DATC_FLStTmblrSwReq 3;
BA_REL_ "GenSigTimeoutTime" BU_SG_REL_ APSU SG_ 2424580353 DATC_FLStTmblrSwReq 1500;
BA_REL_ "GenSigTimeoutTime" BU_SG_REL_ SHVU_FR SG_ 2424580353 DATC_FLStTmblrSwReq 1500;
BA_ "Version" SG_ 2424580353 DATC_FLStTmblrSwReq "18.01.07";
BA_ "Description" SG_ 2424580353 DATC_FRStTmblrSwReq "Front Left Seat cooler S/W";
BA_ "GenSigSendType" SG_ 2424580353 DATC_FRStTmblrSwReq 4;
BA_ "UserSigValidity" SG_ 2424580353 DATC_FRStTmblrSwReq 3;
BA_REL_ "GenSigTimeoutTime" BU_SG_REL_ APSU SG_ 2424580353 DATC_FRStTmblrSwReq 1500;
BA_REL_ "GenSigTimeoutTime" BU_SG_REL_ SHVU_FR SG_ 2424580353 DATC_FRStTmblrSwReq 1500;
BA_ "Version" SG_ 2424580353 DATC_FRStTmblrSwReq "18.01.07";
BA_ "Description" SG_ 2424580353 DATC_RRStHtrSwReq "This signal indicate DATC Rear Right Seat Heater Switch Request";
BA_ "GenSigSendType" SG_ 2424580353 DATC_RRStHtrSwReq 4;
BA_ "UserSigValidity" SG_ 2424580353 DATC_RRStHtrSwReq 7;
BA_REL_ "GenSigTimeoutTime" BU_SG_REL_ RRHV SG_ 2424580353 DATC_RRStHtrSwReq 1500;
BA_REL_ "GenSigTimeoutTime" BU_SG_REL_ SHVU_FR SG_ 2424580353 DATC_RRStHtrSwReq 1500;
BA_REL_ "GenSigTimeoutTime" BU_SG_REL_ SHVU_RR SG_ 2424580353 DATC_RRStHtrSwReq 1500;
BA_REL_ "GenSigTimeoutTime" BU_SG_REL_ RRPSU SG_ 2424580353 DATC_RRStHtrSwReq 1500;
BA_REL_ "GenSigTimeoutTime" BU_SG_REL_ RLPSU SG_ 2424580353 DATC_RRStHtrSwReq 1500;
BA_ "Version" SG_ 2424580353 DATC_RRStHtrSwReq "18.03.05";
BA_ "Description" SG_ 2424580353 DATC_RRStVentSwReq "This signal indicates DATC Rear Right Seat Ventilation Switch Request";
BA_ "GenSigSendType" SG_ 2424580353 DATC_RRStVentSwReq 4;
BA_ "UserSigValidity" SG_ 2424580353 DATC_RRStVentSwReq 7;
BA_REL_ "GenSigTimeoutTime" BU_SG_REL_ RRHV SG_ 2424580353 DATC_RRStVentSwReq 1500;
BA_REL_ "GenSigTimeoutTime" BU_SG_REL_ SHVU_FR SG_ 2424580353 DATC_RRStVentSwReq 1500;
BA_REL_ "GenSigTimeoutTime" BU_SG_REL_ SHVU_RR SG_ 2424580353 DATC_RRStVentSwReq 1500;
BA_REL_ "GenSigTimeoutTime" BU_SG_REL_ RRPSU SG_ 2424580353 DATC_RRStVentSwReq 1500;
BA_REL_ "GenSigTimeoutTime" BU_SG_REL_ RLPSU SG_ 2424580353 DATC_RRStVentSwReq 1500;
BA_ "Version" SG_ 2424580353 DATC_RRStVentSwReq "18.03.05";
BA_ "Description" SG_ 2424580353 DATC_RLStHtrSwReq "This signal indicates DATC Rear Left Seat Heater Switch Request";
BA_ "GenSigSendType" SG_ 2424580353 DATC_RLStHtrSwReq 4;
BA_ "UserSigValidity" SG_ 2424580353 DATC_RLStHtrSwReq 7;
BA_REL_ "GenSigTimeoutTime" BU_SG_REL_ RLHV SG_ 2424580353 DATC_RLStHtrSwReq 1500;
BA_REL_ "GenSigTimeoutTime" BU_SG_REL_ SHVU_FR SG_ 2424580353 DATC_RLStHtrSwReq 1500;
BA_REL_ "GenSigTimeoutTime" BU_SG_REL_ SHVU_RR SG_ 2424580353 DATC_RLStHtrSwReq 1500;
BA_REL_ "GenSigTimeoutTime" BU_SG_REL_ RRPSU SG_ 2424580353 DATC_RLStHtrSwReq 1500;
BA_REL_ "GenSigTimeoutTime" BU_SG_REL_ RLPSU SG_ 2424580353 DATC_RLStHtrSwReq 1500;
BA_ "Version" SG_ 2424580353 DATC_RLStHtrSwReq "19.06.00";
BA_ "Description" SG_ 2424580353 DATC_RLStVentSwReq "This signal indicates DATC Rear Left Seat Ventilation Switch Request";
BA_ "GenSigSendType" SG_ 2424580353 DATC_RLStVentSwReq 4;
BA_ "UserSigValidity" SG_ 2424580353 DATC_RLStVentSwReq 7;
BA_REL_ "GenSigTimeoutTime" BU_SG_REL_ RLHV SG_ 2424580353 DATC_RLStVentSwReq 1500;
BA_REL_ "GenSigTimeoutTime" BU_SG_REL_ SHVU_FR SG_ 2424580353 DATC_RLStVentSwReq 1500;
BA_REL_ "GenSigTimeoutTime" BU_SG_REL_ SHVU_RR SG_ 2424580353 DATC_RLStVentSwReq 1500;
BA_REL_ "GenSigTimeoutTime" BU_SG_REL_ RRPSU SG_ 2424580353 DATC_RLStVentSwReq 1500;
BA_REL_ "GenSigTimeoutTime" BU_SG_REL_ RLPSU SG_ 2424580353 DATC_RLStVentSwReq 1500;
BA_ "Version" SG_ 2424580353 DATC_RLStVentSwReq "18.03.05";
BA_ "Description" SG_ 2424580353 DATC_FRWndShldHtSW "Front windshield glass heating switch

(Russia / Canada regions applied)";
BA_ "GenSigSendType" SG_ 2424580353 DATC_FRWndShldHtSW 4;
BA_ "UserSigValidity" SG_ 2424580353 DATC_FRWndShldHtSW 3;
BA_ "Version" SG_ 2424580353 DATC_FRWndShldHtSW "19.04.06";
BA_ "Description" SG_ 2424580353 DATC_WhistlelNoise "This signal is to prevent whistle noise from the door glass

(Fresh & Blower more than 4 Step condition)";
BA_ "GenSigSendType" SG_ 2424580353 DATC_WhistlelNoise 4;
BA_ "UserSigValidity" SG_ 2424580353 DATC_WhistlelNoise 3;
BA_ "Version" SG_ 2424580353 DATC_WhistlelNoise "19.04.06";
BA_ "Description" SG_ 2424580353 DATC_WdwClsReq "This signal indicates Window Close Request.

(This signal is used for Closing Control of Window when AirClean Switch is selecting)";
BA_ "GenSigSendType" SG_ 2424580353 DATC_WdwClsReq 4;
BA_ "UserSigValidity" SG_ 2424580353 DATC_WdwClsReq 7;
BA_ "Version" SG_ 2424580353 DATC_WdwClsReq "19.07.06";
BA_ "Description" SG_ 2424580353 DATC_RRSyncDis "This signal indicates SYNC Graphic On & Off.

This signal occurs when Rear SYNC switch(button) is selected either manually or automatically.";
BA_ "GenSigSendType" SG_ 2424580353 DATC_RRSyncDis 4;
BA_ "UserSigValidity" SG_ 2424580353 DATC_RRSyncDis 7;
BA_REL_ "GenSigTimeoutTime" BU_SG_REL_ ATS SG_ 2424580353 DATC_RRSyncDis 1500;
BA_ "Version" SG_ 2424580353 DATC_RRSyncDis "19.12.00";
BA_ "GenMsgCycleTime" BO_ 649 0;
BA_ "Description" SG_ 649 DLBCU_SmartCtrl_1h "½º¸¶Æ® ÀÚ¼¼Á¦¾î DLBCU ¿¬µ¿ Á¶Àý¿¡ µû¸¥ °³¼±ÇöÈ² AVN Ç¥½Ã¹®±¸_1½Ã°£";
BA_ "GenSigSendType" SG_ 649 DLBCU_SmartCtrl_1h 4;
BA_ "UserSigValidity" SG_ 649 DLBCU_SmartCtrl_1h 1;
BA_REL_ "GenSigTimeoutTime" BU_SG_REL_ CGW_CCU SG_ 649 DLBCU_SmartCtrl_1h 0;
BA_ "Version" SG_ 649 DLBCU_SmartCtrl_1h "19.10.02";
BA_ "Description" SG_ 649 DLBCU_SmartCtrl_2h "½º¸¶Æ® ÀÚ¼¼Á¦¾î DLBCU ¿¬µ¿ Á¶Àý¿¡ µû¸¥ °³¼±ÇöÈ² AVN Ç¥½Ã ¹®±¸_2½Ã°£";
BA_ "GenSigSendType" SG_ 649 DLBCU_SmartCtrl_2h 4;
BA_ "UserSigValidity" SG_ 649 DLBCU_SmartCtrl_2h 1;
BA_REL_ "GenSigTimeoutTime" BU_SG_REL_ CGW_CCU SG_ 649 DLBCU_SmartCtrl_2h 0;
BA_ "Version" SG_ 649 DLBCU_SmartCtrl_2h "19.10.02";
BA_ "Description" SG_ 649 DLBCU_SmartCtrl_Status "½º¸¶Æ® ÀÚ¼¼Á¦¾î 2´Ü°è DLBCU ¿¬µ¿ Á¶Àý µ¿ÀÛ ½ÃÀÛ / Á¾·á / Áß´Ü AVN ÆË¾÷";
BA_ "GenSigSendType" SG_ 649 DLBCU_SmartCtrl_Status 4;
BA_ "UserSigValidity" SG_ 649 DLBCU_SmartCtrl_Status 1;
BA_REL_ "GenSigTimeoutTime" BU_SG_REL_ CGW_CCU SG_ 649 DLBCU_SmartCtrl_Status 0;
BA_ "Version" SG_ 649 DLBCU_SmartCtrl_Status "19.10.03";
BA_ "GenMsgSendType" BO_ 2176872452 0;
BA_ "GenMsgCycleTime" BO_ 2176872452 50;
BA_ "GenMsgCycleTimeFast" BO_ 2176872452 0;
BA_ "GenMsgNrOfRepetition" BO_ 2176872452 0;
BA_ "VFrameFormat" BO_ 2176872452 1;
BA_ "GenMsgCycleTime" BO_ 172 0;
BA_ "Description" SG_ 172 BLTN_CAM_FR_VerPos_NvalueSet "Front Camera Vertical position setting value.";
BA_ "GenSigSendType" SG_ 172 BLTN_CAM_FR_VerPos_NvalueSet 4;
BA_ "UserSigValidity" SG_ 172 BLTN_CAM_FR_VerPos_NvalueSet 0;
BA_REL_ "GenSigTimeoutTime" BU_SG_REL_ BLTN_CAM SG_ 172 BLTN_CAM_FR_VerPos_NvalueSet 0;
BA_ "Version" SG_ 172 BLTN_CAM_FR_VerPos_NvalueSet "21.05.02";
BA_ "Description" SG_ 172 BLTN_CAM_AppNoti_PEV_NvalueSet "Parked Event notification to Connectivity Phone App. On/Off";
BA_ "GenSigSendType" SG_ 172 BLTN_CAM_AppNoti_PEV_NvalueSet 4;
BA_ "UserSigValidity" SG_ 172 BLTN_CAM_AppNoti_PEV_NvalueSet 0;
BA_REL_ "GenSigTimeoutTime" BU_SG_REL_ BLTN_CAM SG_ 172 BLTN_CAM_AppNoti_PEV_NvalueSet 0;
BA_ "Version" SG_ 172 BLTN_CAM_AppNoti_PEV_NvalueSet "21.05.02";
BA_ "Description" SG_ 172 BLTN_CAM_WiFi_AutoOn_NvalueSet "Wifi On/Off User setting";
BA_ "GenSigSendType" SG_ 172 BLTN_CAM_WiFi_AutoOn_NvalueSet 4;
BA_ "UserSigValidity" SG_ 172 BLTN_CAM_WiFi_AutoOn_NvalueSet 0;
BA_REL_ "GenSigTimeoutTime" BU_SG_REL_ BLTN_CAM SG_ 172 BLTN_CAM_WiFi_AutoOn_NvalueSet 0;
BA_ "Version" SG_ 172 BLTN_CAM_WiFi_AutoOn_NvalueSet "21.05.02";
BA_ "Description" SG_ 172 BLTN_CAM_StoProp_NvalueSet "Propotion of built-in Cam SD card Propotion set of the Recording Categories";
BA_ "GenSigSendType" SG_ 172 BLTN_CAM_StoProp_NvalueSet 4;
BA_ "UserSigValidity" SG_ 172 BLTN_CAM_StoProp_NvalueSet 0;
BA_REL_ "GenSigTimeoutTime" BU_SG_REL_ BLTN_CAM SG_ 172 BLTN_CAM_StoProp_NvalueSet 0;
BA_ "Version" SG_ 172 BLTN_CAM_StoProp_NvalueSet "21.05.02";
BA_ "Description" SG_ 172 CF_AVN_BLTN_CAM_USMReset "Buit-in Cam USM Reset Request.";
BA_ "GenSigSendType" SG_ 172 CF_AVN_BLTN_CAM_USMReset 4;
BA_ "UserSigValidity" SG_ 172 CF_AVN_BLTN_CAM_USMReset 0;
BA_REL_ "GenSigTimeoutTime" BU_SG_REL_ BLTN_CAM SG_ 172 CF_AVN_BLTN_CAM_USMReset 0;
BA_ "Version" SG_ 172 CF_AVN_BLTN_CAM_USMReset "21.05.02";
BA_ "Description" SG_ 172 CF_AVN_BLTN_CAM_RecReset "Buit-in Cam format(all file delete/Reset) Request.";
BA_ "GenSigSendType" SG_ 172 CF_AVN_BLTN_CAM_RecReset 4;
BA_ "UserSigValidity" SG_ 172 CF_AVN_BLTN_CAM_RecReset 0;
BA_REL_ "GenSigTimeoutTime" BU_SG_REL_ BLTN_CAM SG_ 172 CF_AVN_BLTN_CAM_RecReset 0;
BA_ "Version" SG_ 172 CF_AVN_BLTN_CAM_RecReset "21.05.02";
BA_ "Description" SG_ 172 BLTN_CAM_File_DEL_CPY_Cmd "Buit-in Cam operation control of copying and deleting.";
BA_ "GenSigSendType" SG_ 172 BLTN_CAM_File_DEL_CPY_Cmd 4;
BA_ "UserSigValidity" SG_ 172 BLTN_CAM_File_DEL_CPY_Cmd 0;
BA_REL_ "GenSigTimeoutTime" BU_SG_REL_ BLTN_CAM SG_ 172 BLTN_CAM_File_DEL_CPY_Cmd 0;
BA_ "Version" SG_ 172 BLTN_CAM_File_DEL_CPY_Cmd "21.05.02";
BA_ "Description" SG_ 172 BLTN_CAM_LVDS_Mode_Cmd "This Signal is for LVDS output commend to BLTN_CAM";
BA_ "GenSigSendType" SG_ 172 BLTN_CAM_LVDS_Mode_Cmd 4;
BA_ "UserSigValidity" SG_ 172 BLTN_CAM_LVDS_Mode_Cmd 0;
BA_REL_ "GenSigTimeoutTime" BU_SG_REL_ BLTN_CAM SG_ 172 BLTN_CAM_LVDS_Mode_Cmd 0;
BA_ "Version" SG_ 172 BLTN_CAM_LVDS_Mode_Cmd "21.05.02";
BA_ "Description" SG_ 172 HU_BLTN_CAM_Disp_Touch_Pos_X "X position of touch of display when BLTN-in CAM Engineer mode in";
BA_ "GenSigSendType" SG_ 172 HU_BLTN_CAM_Disp_Touch_Pos_X 4;
BA_ "UserSigValidity" SG_ 172 HU_BLTN_CAM_Disp_Touch_Pos_X 0;
BA_REL_ "GenSigTimeoutTime" BU_SG_REL_ BLTN_CAM SG_ 172 HU_BLTN_CAM_Disp_Touch_Pos_X 0;
BA_ "Version" SG_ 172 HU_BLTN_CAM_Disp_Touch_Pos_X "21.05.02";
BA_ "Description" SG_ 172 HU_BLTN_CAM_Disp_Touch_Pos_Y "Y position of touch of display when BLTN-in CAM Engineer mode in";
BA_ "GenSigSendType" SG_ 172 HU_BLTN_CAM_Disp_Touch_Pos_Y 4;
BA_ "UserSigValidity" SG_ 172 HU_BLTN_CAM_Disp_Touch_Pos_Y 0;
BA_REL_ "GenSigTimeoutTime" BU_SG_REL_ BLTN_CAM SG_ 172 HU_BLTN_CAM_Disp_Touch_Pos_Y 0;
BA_ "Version" SG_ 172 HU_BLTN_CAM_Disp_Touch_Pos_Y "21.05.02";
BA_ "Description" SG_ 172 BLTN_CAM_RR_VerPos_NvalueSet "Rear Camera Vertical position setting value.";
BA_ "GenSigSendType" SG_ 172 BLTN_CAM_RR_VerPos_NvalueSet 4;
BA_ "UserSigValidity" SG_ 172 BLTN_CAM_RR_VerPos_NvalueSet 0;
BA_REL_ "GenSigTimeoutTime" BU_SG_REL_ BLTN_CAM SG_ 172 BLTN_CAM_RR_VerPos_NvalueSet 0;
BA_ "Version" SG_ 172 BLTN_CAM_RR_VerPos_NvalueSet "21.05.02";
BA_ "GenMsgSendType" BO_ 1264 0;
BA_ "GenMsgCycleTime" BO_ 1264 1000;
BA_ "Description" SG_ 1264 HU_TimeSetting "18.08.09_";
BA_ "GenSigSendType" SG_ 1264 HU_TimeSetting 4;
BA_ "GenSigStartValue" SG_ 1264 HU_TimeSetting 3;
BA_ "UserSigValidity" SG_ 1264 HU_TimeSetting 0;
BA_REL_ "GenSigTimeoutTime" BU_SG_REL_ ATS SG_ 1264 HU_TimeSetting 5000;
BA_REL_ "GenSigTimeoutTime" BU_SG_REL_ BLTN_CAM SG_ 1264 HU_TimeSetting 5000;
BA_ "NetworkRequest" SG_ 1264 HU_TimeSetting 0;
BA_ "Version" SG_ 1264 HU_TimeSetting "18.09.02";
BA_ "Description" SG_ 1264 HU_DisplayMinute "18.08.09_";
BA_ "GenSigSendType" SG_ 1264 HU_DisplayMinute 4;
BA_ "GenSigStartValue" SG_ 1264 HU_DisplayMinute 255;
BA_ "UserSigValidity" SG_ 1264 HU_DisplayMinute 0;
BA_REL_ "GenSigTimeoutTime" BU_SG_REL_ ATS SG_ 1264 HU_DisplayMinute 5000;
BA_REL_ "GenSigTimeoutTime" BU_SG_REL_ BLTN_CAM SG_ 1264 HU_DisplayMinute 5000;
BA_ "NetworkRequest" SG_ 1264 HU_DisplayMinute 0;
BA_ "Version" SG_ 1264 HU_DisplayMinute "18.09.02";
BA_ "Description" SG_ 1264 HU_Status "18.08.09_";
BA_ "GenSigSendType" SG_ 1264 HU_Status 4;
BA_ "GenSigStartValue" SG_ 1264 HU_Status 15;
BA_ "UserSigValidity" SG_ 1264 HU_Status 0;
BA_REL_ "GenSigTimeoutTime" BU_SG_REL_ ATS SG_ 1264 HU_Status 5000;
BA_REL_ "GenSigTimeoutTime" BU_SG_REL_ BLTN_CAM SG_ 1264 HU_Status 5000;
BA_ "NetworkRequest" SG_ 1264 HU_Status 0;
BA_ "Version" SG_ 1264 HU_Status "18.09.02";
BA_ "Description" SG_ 1264 HU_DisplaySecond "18.08.09_";
BA_ "GenSigSendType" SG_ 1264 HU_DisplaySecond 4;
BA_ "GenSigStartValue" SG_ 1264 HU_DisplaySecond 255;
BA_ "UserSigValidity" SG_ 1264 HU_DisplaySecond 0;
BA_REL_ "GenSigTimeoutTime" BU_SG_REL_ ATS SG_ 1264 HU_DisplaySecond 5000;
BA_REL_ "GenSigTimeoutTime" BU_SG_REL_ BLTN_CAM SG_ 1264 HU_DisplaySecond 5000;
BA_ "NetworkRequest" SG_ 1264 HU_DisplaySecond 0;
BA_ "Version" SG_ 1264 HU_DisplaySecond "18.09.02";
BA_ "Description" SG_ 1264 HU_DisplayMonth "18.08.09_";
BA_ "GenSigSendType" SG_ 1264 HU_DisplayMonth 4;
BA_ "GenSigStartValue" SG_ 1264 HU_DisplayMonth 15;
BA_ "UserSigValidity" SG_ 1264 HU_DisplayMonth 0;
BA_REL_ "GenSigTimeoutTime" BU_SG_REL_ ATS SG_ 1264 HU_DisplayMonth 5000;
BA_REL_ "GenSigTimeoutTime" BU_SG_REL_ BLTN_CAM SG_ 1264 HU_DisplayMonth 5000;
BA_ "NetworkRequest" SG_ 1264 HU_DisplayMonth 0;
BA_ "Version" SG_ 1264 HU_DisplayMonth "18.09.02";
BA_ "Description" SG_ 1264 HU_DisplayYear1 "18.08.09_";
BA_ "GenSigSendType" SG_ 1264 HU_DisplayYear1 4;
BA_ "GenSigStartValue" SG_ 1264 HU_DisplayYear1 3;
BA_ "UserSigValidity" SG_ 1264 HU_DisplayYear1 0;
BA_REL_ "GenSigTimeoutTime" BU_SG_REL_ ATS SG_ 1264 HU_DisplayYear1 5000;
BA_REL_ "GenSigTimeoutTime" BU_SG_REL_ BLTN_CAM SG_ 1264 HU_DisplayYear1 5000;
BA_ "NetworkRequest" SG_ 1264 HU_DisplayYear1 0;
BA_ "Version" SG_ 1264 HU_DisplayYear1 "18.09.02";
BA_ "Description" SG_ 1264 HU_DisplayYear2 "18.08.09_";
BA_ "GenSigSendType" SG_ 1264 HU_DisplayYear2 4;
BA_ "GenSigStartValue" SG_ 1264 HU_DisplayYear2 255;
BA_ "UserSigValidity" SG_ 1264 HU_DisplayYear2 0;
BA_REL_ "GenSigTimeoutTime" BU_SG_REL_ ATS SG_ 1264 HU_DisplayYear2 5000;
BA_REL_ "GenSigTimeoutTime" BU_SG_REL_ BLTN_CAM SG_ 1264 HU_DisplayYear2 5000;
BA_ "NetworkRequest" SG_ 1264 HU_DisplayYear2 0;
BA_ "Version" SG_ 1264 HU_DisplayYear2 "18.09.02";
BA_ "Description" SG_ 1264 HU_DisplayDay "18.08.09_";
BA_ "GenSigSendType" SG_ 1264 HU_DisplayDay 4;
BA_ "GenSigStartValue" SG_ 1264 HU_DisplayDay 255;
BA_ "UserSigValidity" SG_ 1264 HU_DisplayDay 0;
BA_REL_ "GenSigTimeoutTime" BU_SG_REL_ ATS SG_ 1264 HU_DisplayDay 5000;
BA_REL_ "GenSigTimeoutTime" BU_SG_REL_ BLTN_CAM SG_ 1264 HU_DisplayDay 5000;
BA_ "NetworkRequest" SG_ 1264 HU_DisplayDay 0;
BA_ "Version" SG_ 1264 HU_DisplayDay "18.09.02";
BA_ "Description" SG_ 1264 HU_AM_PM_INFO "18.08.09_";
BA_ "GenSigSendType" SG_ 1264 HU_AM_PM_INFO 4;
BA_ "GenSigStartValue" SG_ 1264 HU_AM_PM_INFO 3;
BA_ "UserSigValidity" SG_ 1264 HU_AM_PM_INFO 0;
BA_REL_ "GenSigTimeoutTime" BU_SG_REL_ ATS SG_ 1264 HU_AM_PM_INFO 5000;
BA_REL_ "GenSigTimeoutTime" BU_SG_REL_ BLTN_CAM SG_ 1264 HU_AM_PM_INFO 5000;
BA_ "NetworkRequest" SG_ 1264 HU_AM_PM_INFO 0;
BA_ "Version" SG_ 1264 HU_AM_PM_INFO "18.09.02";
BA_ "Description" SG_ 1264 HU_TimeFormat "18.08.09_";
BA_ "GenSigSendType" SG_ 1264 HU_TimeFormat 4;
BA_ "GenSigStartValue" SG_ 1264 HU_TimeFormat 3;
BA_ "UserSigValidity" SG_ 1264 HU_TimeFormat 0;
BA_REL_ "GenSigTimeoutTime" BU_SG_REL_ ATS SG_ 1264 HU_TimeFormat 5000;
BA_REL_ "GenSigTimeoutTime" BU_SG_REL_ BLTN_CAM SG_ 1264 HU_TimeFormat 5000;
BA_ "NetworkRequest" SG_ 1264 HU_TimeFormat 0;
BA_ "Version" SG_ 1264 HU_TimeFormat "18.09.02";
BA_ "Description" SG_ 1264 HU_ComRefresh "18.08.09_";
BA_ "GenSigSendType" SG_ 1264 HU_ComRefresh 4;
BA_ "GenSigStartValue" SG_ 1264 HU_ComRefresh 3;
BA_ "UserSigValidity" SG_ 1264 HU_ComRefresh 0;
BA_REL_ "GenSigTimeoutTime" BU_SG_REL_ ATS SG_ 1264 HU_ComRefresh 5000;
BA_REL_ "GenSigTimeoutTime" BU_SG_REL_ BLTN_CAM SG_ 1264 HU_ComRefresh 5000;
BA_ "NetworkRequest" SG_ 1264 HU_ComRefresh 0;
BA_ "Version" SG_ 1264 HU_ComRefresh "18.09.02";
BA_ "Description" SG_ 1264 HU_ClockInfo "18.08.09_";
BA_ "GenSigSendType" SG_ 1264 HU_ClockInfo 4;
BA_ "GenSigStartValue" SG_ 1264 HU_ClockInfo 3;
BA_ "UserSigValidity" SG_ 1264 HU_ClockInfo 0;
BA_REL_ "GenSigTimeoutTime" BU_SG_REL_ ATS SG_ 1264 HU_ClockInfo 5000;
BA_REL_ "GenSigTimeoutTime" BU_SG_REL_ BLTN_CAM SG_ 1264 HU_ClockInfo 5000;
BA_ "NetworkRequest" SG_ 1264 HU_ClockInfo 0;
BA_ "Version" SG_ 1264 HU_ClockInfo "18.09.02";
BA_ "Description" SG_ 1264 HU_DisplayHour "18.08.09_";
BA_ "GenSigSendType" SG_ 1264 HU_DisplayHour 4;
BA_ "GenSigStartValue" SG_ 1264 HU_DisplayHour 255;
BA_ "UserSigValidity" SG_ 1264 HU_DisplayHour 0;
BA_REL_ "GenSigTimeoutTime" BU_SG_REL_ ATS SG_ 1264 HU_DisplayHour 5000;
BA_REL_ "GenSigTimeoutTime" BU_SG_REL_ BLTN_CAM SG_ 1264 HU_DisplayHour 5000;
BA_ "NetworkRequest" SG_ 1264 HU_DisplayHour 0;
BA_ "Version" SG_ 1264 HU_DisplayHour "18.09.02";
BA_ "GenMsgSendType" BO_ 1266 0;
BA_ "GenMsgCycleTime" BO_ 1266 1000;
BA_ "GenSigSendType" SG_ 1266 HU_LanguageInfo 4;
BA_ "GenSigStartValue" SG_ 1266 HU_LanguageInfo 255;
BA_ "UserSigValidity" SG_ 1266 HU_LanguageInfo 1;
BA_REL_ "GenSigTimeoutTime" BU_SG_REL_ ATS SG_ 1266 HU_LanguageInfo 5000;
BA_REL_ "GenSigTimeoutTime" BU_SG_REL_ BLTN_CAM SG_ 1266 HU_LanguageInfo 5000;
BA_ "NetworkRequest" SG_ 1266 HU_LanguageInfo 0;
BA_ "NetworkRequestHoldingTime" SG_ 1266 HU_LanguageInfo 5000;
BA_ "Version" SG_ 1266 HU_LanguageInfo "21.06.12";
BA_ "Description" SG_ 1266 HU_MuteStatus "16.03.03_";
BA_ "GenSigSendType" SG_ 1266 HU_MuteStatus 4;
BA_ "GenSigStartValue" SG_ 1266 HU_MuteStatus 3;
BA_ "UserSigValidity" SG_ 1266 HU_MuteStatus 1;
BA_ "NetworkRequest" SG_ 1266 HU_MuteStatus 0;
BA_ "Version" SG_ 1266 HU_MuteStatus "18.04.02";
BA_ "Description" SG_ 1266 HU_WelcomeReady "HU playback ready signal to play welcome animation video";
BA_ "GenSigSendType" SG_ 1266 HU_WelcomeReady 4;
BA_ "UserSigValidity" SG_ 1266 HU_WelcomeReady 0;
BA_ "Version" SG_ 1266 HU_WelcomeReady "19.04.06";
BA_ "Description" SG_ 1266 HU_UsmSupport "17.04.06_";
BA_ "GenSigSendType" SG_ 1266 HU_UsmSupport 4;
BA_ "GenSigStartValue" SG_ 1266 HU_UsmSupport 3;
BA_ "UserSigValidity" SG_ 1266 HU_UsmSupport 1;
BA_ "Version" SG_ 1266 HU_UsmSupport "18.04.02";
BA_ "Description" SG_ 1266 HU_NaviStatus "18.11.00_";
BA_ "GenSigSendType" SG_ 1266 HU_NaviStatus 4;
BA_ "UserSigValidity" SG_ 1266 HU_NaviStatus 1;
BA_ "NetworkRequest" SG_ 1266 HU_NaviStatus 0;
BA_ "Version" SG_ 1266 HU_NaviStatus "18.11.01";
BA_ "Description" SG_ 1266 HU_NaviDisp "16.03.03_";
BA_ "GenSigSendType" SG_ 1266 HU_NaviDisp 4;
BA_ "GenSigStartValue" SG_ 1266 HU_NaviDisp 3;
BA_ "UserSigValidity" SG_ 1266 HU_NaviDisp 1;
BA_ "NetworkRequest" SG_ 1266 HU_NaviDisp 0;
BA_ "Version" SG_ 1266 HU_NaviDisp "18.04.02";
BA_ "Description" SG_ 1266 HU_BVM_Display_Message "18.08.09_BVM Operation Message";
BA_ "GenSigSendType" SG_ 1266 HU_BVM_Display_Message 4;
BA_ "GenSigStartValue" SG_ 1266 HU_BVM_Display_Message 7;
BA_ "UserSigValidity" SG_ 1266 HU_BVM_Display_Message 3;
BA_ "Version" SG_ 1266 HU_BVM_Display_Message "18.09.02";
BA_ "Description" SG_ 1266 HU_SVM_View_Display "18.04.00_This signal indicates on/off BVM view on the cluster";
BA_ "GenSigSendType" SG_ 1266 HU_SVM_View_Display 4;
BA_ "GenSigStartValue" SG_ 1266 HU_SVM_View_Display 31;
BA_ "UserSigValidity" SG_ 1266 HU_SVM_View_Display 3;
BA_ "Version" SG_ 1266 HU_SVM_View_Display "18.04.02";
BA_ "Description" SG_ 1266 HU_NaviCamSettingStatus "18.08.09_";
BA_ "GenSigSendType" SG_ 1266 HU_NaviCamSettingStatus 4;
BA_ "GenSigStartValue" SG_ 1266 HU_NaviCamSettingStatus 255;
BA_ "UserSigValidity" SG_ 1266 HU_NaviCamSettingStatus 1;
BA_ "NetworkRequest" SG_ 1266 HU_NaviCamSettingStatus 0;
BA_ "Version" SG_ 1266 HU_NaviCamSettingStatus "18.09.02";
BA_ "Description" SG_ 1266 HU_EVSupport "Notification whether EV function support or not.";
BA_ "GenSigSendType" SG_ 1266 HU_EVSupport 4;
BA_ "GenSigStartValue" SG_ 1266 HU_EVSupport 3;
BA_ "UserSigValidity" SG_ 1266 HU_EVSupport 7;
BA_ "Version" SG_ 1266 HU_EVSupport "19.08.06";
BA_ "Description" SG_ 1266 HU_DayNightState "HU(AVNT) display day and night time state (When automatically adjusted)";
BA_ "GenSigSendType" SG_ 1266 HU_DayNightState 4;
BA_ "UserSigValidity" SG_ 1266 HU_DayNightState 0;
BA_ "Version" SG_ 1266 HU_DayNightState "20.11.00";
BA_ "Description" SG_ 1266 HU_AutoBrightState_New "HU Display Brightness State(When automatically adjusted)";
BA_ "GenSigSendType" SG_ 1266 HU_AutoBrightState_New 4;
BA_ "UserSigValidity" SG_ 1266 HU_AutoBrightState_New 0;
BA_ "Version" SG_ 1266 HU_AutoBrightState_New "20.09.01";
BA_ "Description" SG_ 1266 HU_VolumeStatus "16.03.03_";
BA_ "GenSigSendType" SG_ 1266 HU_VolumeStatus 4;
BA_ "GenSigStartValue" SG_ 1266 HU_VolumeStatus 63;
BA_ "UserSigValidity" SG_ 1266 HU_VolumeStatus 1;
BA_ "NetworkRequest" SG_ 1266 HU_VolumeStatus 0;
BA_ "Version" SG_ 1266 HU_VolumeStatus "18.04.02";
BA_ "GenMsgSendType" BO_ 1267 0;
BA_ "GenMsgCycleTime" BO_ 1267 1000;
BA_ "GenSigSendType" SG_ 1267 RSELockOnOff 4;
BA_ "GenSigStartValue" SG_ 1267 RSELockOnOff 3;
BA_ "UserSigValidity" SG_ 1267 RSELockOnOff 1;
BA_REL_ "GenSigTimeoutTime" BU_SG_REL_ APSU SG_ 1267 RSELockOnOff 5000;
BA_REL_ "GenSigTimeoutTime" BU_SG_REL_ ATS SG_ 1267 RSELockOnOff 5000;
BA_ "NetworkRequest" SG_ 1267 RSELockOnOff 0;
BA_ "NetworkRequestHoldingTime" SG_ 1267 RSELockOnOff 5000;
BA_ "Version" SG_ 1267 RSELockOnOff "19.11.11";
BA_ "Description" SG_ 1267 HU_DATC_RearLockSet "18.08.09_";
BA_ "GenSigSendType" SG_ 1267 HU_DATC_RearLockSet 4;
BA_ "GenSigStartValue" SG_ 1267 HU_DATC_RearLockSet 3;
BA_ "UserSigValidity" SG_ 1267 HU_DATC_RearLockSet 3;
BA_ "Version" SG_ 1267 HU_DATC_RearLockSet "18.09.04";
BA_ "Description" SG_ 1267 HU_Graphreset_Info "18.08.09_";
BA_ "GenSigSendType" SG_ 1267 HU_Graphreset_Info 4;
BA_ "GenSigStartValue" SG_ 1267 HU_Graphreset_Info 3;
BA_ "UserSigValidity" SG_ 1267 HU_Graphreset_Info 1;
BA_ "Version" SG_ 1267 HU_Graphreset_Info "18.09.04";
BA_ "Description" SG_ 1267 HU_PhoneActivity "18.08.09_";
BA_ "GenSigSendType" SG_ 1267 HU_PhoneActivity 4;
BA_ "GenSigStartValue" SG_ 1267 HU_PhoneActivity 3;
BA_ "UserSigValidity" SG_ 1267 HU_PhoneActivity 1;
BA_ "NetworkRequest" SG_ 1267 HU_PhoneActivity 0;
BA_ "Version" SG_ 1267 HU_PhoneActivity "19.02.08";
BA_ "Description" SG_ 1267 HU_VRActivity "18.08.09_";
BA_ "GenSigSendType" SG_ 1267 HU_VRActivity 4;
BA_ "GenSigStartValue" SG_ 1267 HU_VRActivity 3;
BA_ "UserSigValidity" SG_ 1267 HU_VRActivity 1;
BA_ "NetworkRequest" SG_ 1267 HU_VRActivity 0;
BA_ "Version" SG_ 1267 HU_VRActivity "19.02.08";
BA_ "Description" SG_ 1267 HU_DATC_AirQuality_Info "18.08.09_";
BA_ "GenSigSendType" SG_ 1267 HU_DATC_AirQuality_Info 4;
BA_ "GenSigStartValue" SG_ 1267 HU_DATC_AirQuality_Info 15;
BA_ "UserSigValidity" SG_ 1267 HU_DATC_AirQuality_Info 3;
BA_ "Version" SG_ 1267 HU_DATC_AirQuality_Info "18.09.04";
BA_ "GenMsgSendType" BO_ 1240 0;
BA_ "Description" SG_ 1240 HU_DistanceUnit "16.12.02_J.H.J. DR Request";
BA_ "GenSigSendType" SG_ 1240 HU_DistanceUnit 4;
BA_ "GenSigStartValue" SG_ 1240 HU_DistanceUnit 3;
BA_ "UserSigValidity" SG_ 1240 HU_DistanceUnit 1;
BA_ "NetworkRequest" SG_ 1240 HU_DistanceUnit 0;
BA_ "Version" SG_ 1240 HU_DistanceUnit "19.02.08";
BA_ "Description" SG_ 1240 HU_ThemeType "This signal indicates current H/Unit GUI theme value. 

 

Detail value -GUI Theme matching table, refer to attachement and ES SPEC";
BA_ "GenSigSendType" SG_ 1240 HU_ThemeType 4;
BA_ "GenSigStartValue" SG_ 1240 HU_ThemeType 15;
BA_ "UserSigValidity" SG_ 1240 HU_ThemeType 0;
BA_REL_ "GenSigTimeoutTime" BU_SG_REL_ ATS SG_ 1240 HU_ThemeType 1500;
BA_REL_ "GenSigTimeoutTime" BU_SG_REL_ BLTN_CAM SG_ 1240 HU_ThemeType 1500;
BA_ "Version" SG_ 1240 HU_ThemeType "20.09.00";
BA_ "Description" SG_ 1240 HU_MicActivity "16.06.02_";
BA_ "GenSigSendType" SG_ 1240 HU_MicActivity 4;
BA_ "GenSigStartValue" SG_ 1240 HU_MicActivity 3;
BA_ "UserSigValidity" SG_ 1240 HU_MicActivity 0;
BA_ "Version" SG_ 1240 HU_MicActivity "19.02.08";
BA_ "Description" SG_ 1240 HU_Scheduled_Setting "Information of scheduled update charge setting

The signal means that scheduled update charaging information send to BMS for BMS SOC control";
BA_ "GenSigSendType" SG_ 1240 HU_Scheduled_Setting 4;
BA_ "UserSigValidity" SG_ 1240 HU_Scheduled_Setting 3;
BA_ "Version" SG_ 1240 HU_Scheduled_Setting "19.05.02";
BA_ "Description" SG_ 1240 AVN_RSPA_ModeSelect "Signal for User's RSPA¥± mode setting

RSPA¥± ¸ðµå ¼±ÅÃ ¸Þ´º CCP Focus ¹× CCP Confirm or Touch °á°ú";
BA_ "GenSigSendType" SG_ 1240 AVN_RSPA_ModeSelect 4;
BA_ "GenSigStartValue" SG_ 1240 AVN_RSPA_ModeSelect 15;
BA_ "UserSigValidity" SG_ 1240 AVN_RSPA_ModeSelect 0;
BA_ "Version" SG_ 1240 AVN_RSPA_ModeSelect "19.08.08";
BA_ "GenSigSendType" SG_ 1240 CF_HU_GPSFlt 4;
BA_ "GenSigStartValue" SG_ 1240 CF_HU_GPSFlt 2;
BA_ "TimeoutValue" SG_ 1240 CF_HU_GPSFlt "0x2";
BA_ "UserSigValidity" SG_ 1240 CF_HU_GPSFlt 0;
BA_ "Version" SG_ 1240 CF_HU_GPSFlt "20.02.02";
BA_ "GenSigSendType" SG_ 1240 AVN_RSPA_CancelInput 4;
BA_ "UserSigValidity" SG_ 1240 AVN_RSPA_CancelInput 0;
BA_ "Version" SG_ 1240 AVN_RSPA_CancelInput "19.05.03";
BA_ "GenSigSendType" SG_ 1240 AVN_RSPA_Disp_Rdy 4;
BA_ "GenSigStartValue" SG_ 1240 AVN_RSPA_Disp_Rdy 3;
BA_ "UserSigValidity" SG_ 1240 AVN_RSPA_Disp_Rdy 0;
BA_ "Version" SG_ 1240 AVN_RSPA_Disp_Rdy "19.05.03";
BA_ "Description" SG_ 1240 CF_AVN_ProfileIDRValue "18.08.22_This signal is only used in User Profile applied H/Unit";
BA_ "GenSigSendType" SG_ 1240 CF_AVN_ProfileIDRValue 4;
BA_ "GenSigStartValue" SG_ 1240 CF_AVN_ProfileIDRValue 15;
BA_ "UserSigValidity" SG_ 1240 CF_AVN_ProfileIDRValue 0;
BA_REL_ "GenSigTimeoutTime" BU_SG_REL_ WPC SG_ 1240 CF_AVN_ProfileIDRValue 1500;
BA_REL_ "GenSigTimeoutTime" BU_SG_REL_ RWPC SG_ 1240 CF_AVN_ProfileIDRValue 1500;
BA_REL_ "GenSigTimeoutTime" BU_SG_REL_ DPSU SG_ 1240 CF_AVN_ProfileIDRValue 1500;
BA_REL_ "GenSigTimeoutTime" BU_SG_REL_ DLBCU SG_ 1240 CF_AVN_ProfileIDRValue 1500;
BA_REL_ "GenSigTimeoutTime" BU_SG_REL_ RCM SG_ 1240 CF_AVN_ProfileIDRValue 1500;
BA_REL_ "GenSigTimeoutTime" BU_SG_REL_ BLTN_CAM SG_ 1240 CF_AVN_ProfileIDRValue 1500;
BA_REL_ "GenSigTimeoutTime" BU_SG_REL_ SGU SG_ 1240 CF_AVN_ProfileIDRValue 1500;
BA_REL_ "GenSigTimeoutTime" BU_SG_REL_ WPC2 SG_ 1240 CF_AVN_ProfileIDRValue 1500;
BA_ "Version" SG_ 1240 CF_AVN_ProfileIDRValue "18.09.04";
BA_ "Description" SG_ 1240 HazardFromHUSVM "18.08.22_This signal is for the 'Premium AVNT6 && SVM&& ConnectedCarService' vehicle only";
BA_ "GenSigSendType" SG_ 1240 HazardFromHUSVM 4;
BA_ "GenSigStartValue" SG_ 1240 HazardFromHUSVM 3;
BA_ "UserSigValidity" SG_ 1240 HazardFromHUSVM 0;
BA_ "Version" SG_ 1240 HazardFromHUSVM "18.09.04";
BA_ "Description" SG_ 1240 OMUOSMirCtrl "18.08.22_This signal is for the 'Premium AVNT 6.0&&SVM&&ConnectedCarService' vehicle only";
BA_ "GenSigSendType" SG_ 1240 OMUOSMirCtrl 4;
BA_ "GenSigStartValue" SG_ 1240 OMUOSMirCtrl 3;
BA_ "UserSigValidity" SG_ 1240 OMUOSMirCtrl 0;
BA_ "Version" SG_ 1240 OMUOSMirCtrl "18.09.04";
BA_ "Description" SG_ 1240 OTAUIStatus "0x00 : Headunit is booting so, Headunit can't display any state

0x01 : Headunit is normal state, Headunit could display according to CCU command.";
BA_ "GenSigSendType" SG_ 1240 OTAUIStatus 4;
BA_ "UserSigValidity" SG_ 1240 OTAUIStatus 0;
BA_ "Version" SG_ 1240 OTAUIStatus "21.03.02";
BA_ "GenSigSendType" SG_ 1240 C_TeleActiveStatus 4;
BA_ "GenSigStartValue" SG_ 1240 C_TeleActiveStatus 3;
BA_ "UserSigValidity" SG_ 1240 C_TeleActiveStatus 0;
BA_ "Version" SG_ 1240 C_TeleActiveStatus "19.04.06";
BA_ "Description" SG_ 1240 HU_AliveStatus "18.08.22_";
BA_ "GenSigSendType" SG_ 1240 HU_AliveStatus 4;
BA_ "GenSigStartValue" SG_ 1240 HU_AliveStatus 3;
BA_ "UserSigValidity" SG_ 1240 HU_AliveStatus 0;
BA_ "NetworkRequest" SG_ 1240 HU_AliveStatus 0;
BA_ "Version" SG_ 1240 HU_AliveStatus "19.02.08";
BA_ "GenSigSendType" SG_ 1240 HU_RTCCheck 4;
BA_ "GenSigStartValue" SG_ 1240 HU_RTCCheck 3;
BA_ "TimeoutValue" SG_ 1240 HU_RTCCheck "0x3";
BA_ "UserSigValidity" SG_ 1240 HU_RTCCheck 3;
BA_REL_ "GenSigTimeoutTime" BU_SG_REL_ APSU SG_ 1240 HU_RTCCheck 1500;
BA_ "Version" SG_ 1240 HU_RTCCheck "20.02.02";
BA_ "GenMsgSendType" BO_ 1265 0;
BA_ "GenMsgCycleTime" BO_ 1265 1000;
BA_ "Description" SG_ 1265 HU_IG3_Request "IG3 wake up and sleep Request signal for EV/PHEV/HEV



Please apply this signal after checking ICU on your vehicle.";
BA_ "GenSigSendType" SG_ 1265 HU_IG3_Request 4;
BA_ "GenSigStartValue" SG_ 1265 HU_IG3_Request 3;
BA_ "UserSigValidity" SG_ 1265 HU_IG3_Request 0;
BA_ "Version" SG_ 1265 HU_IG3_Request "20.03.05";
BA_ "Description" SG_ 1265 HU_Background "HU Backgound image info";
BA_ "GenSigSendType" SG_ 1265 HU_Background 4;
BA_ "GenSigStartValue" SG_ 1265 HU_Background 7;
BA_ "UserSigValidity" SG_ 1265 HU_Background 1;
BA_REL_ "GenSigTimeoutTime" BU_SG_REL_ ATS SG_ 1265 HU_Background 5000;
BA_REL_ "GenSigTimeoutTime" BU_SG_REL_ BLTN_CAM SG_ 1265 HU_Background 5000;
BA_ "Version" SG_ 1265 HU_Background "21.01.06";
BA_ "Description" SG_ 1265 ccIC_HUD_PbackSta "Status signal for HUD interoperation with IMS

(The number of memory is expanded.)";
BA_ "GenSigSendType" SG_ 1265 ccIC_HUD_PbackSta 4;
BA_ "UserSigValidity" SG_ 1265 ccIC_HUD_PbackSta 3;
BA_REL_ "GenSigTimeoutTime" BU_SG_REL_ DPSU SG_ 1265 ccIC_HUD_PbackSta 5000;
BA_ "Version" SG_ 1265 ccIC_HUD_PbackSta "19.12.00";
BA_ "Description" SG_ 1265 HU_BackgroundFadeInOut "HU Background Fade in/out info

(HEX * Factor) %";
BA_ "GenSigSendType" SG_ 1265 HU_BackgroundFadeInOut 4;
BA_ "GenSigStartValue" SG_ 1265 HU_BackgroundFadeInOut 1023;
BA_ "UserSigValidity" SG_ 1265 HU_BackgroundFadeInOut 1;
BA_REL_ "GenSigTimeoutTime" BU_SG_REL_ ATS SG_ 1265 HU_BackgroundFadeInOut 5000;
BA_REL_ "GenSigTimeoutTime" BU_SG_REL_ BLTN_CAM SG_ 1265 HU_BackgroundFadeInOut 5000;
BA_ "Version" SG_ 1265 HU_BackgroundFadeInOut "21.01.06";
BA_ "Description" SG_ 1265 CF_AVN_AutoWashModeSta "Washer Mode status signal";
BA_ "GenSigSendType" SG_ 1265 CF_AVN_AutoWashModeSta 4;
BA_ "UserSigValidity" SG_ 1265 CF_AVN_AutoWashModeSta 3;
BA_REL_ "GenSigTimeoutTime" BU_SG_REL_ RCM SG_ 1265 CF_AVN_AutoWashModeSta 5000;
BA_ "Version" SG_ 1265 CF_AVN_AutoWashModeSta "21.12.00";
BA_ "GenMsgSendType" BO_ 1247 0;
BA_ "Description" SG_ 1247 Navi_ParkingLot "18.08.09_";
BA_ "GenSigSendType" SG_ 1247 Navi_ParkingLot 4;
BA_ "UserSigValidity" SG_ 1247 Navi_ParkingLot 3;
BA_ "Version" SG_ 1247 Navi_ParkingLot "18.09.04";
BA_ "Description" SG_ 1247 Navi_AirConditionWarning "18.08.09_";
BA_ "GenSigSendType" SG_ 1247 Navi_AirConditionWarning 4;
BA_ "GenSigStartValue" SG_ 1247 Navi_AirConditionWarning 3;
BA_ "UserSigValidity" SG_ 1247 Navi_AirConditionWarning 3;
BA_REL_ "GenSigTimeoutTime" BU_SG_REL_ RCM SG_ 1247 Navi_AirConditionWarning 1500;
BA_ "Version" SG_ 1247 Navi_AirConditionWarning "18.09.04";
BA_ "Description" SG_ 1247 Navi_AirConditionType "18.08.09_";
BA_ "GenSigSendType" SG_ 1247 Navi_AirConditionType 4;
BA_ "GenSigStartValue" SG_ 1247 Navi_AirConditionType 63;
BA_ "UserSigValidity" SG_ 1247 Navi_AirConditionType 3;
BA_ "Version" SG_ 1247 Navi_AirConditionType "18.09.04";
BA_ "GenMsgCycleTime" BO_ 1251 0;
BA_ "Description" SG_ 1251 IAU_EsyAcsProfileID "This signal indicate the current detected profile ID by NFC.

(The drv seat move to the easy access position of the detected profile ID when receive the signal)";
BA_ "GenSigSendType" SG_ 1251 IAU_EsyAcsProfileID 4;
BA_ "UserSigValidity" SG_ 1251 IAU_EsyAcsProfileID 0;
BA_REL_ "GenSigTimeoutTime" BU_SG_REL_ DPSU SG_ 1251 IAU_EsyAcsProfileID 0;
BA_ "NetworkRequest" SG_ 1251 IAU_EsyAcsProfileID 0;
BA_ "NetworkRequestHoldingTime" SG_ 1251 IAU_EsyAcsProfileID 5;
BA_ "Version" SG_ 1251 IAU_EsyAcsProfileID "18.08.12";
BA_ "Description" SG_ 1251 IAU_SmrtPhnID "SmartPhone ID with BLE Connection";
BA_ "GenSigSendType" SG_ 1251 IAU_SmrtPhnID 4;
BA_ "UserSigValidity" SG_ 1251 IAU_SmrtPhnID 0;
BA_ "NetworkRequest" SG_ 1251 IAU_SmrtPhnID 0;
BA_ "NetworkRequestHoldingTime" SG_ 1251 IAU_SmrtPhnID 5;
BA_ "Version" SG_ 1251 IAU_SmrtPhnID "20.04.06";
BA_ "Description" SG_ 1251 IAU_SmrtPhnCmd "SmartPhone RKE Command Indi";
BA_ "GenSigSendType" SG_ 1251 IAU_SmrtPhnCmd 4;
BA_ "UserSigValidity" SG_ 1251 IAU_SmrtPhnCmd 0;
BA_ "NetworkRequest" SG_ 1251 IAU_SmrtPhnCmd 0;
BA_ "NetworkRequestHoldingTime" SG_ 1251 IAU_SmrtPhnCmd 5;
BA_ "Version" SG_ 1251 IAU_SmrtPhnCmd "19.08.08";
BA_ "Description" SG_ 1251 IAUwFRU_ISK_LearningReq "This signal is to request ISK learning to FRU";
BA_ "GenSigSendType" SG_ 1251 IAUwFRU_ISK_LearningReq 4;
BA_ "UserSigValidity" SG_ 1251 IAUwFRU_ISK_LearningReq 0;
BA_ "NetworkRequest" SG_ 1251 IAUwFRU_ISK_LearningReq 0;
BA_ "NetworkRequestHoldingTime" SG_ 1251 IAUwFRU_ISK_LearningReq 5;
BA_ "Version" SG_ 1251 IAUwFRU_ISK_LearningReq "20.05.02";
BA_ "Description" SG_ 1251 IAUwFPM_ISK_LearningReq "This signal is to request ISK learning to FPM";
BA_ "GenSigSendType" SG_ 1251 IAUwFPM_ISK_LearningReq 4;
BA_ "UserSigValidity" SG_ 1251 IAUwFPM_ISK_LearningReq 0;
BA_ "NetworkRequest" SG_ 1251 IAUwFPM_ISK_LearningReq 0;
BA_ "NetworkRequestHoldingTime" SG_ 1251 IAUwFPM_ISK_LearningReq 5;
BA_ "Version" SG_ 1251 IAUwFPM_ISK_LearningReq "20.05.02";
BA_ "Description" SG_ 1251 IAU2FRU_ISKLearnFdbck "This isgnla is learning feedback";
BA_ "GenSigSendType" SG_ 1251 IAU2FRU_ISKLearnFdbck 4;
BA_ "UserSigValidity" SG_ 1251 IAU2FRU_ISKLearnFdbck 0;
BA_ "NetworkRequest" SG_ 1251 IAU2FRU_ISKLearnFdbck 0;
BA_ "NetworkRequestHoldingTime" SG_ 1251 IAU2FRU_ISKLearnFdbck 5;
BA_ "Version" SG_ 1251 IAU2FRU_ISKLearnFdbck "20.04.05";
BA_ "Description" SG_ 1251 IAU2FPM_ISKLearnFdbck "This signal is learning feedback";
BA_ "GenSigSendType" SG_ 1251 IAU2FPM_ISKLearnFdbck 4;
BA_ "UserSigValidity" SG_ 1251 IAU2FPM_ISKLearnFdbck 0;
BA_ "NetworkRequest" SG_ 1251 IAU2FPM_ISKLearnFdbck 0;
BA_ "NetworkRequestHoldingTime" SG_ 1251 IAU2FPM_ISKLearnFdbck 5;
BA_ "Version" SG_ 1251 IAU2FPM_ISKLearnFdbck "20.04.05";
BA_ "GenMsgSendType" BO_ 2172675329 0;
BA_ "GenMsgCycleTime" BO_ 2172675329 50;
BA_ "GenMsgCycleTimeFast" BO_ 2172675329 0;
BA_ "GenMsgNrOfRepetition" BO_ 2172675329 0;
BA_ "VFrameFormat" BO_ 2172675329 1;
BA_ "Description" SG_ 2172675329 IEB_Crc1Val "The data area for CRC calculation is based on the data length (DLC) of the message DB.

The CRC shall be calculated over the entire data block (excluding the CRC bytes) including the user data, alive counter and Data ID

 

- CRC Polynomial (0x1021) , Initial Value : 0xFFFF, XOR value : 0x0000, Data ID : Message ID + 0xF800 

- The initial value is for CRC calculation and the message should be sent with the calculated result value. 

- The mathematical expression to 16 bit CRC polynomial is given here. G(x) = x16 + x12 + x5 + 1";
BA_ "GenSigStartValue" SG_ 2172675329 IEB_Crc1Val 65535;
BA_ "UserSigValidity" SG_ 2172675329 IEB_Crc1Val 3;
BA_ "RoutingFactor" SG_ 2172675329 IEB_Crc1Val 5;
BA_ "Version" SG_ 2172675329 IEB_Crc1Val "19.05.02";
BA_ "Description" SG_ 2172675329 IEB_AlvCnt1Val "For the first transmission request for a data element the counter shall be initialized with 0 and shall be incremented by 1 for every subsequent send request. 

When the counter reaches the maximum value(0xFF), then it shall restart with 0 for the next send request";
BA_ "UserSigValidity" SG_ 2172675329 IEB_AlvCnt1Val 3;
BA_ "RoutingFactor" SG_ 2172675329 IEB_AlvCnt1Val 5;
BA_ "Version" SG_ 2172675329 IEB_AlvCnt1Val "19.05.02";
BA_ "Description" SG_ 2172675329 IEB_SrvLmpDis "The signal indicates the status of the ¡°AHB Service lamp¡±";
BA_ "UserSigValidity" SG_ 2172675329 IEB_SrvLmpDis 3;
BA_ "RoutingFactor" SG_ 2172675329 IEB_SrvLmpDis 5;
BA_ "Version" SG_ 2172675329 IEB_SrvLmpDis "19.05.02";
BA_ "Description" SG_ 2172675329 IEB_DfctvSta "Information regarding the AHB 'defective' indication.";
BA_ "UserSigValidity" SG_ 2172675329 IEB_DfctvSta 3;
BA_ "RoutingFactor" SG_ 2172675329 IEB_DfctvSta 5;
BA_ "Version" SG_ 2172675329 IEB_DfctvSta "19.05.02";
BA_ "Description" SG_ 2172675329 IEB_ActvSta "Information regarding AHB ¡°Control Active¡± signal";
BA_ "UserSigValidity" SG_ 2172675329 IEB_ActvSta 3;
BA_ "RoutingFactor" SG_ 2172675329 IEB_ActvSta 5;
BA_ "Version" SG_ 2172675329 IEB_ActvSta "19.05.02";
BA_ "Description" SG_ 2172675329 IEB_DiagSta "Information regarding the AHB ¡°diagnostic mode¡± indication.";
BA_ "UserSigValidity" SG_ 2172675329 IEB_DiagSta 3;
BA_ "RoutingFactor" SG_ 2172675329 IEB_DiagSta 5;
BA_ "Version" SG_ 2172675329 IEB_DiagSta "19.05.02";
BA_ "Description" SG_ 2172675329 IEB_WrngLmpDis "The signal indicates the status of the ¡°AHB Warning lamp¡±";
BA_ "UserSigValidity" SG_ 2172675329 IEB_WrngLmpDis 3;
BA_ "RoutingFactor" SG_ 2172675329 IEB_WrngLmpDis 5;
BA_ "Version" SG_ 2172675329 IEB_WrngLmpDis "19.05.02";
BA_ "Description" SG_ 2172675329 IEB_MILReq "IEB sends this signal to turn on the Malfunction Indicator Lamp (MIL).";
BA_ "UserSigValidity" SG_ 2172675329 IEB_MILReq 3;
BA_ "RoutingFactor" SG_ 2172675329 IEB_MILReq 5;
BA_ "Version" SG_ 2172675329 IEB_MILReq "19.05.02";
BA_ "Description" SG_ 2172675329 IEB_StrkDpthmmVal "The signal indicates the depth of brake pedal";
BA_ "UserSigValidity" SG_ 2172675329 IEB_StrkDpthmmVal 3;
BA_ "RoutingFactor" SG_ 2172675329 IEB_StrkDpthmmVal 5;
BA_ "Version" SG_ 2172675329 IEB_StrkDpthmmVal "19.05.02";
BA_ "Description" SG_ 2172675329 IEB_BrkActvSta "This signal indicates that a brake switch is activated or not. When the brake switch is activated(pressed) its value is 02H otherwise its value is 01H.

If the ECU does not support this signal the value is 00H.



ÀÌ ½ÅÈ£´Â EV, FCEV ¿¡¼­¸¸ »ç¿ëµÉ ¼ö ÀÖÀ½.

This signal can be used in EV or FCEV vehicle.";
BA_ "UserSigValidity" SG_ 2172675329 IEB_BrkActvSta 3;
BA_ "RoutingFactor" SG_ 2172675329 IEB_BrkActvSta 5;
BA_ "Version" SG_ 2172675329 IEB_BrkActvSta "19.05.05";
BA_ "Description" SG_ 2172675329 IEB_PdlTrvlSnsrFailSta "Information regarding the pedal travel sensor fail status";
BA_ "UserSigValidity" SG_ 2172675329 IEB_PdlTrvlSnsrFailSta 3;
BA_ "RoutingFactor" SG_ 2172675329 IEB_PdlTrvlSnsrFailSta 5;
BA_ "Version" SG_ 2172675329 IEB_PdlTrvlSnsrFailSta "19.05.02";
BA_ "Description" SG_ 2172675329 IEB_PdlCalibSta "Information regarding the pedal travel sensor¡¯s calibration status";
BA_ "UserSigValidity" SG_ 2172675329 IEB_PdlCalibSta 3;
BA_ "RoutingFactor" SG_ 2172675329 IEB_PdlCalibSta 5;
BA_ "Version" SG_ 2172675329 IEB_PdlCalibSta "19.05.02";
BA_ "Description" SG_ 2172675329 IEB_BzrSta "The signal indicates the status of the ¡°Buzzer¡±";
BA_ "UserSigValidity" SG_ 2172675329 IEB_BzrSta 3;
BA_ "RoutingFactor" SG_ 2172675329 IEB_BzrSta 5;
BA_ "Version" SG_ 2172675329 IEB_BzrSta "19.05.02";
BA_ "GenMsgSendType" BO_ 2172675330 0;
BA_ "GenMsgCycleTime" BO_ 2172675330 50;
BA_ "GenMsgCycleTimeFast" BO_ 2172675330 0;
BA_ "GenMsgNrOfRepetition" BO_ 2172675330 0;
BA_ "VFrameFormat" BO_ 2172675330 1;
BA_ "Description" SG_ 2172675330 IEB_Sta "EBS Ready Status

¡Ø Àü/ÈÄ·û¿¡ ´ëÇÑ ±¸ºÐÀÌ ¾ø´Â °æ¿ì¿¡´Â 0x0 (Not Ready) / 0x1(Ready) ¸¸ »ç¿ëÇÑ´Ù.

     : Àü·û ±¸µ¿ È¸»ýÁ¦µ¿ Â÷·®ÀÇ °æ¿ì, 0x0 ´Â Front not Ready / 0x1Àº Front only Ready¸¦ ÀÇ¹ÌÇÔ.";
BA_ "UserSigValidity" SG_ 2172675330 IEB_Sta 3;
BA_ "RoutingFactor" SG_ 2172675330 IEB_Sta 5;
BA_ "Version" SG_ 2172675330 IEB_Sta "19.06.01";
BA_ "UserSigValidity" SG_ 2172675330 IEB_SnsrFailSta 3;
BA_ "RoutingFactor" SG_ 2172675330 IEB_SnsrFailSta 5;
BA_ "Version" SG_ 2172675330 IEB_SnsrFailSta "19.05.02";
BA_ "Description" SG_ 2172675330 IEB_EstTtlBrkFrcNmVal "Estimated Total Brake Force";
BA_ "UserSigValidity" SG_ 2172675330 IEB_EstTtlBrkFrcNmVal 3;
BA_ "RoutingFactor" SG_ 2172675330 IEB_EstTtlBrkFrcNmVal 5;
BA_ "Version" SG_ 2172675330 IEB_EstTtlBrkFrcNmVal "19.05.02";
BA_ "Description" SG_ 2172675330 IEB_RbsWrngLmpSta "This signal indicates RBS warning lamp status.";
BA_ "UserSigValidity" SG_ 2172675330 IEB_RbsWrngLmpSta 3;
BA_ "RoutingFactor" SG_ 2172675330 IEB_RbsWrngLmpSta 5;
BA_ "Version" SG_ 2172675330 IEB_RbsWrngLmpSta "19.05.02";
BA_ "Description" SG_ 2172675330 IEB_StrkDpthPcVal "Brake Pedal Stroke Depth";
BA_ "UserSigValidity" SG_ 2172675330 IEB_StrkDpthPcVal 3;
BA_ "RoutingFactor" SG_ 2172675330 IEB_StrkDpthPcVal 5;
BA_ "Version" SG_ 2172675330 IEB_StrkDpthPcVal "19.05.02";
BA_ "Description" SG_ 2172675330 IEB_EstDpthPcVal "Estimated Brake Pedal Depth for SCC";
BA_ "UserSigValidity" SG_ 2172675330 IEB_EstDpthPcVal 3;
BA_ "RoutingFactor" SG_ 2172675330 IEB_EstDpthPcVal 5;
BA_ "Version" SG_ 2172675330 IEB_EstDpthPcVal "19.05.02";
BA_ "Description" SG_ 2172675330 IEB_AbsNGearReq "indigates N gear position request while ABS activation";
BA_ "UserSigValidity" SG_ 2172675330 IEB_AbsNGearReq 3;
BA_ "RoutingFactor" SG_ 2172675330 IEB_AbsNGearReq 5;
BA_ "Version" SG_ 2172675330 IEB_AbsNGearReq "19.05.02";
BA_ "Description" SG_ 2172675330 IEB_EstBrkPdlValVldSta "Estimated Brake pedal value Validity";
BA_ "GenSigStartValue" SG_ 2172675330 IEB_EstBrkPdlValVldSta 1;
BA_ "UserSigValidity" SG_ 2172675330 IEB_EstBrkPdlValVldSta 3;
BA_ "RoutingFactor" SG_ 2172675330 IEB_EstBrkPdlValVldSta 5;
BA_ "Version" SG_ 2172675330 IEB_EstBrkPdlValVldSta "19.05.02";
BA_ "Description" SG_ 2172675330 IEB_VacSysDfctvSta "This signal indicates Vacuum pump ¡°defective¡±.";
BA_ "UserSigValidity" SG_ 2172675330 IEB_VacSysDfctvSta 3;
BA_ "RoutingFactor" SG_ 2172675330 IEB_VacSysDfctvSta 5;
BA_ "Version" SG_ 2172675330 IEB_VacSysDfctvSta "19.05.02";
BA_ "Description" SG_ 2172675330 IEB_InhbtTrnstnTo4wd_Req "ÀÌ ½ÅÈ£´Â 2WD ¸ðµå¿¡¼­ Á¦µ¿½Ã¿¡ 4WD ÀüÈ¯ ±ÝÁö¸¦ ¿äÃ»ÇÏ´Â ½ÅÈ£ÀÌ´Ù.";
BA_ "UserSigValidity" SG_ 2172675330 IEB_InhbtTrnstnTo4wd_Req 3;
BA_ "RoutingFactor" SG_ 2172675330 IEB_InhbtTrnstnTo4wd_Req 5;
BA_ "Version" SG_ 2172675330 IEB_InhbtTrnstnTo4wd_Req "19.05.03";
BA_ "Description" SG_ 2172675330 IEB_RegenTqLimitNmVal_Frnt "Regen Brake Torque limit at front wheel";
BA_ "UserSigValidity" SG_ 2172675330 IEB_RegenTqLimitNmVal_Frnt 3;
BA_ "RoutingFactor" SG_ 2172675330 IEB_RegenTqLimitNmVal_Frnt 5;
BA_ "Version" SG_ 2172675330 IEB_RegenTqLimitNmVal_Frnt "19.05.03";
BA_ "GenMsgSendType" BO_ 2172675331 0;
BA_ "GenMsgCycleTime" BO_ 2172675331 50;
BA_ "GenMsgCycleTimeFast" BO_ 2172675331 0;
BA_ "GenMsgNrOfRepetition" BO_ 2172675331 0;
BA_ "VFrameFormat" BO_ 2172675331 1;
BA_ "Description" SG_ 2172675331 IEB_RegenTqLimitNmVal_Rear "Regen Brake Torque limit at rear wheel";
BA_ "UserSigValidity" SG_ 2172675331 IEB_RegenTqLimitNmVal_Rear 3;
BA_ "RoutingFactor" SG_ 2172675331 IEB_RegenTqLimitNmVal_Rear 5;
BA_ "Version" SG_ 2172675331 IEB_RegenTqLimitNmVal_Rear "19.05.03";
BA_ "Description" SG_ 2172675331 IEB_DrvWhlSlipFlg_Frnt "This signal is to indicate the slip status of the driving wheels.";
BA_ "UserSigValidity" SG_ 2172675331 IEB_DrvWhlSlipFlg_Frnt 3;
BA_ "RoutingFactor" SG_ 2172675331 IEB_DrvWhlSlipFlg_Frnt 5;
BA_ "Version" SG_ 2172675331 IEB_DrvWhlSlipFlg_Frnt "20.10.02";
BA_ "Description" SG_ 2172675331 IEB_TCS_Req "ÀÌ ½ÅÈ£´Â IEB_01_10ms ¸Þ½ÃÁöÀÇ TCS ÅäÅ© ½ÅÈ£¿¡ ´ëÇÑ Validity¸¦ ÀÇ¹ÌÇÑ´Ù.



0x1 : TCS_TqIntrvntnVal_Frnt, TCS_TqIntrvntnVal_Rear ½ÅÈ£¿¡ ÀÇÇÑ TCS Á¦¾î

0x2 : TCS_MtrTrgtRpm_Frnt, TCS_MtrTrgtRpm_Rear ½ÅÈ£¿¡ ÀÇÇÑ TCS Á¦¾î";
BA_ "UserSigValidity" SG_ 2172675331 IEB_TCS_Req 3;
BA_ "RoutingFactor" SG_ 2172675331 IEB_TCS_Req 5;
BA_ "Version" SG_ 2172675331 IEB_TCS_Req "20.04.05";
BA_ "Description" SG_ 2172675331 IEB_RSC_Req "Validity of RSC torque signal from IEB_01_10ms";
BA_ "UserSigValidity" SG_ 2172675331 IEB_RSC_Req 3;
BA_ "RoutingFactor" SG_ 2172675331 IEB_RSC_Req 5;
BA_ "Version" SG_ 2172675331 IEB_RSC_Req "22.01.02";
BA_ "Description" SG_ 2172675331 TCS_TqFlag_Frnt "ÀÌ ½ÅÈ£´Â IEB_01_10ms ¸Þ½ÃÁöÀÇ TCS Àü·û ÅäÅ© ½ÅÈ£¿¡ ´ëÇÑ ºÎÈ£¸¦ ÀÇ¹ÌÇÑ´Ù.";
BA_ "UserSigValidity" SG_ 2172675331 TCS_TqFlag_Frnt 3;
BA_ "RoutingFactor" SG_ 2172675331 TCS_TqFlag_Frnt 5;
BA_ "Version" SG_ 2172675331 TCS_TqFlag_Frnt "19.05.03";
BA_ "Description" SG_ 2172675331 TCS_TqFlag_Rear "ÀÌ ½ÅÈ£´Â IEB_01_10ms ¸Þ½ÃÁöÀÇ TCS ÈÄ·û ÅäÅ© ½ÅÈ£¿¡ ´ëÇÑ ºÎÈ£¸¦ ÀÇ¹ÌÇÑ´Ù.";
BA_ "UserSigValidity" SG_ 2172675331 TCS_TqFlag_Rear 3;
BA_ "RoutingFactor" SG_ 2172675331 TCS_TqFlag_Rear 5;
BA_ "Version" SG_ 2172675331 TCS_TqFlag_Rear "19.05.03";
BA_ "Description" SG_ 2172675331 RSC_TqFlag_Frnt "ÀÌ ½ÅÈ£´Â IEB_01_10ms ¸Þ½ÃÁöÀÇ RSC Àü·û ÅäÅ© ½ÅÈ£¿¡ ´ëÇÑ ºÎÈ£¸¦ ÀÇ¹ÌÇÑ´Ù.";
BA_ "UserSigValidity" SG_ 2172675331 RSC_TqFlag_Frnt 3;
BA_ "RoutingFactor" SG_ 2172675331 RSC_TqFlag_Frnt 5;
BA_ "Version" SG_ 2172675331 RSC_TqFlag_Frnt "19.05.03";
BA_ "Description" SG_ 2172675331 RSC_TqFlag_Rear "ÀÌ ½ÅÈ£´Â IEB_01_10ms ¸Þ½ÃÁöÀÇ RSC ÈÄ·û ÅäÅ© ½ÅÈ£¿¡ ´ëÇÑ ºÎÈ£¸¦ ÀÇ¹ÌÇÑ´Ù.";
BA_ "UserSigValidity" SG_ 2172675331 RSC_TqFlag_Rear 3;
BA_ "RoutingFactor" SG_ 2172675331 RSC_TqFlag_Rear 5;
BA_ "Version" SG_ 2172675331 RSC_TqFlag_Rear "19.05.03";
BA_ "Description" SG_ 2172675331 TCS_TqIntrvntnVal_Frnt "TCS Á¦¾î¸¦ À§ÇÑ Àü·û ±¸µ¿ÅäÅ©ÀÇ ¿ä±¸°ªÀ» ÀÇ¹Ì.

ºÎÈ£´Â TCS_TqFlag_Frnt ½ÅÈ£¸¦ ÂüÁ¶.";
BA_ "UserSigValidity" SG_ 2172675331 TCS_TqIntrvntnVal_Frnt 3;
BA_ "RoutingFactor" SG_ 2172675331 TCS_TqIntrvntnVal_Frnt 5;
BA_ "Version" SG_ 2172675331 TCS_TqIntrvntnVal_Frnt "19.05.03";
BA_ "Description" SG_ 2172675331 TCS_TqIntrvntnVal_Rear "TCS Á¦¾î¸¦ À§ÇÑ ÈÄ·û ±¸µ¿ÅäÅ©ÀÇ ¿ä±¸°ªÀ» ÀÇ¹Ì.

ºÎÈ£´Â TCS_TqFlag_Rear ½ÅÈ£¸¦ ÂüÁ¶.";
BA_ "UserSigValidity" SG_ 2172675331 TCS_TqIntrvntnVal_Rear 3;
BA_ "RoutingFactor" SG_ 2172675331 TCS_TqIntrvntnVal_Rear 5;
BA_ "Version" SG_ 2172675331 TCS_TqIntrvntnVal_Rear "19.05.03";
BA_ "Description" SG_ 2172675331 RSC_TqIntrvntnVal_Frnt "RSC Á¦¾î¸¦ À§ÇÑ Àü·û ±¸µ¿ÅäÅ©ÀÇ ¿ä±¸°ªÀ» ÀÇ¹Ì.

ºÎÈ£´Â RSC_TqFlag_Frnt ½ÅÈ£¸¦ ÂüÁ¶.";
BA_ "UserSigValidity" SG_ 2172675331 RSC_TqIntrvntnVal_Frnt 3;
BA_ "RoutingFactor" SG_ 2172675331 RSC_TqIntrvntnVal_Frnt 5;
BA_ "Version" SG_ 2172675331 RSC_TqIntrvntnVal_Frnt "19.05.03";
BA_ "Description" SG_ 2172675331 RSC_TqIntrvntnVal_Rear "RSC Á¦¾î¸¦ À§ÇÑ ÈÄ·û ±¸µ¿ÅäÅ©ÀÇ ¿ä±¸°ªÀ» ÀÇ¹Ì.

ºÎÈ£´Â RSC_TqFlag_Rear ½ÅÈ£¸¦ ÂüÁ¶.";
BA_ "UserSigValidity" SG_ 2172675331 RSC_TqIntrvntnVal_Rear 3;
BA_ "RoutingFactor" SG_ 2172675331 RSC_TqIntrvntnVal_Rear 5;
BA_ "Version" SG_ 2172675331 RSC_TqIntrvntnVal_Rear "19.05.03";
BA_ "GenMsgSendType" BO_ 2172675332 0;
BA_ "GenMsgCycleTime" BO_ 2172675332 50;
BA_ "GenMsgCycleTimeFast" BO_ 2172675332 0;
BA_ "GenMsgNrOfRepetition" BO_ 2172675332 0;
BA_ "VFrameFormat" BO_ 2172675332 1;
BA_ "Description" SG_ 2172675332 TCS_MtrTrgtRpm_Flag_Frnt "ÀÌ ½ÅÈ£´Â IEB_01_10ms ¸Þ½ÃÁöÀÇ TCS ÀÛµ¿½Ã Àü·û ¸ðÅÍÀÇ Å¸°Ù RPM ½ÅÈ£(TCS_MtrTrgtRpm_Frnt)¿¡ ´ëÇÑ ºÎÈ£¸¦ ÀÇ¹ÌÇÑ´Ù.";
BA_ "UserSigValidity" SG_ 2172675332 TCS_MtrTrgtRpm_Flag_Frnt 3;
BA_ "RoutingFactor" SG_ 2172675332 TCS_MtrTrgtRpm_Flag_Frnt 5;
BA_ "Version" SG_ 2172675332 TCS_MtrTrgtRpm_Flag_Frnt "20.04.05";
BA_ "Description" SG_ 2172675332 TCS_MtrTrgtRpm_Flag_Rear "ÀÌ ½ÅÈ£´Â IEB_01_10ms ¸Þ½ÃÁöÀÇ TCS ÀÛµ¿½Ã ÈÄ·û ¸ðÅÍÀÇ Å¸°Ù RPM ½ÅÈ£(TCS_MtrTrgtRpm_Rear)¿¡ ´ëÇÑ ºÎÈ£¸¦ ÀÇ¹ÌÇÑ´Ù.";
BA_ "UserSigValidity" SG_ 2172675332 TCS_MtrTrgtRpm_Flag_Rear 3;
BA_ "RoutingFactor" SG_ 2172675332 TCS_MtrTrgtRpm_Flag_Rear 5;
BA_ "Version" SG_ 2172675332 TCS_MtrTrgtRpm_Flag_Rear "20.04.05";
BA_ "Description" SG_ 2172675332 TCS_MtrTrgtRpm_Rear "TCS Á¦¾î¸¦ À§ÇÑ ÈÄ·û ¸ðÅÍÀÇ RPM ¿ä±¸°ªÀ» ÀÇ¹Ì.

ºÎÈ£´Â TCS_MtrTrgtRpm_Flag_Rear ½ÅÈ£¸¦ ÂüÁ¶.";
BA_ "UserSigValidity" SG_ 2172675332 TCS_MtrTrgtRpm_Rear 3;
BA_ "RoutingFactor" SG_ 2172675332 TCS_MtrTrgtRpm_Rear 5;
BA_ "Version" SG_ 2172675332 TCS_MtrTrgtRpm_Rear "20.04.05";
BA_ "Description" SG_ 2172675332 IEB_DriftModeSta "This signal is for a pop-up display on drift mode.";
BA_ "UserSigValidity" SG_ 2172675332 IEB_DriftModeSta 3;
BA_ "RoutingFactor" SG_ 2172675332 IEB_DriftModeSta 5;
BA_ "Version" SG_ 2172675332 IEB_DriftModeSta "20.12.02";
BA_ "Description" SG_ 2172675332 IEB_DriftModeActSta "This signal is for drift mode ON/OFF status";
BA_ "UserSigValidity" SG_ 2172675332 IEB_DriftModeActSta 3;
BA_ "RoutingFactor" SG_ 2172675332 IEB_DriftModeActSta 5;
BA_ "Version" SG_ 2172675332 IEB_DriftModeActSta "20.12.02";
BA_ "Description" SG_ 2172675332 IEB_EstBrkSacFrcNmVal "Estimated brake force value for stop assist control";
BA_ "UserSigValidity" SG_ 2172675332 IEB_EstBrkSacFrcNmVal 3;
BA_ "RoutingFactor" SG_ 2172675332 IEB_EstBrkSacFrcNmVal 5;
BA_ "Version" SG_ 2172675332 IEB_EstBrkSacFrcNmVal "21.11.00";
BA_ "Description" SG_ 2172675332 TCS_MtrTrgtRpm_Frnt "TCS Á¦¾î¸¦ À§ÇÑ Àü·û ¸ðÅÍÀÇ RPM ¿ä±¸°ªÀ» ÀÇ¹Ì.

ºÎÈ£´Â TCS_MtrTrgtRpm_Flag_Frnt ½ÅÈ£¸¦ ÂüÁ¶.";
BA_ "UserSigValidity" SG_ 2172675332 TCS_MtrTrgtRpm_Frnt 3;
BA_ "RoutingFactor" SG_ 2172675332 TCS_MtrTrgtRpm_Frnt 5;
BA_ "Version" SG_ 2172675332 TCS_MtrTrgtRpm_Frnt "20.04.05";
BA_ "GenMsgCycleTime" BO_ 1252 0;
BA_ "Description" SG_ 1252 RKE_Crc1Val "The data area for CRC calculation is based on the data length (DLC) of the message DB.

The CRC shall be calculated over the entire data block (excluding the CRC bytes) including the user data, alive counter and Data ID 

 

- CRC Polynomial (0x1D) , Initial Value : 0x00, XOR value : 0xFF, Data ID Mode : Both, Data ID : Message ID + 0xF800 

- The initial value is for CRC calculation and the message should be sent with the calculated result value. 

The mathematical expression to 8 bit CRC polynomial is given here. G(x) = x8 + x4 + x3 + x2 + 1";
BA_ "GenSigSendType" SG_ 1252 RKE_Crc1Val 4;
BA_ "GenSigStartValue" SG_ 1252 RKE_Crc1Val 255;
BA_ "UserSigValidity" SG_ 1252 RKE_Crc1Val 0;
BA_ "Version" SG_ 1252 RKE_Crc1Val "18.11.08";
BA_ "Description" SG_ 1252 RKE_AlvCnt1Val "For the first transmission request for a data element the counter shall be initialized with 0 and shall be incremented by 1

for every subsequent send request. When the counter reaches the maximum value(0xE), then it shall restart with 0 for the next send request";
BA_ "GenSigSendType" SG_ 1252 RKE_AlvCnt1Val 4;
BA_ "UserSigValidity" SG_ 1252 RKE_AlvCnt1Val 0;
BA_ "Version" SG_ 1252 RKE_AlvCnt1Val "18.11.08";
BA_ "Description" SG_ 1252 RKE_BtnReq "Remote Key Button Request from Folding Key or Smart Key";
BA_ "GenSigSendType" SG_ 1252 RKE_BtnReq 4;
BA_ "UserSigValidity" SG_ 1252 RKE_BtnReq 0;
BA_REL_ "GenSigTimeoutTime" BU_SG_REL_ ATS SG_ 1252 RKE_BtnReq 0;
BA_ "NetworkRequest" SG_ 1252 RKE_BtnReq 0;
BA_ "NetworkRequestHoldingTime" SG_ 1252 RKE_BtnReq 5000;
BA_ "Version" SG_ 1252 RKE_BtnReq "20.12.00";
BA_ "Description" SG_ 1252 RKE_PsdBtnReq "Remote Key Power Sliding Door Button Request from Folding Key or Smart Key";
BA_ "GenSigSendType" SG_ 1252 RKE_PsdBtnReq 4;
BA_ "UserSigValidity" SG_ 1252 RKE_PsdBtnReq 0;
BA_ "NetworkRequest" SG_ 1252 RKE_PsdBtnReq 0;
BA_ "NetworkRequestHoldingTime" SG_ 1252 RKE_PsdBtnReq 5000;
BA_ "Version" SG_ 1252 RKE_PsdBtnReq "17.12.00";
BA_ "Description" SG_ 1252 RKE_WdwUpDnReq "Remote Key Window Up and Down Request from Folding Key or Smart Key";
BA_ "GenSigSendType" SG_ 1252 RKE_WdwUpDnReq 4;
BA_ "UserSigValidity" SG_ 1252 RKE_WdwUpDnReq 0;
BA_REL_ "GenSigTimeoutTime" BU_SG_REL_ RCM SG_ 1252 RKE_WdwUpDnReq 0;
BA_ "NetworkRequest" SG_ 1252 RKE_WdwUpDnReq 0;
BA_ "NetworkRequestHoldingTime" SG_ 1252 RKE_WdwUpDnReq 5000;
BA_ "Version" SG_ 1252 RKE_WdwUpDnReq "17.12.00";
BA_ "Description" SG_ 1252 RKE_TrnkTlgtBtnReq "This signal for Tailgate or Trunk open CMD

While RKE Tailgate(Trunk) Button push, This Signal Tx On

While Tailgate(Trunk) Button released, This Signal Tx Off";
BA_ "GenSigSendType" SG_ 1252 RKE_TrnkTlgtBtnReq 4;
BA_ "UserSigValidity" SG_ 1252 RKE_TrnkTlgtBtnReq 0;
BA_ "NetworkRequest" SG_ 1252 RKE_TrnkTlgtBtnReq 0;
BA_ "NetworkRequestHoldingTime" SG_ 1252 RKE_TrnkTlgtBtnReq 5000;
BA_ "Version" SG_ 1252 RKE_TrnkTlgtBtnReq "18.07.01";
BA_ "Description" SG_ 1252 RKE_ID "Remote Key Window Up and Down Request from Folding Key or Smart Key



Folding key or smart key ID for recently received RF frame";
BA_ "GenSigSendType" SG_ 1252 RKE_ID 4;
BA_ "UserSigValidity" SG_ 1252 RKE_ID 0;
BA_ "Version" SG_ 1252 RKE_ID "17.12.00";
BA_ "Description" SG_ 1252 RKE_PwrDrAllOpnClsReq "Remote Key Button Signal for PSD and PTG opening or closing together";
BA_ "GenSigSendType" SG_ 1252 RKE_PwrDrAllOpnClsReq 4;
BA_ "UserSigValidity" SG_ 1252 RKE_PwrDrAllOpnClsReq 0;
BA_ "NetworkRequest" SG_ 1252 RKE_PwrDrAllOpnClsReq 0;
BA_ "NetworkRequestHoldingTime" SG_ 1252 RKE_PwrDrAllOpnClsReq 5000;
BA_ "Version" SG_ 1252 RKE_PwrDrAllOpnClsReq "19.04.04";
BA_ "GenMsgSendType" BO_ 191 0;
BA_ "Description" SG_ 191 RL_SHVU_DTCdisplay "0x00: DTC is not exist(Fail is not exist)/0x01:IGN2 Fuse Open Detection/0x02:Switch Input Detection at Same Time/0x03:NTC/Heating wire Open Detection/0x04:NTC+/NTC- Terminal Short Detection/0x05:NTC+/Heater+ Terminal Short Detection/0x06:NTC+/Heater-, Heater+/Heater-, Heater+/NTC- Terminal Short Detection/0x07:NTC+/Heater- Wiring Short Detection/0x08:NTC+/Heater-, Heater+/Heater-, Heater+/NTC- Wiring Short Detection/0x09:Target Temperature Dissatisfied/0x0A:Blower+/Blower- Short, Blower+/Blower Speed, Blower-/Blower Speed Wiring Short Detection/0x0B:Blower+/Blower RPM, Blower-/Blower RPM, Blower Speed/Blower RPM Short Detection/0x0C:Blower+, Blower-, Blower Speed Signal open Detection/0x0D:Blower RPM signal Open Detection/0x0E~0xFD:Unused/0xFE:No Display/0xFF:Invalid";
BA_ "GenSigSendType" SG_ 191 RL_SHVU_DTCdisplay 4;
BA_ "UserSigValidity" SG_ 191 RL_SHVU_DTCdisplay 3;
BA_REL_ "GenSigTimeoutTime" BU_SG_REL_ ATS SG_ 191 RL_SHVU_DTCdisplay 1500;
BA_ "NetworkRequest" SG_ 191 RL_SHVU_DTCdisplay 0;
BA_ "NetworkRequestHoldingTime" SG_ 191 RL_SHVU_DTCdisplay 5000;
BA_ "Version" SG_ 191 RL_SHVU_DTCdisplay "19.12.08";
BA_ "Description" SG_ 191 RL_SHVU_DiagMode "0x0:Default/0x1:DTC Mode/0x2:Normal Mode/0x3:Invalid";
BA_ "GenSigSendType" SG_ 191 RL_SHVU_DiagMode 4;
BA_ "UserSigValidity" SG_ 191 RL_SHVU_DiagMode 3;
BA_REL_ "GenSigTimeoutTime" BU_SG_REL_ ATS SG_ 191 RL_SHVU_DiagMode 1500;
BA_ "NetworkRequest" SG_ 191 RL_SHVU_DiagMode 0;
BA_ "NetworkRequestHoldingTime" SG_ 191 RL_SHVU_DiagMode 5000;
BA_ "Version" SG_ 191 RL_SHVU_DiagMode "19.12.08";
BA_ "GenMsgSendType" BO_ 2328016132 0;
BA_ "GenMsgCycleTimeFast" BO_ 2328016132 0;
BA_ "GenMsgNrOfRepetition" BO_ 2328016132 0;
BA_ "VFrameFormat" BO_ 2328016132 1;
BA_ "Description" SG_ 2328016132 VCU_LowSocDispPcVal "Low SOC Display Percent Value";
BA_ "TimeoutValue" SG_ 2328016132 VCU_LowSocDispPcVal "0x0";
BA_ "UserSigValidity" SG_ 2328016132 VCU_LowSocDispPcVal 7;
BA_ "RoutingFactor" SG_ 2328016132 VCU_LowSocDispPcVal 2;
BA_ "Version" SG_ 2328016132 VCU_LowSocDispPcVal "21.03.00";
BA_ "Description" SG_ 2328016132 VCU_DteSocBasedVal "Maximum Drivable Distance with Soc Based (China Only Func)";
BA_ "UserSigValidity" SG_ 2328016132 VCU_DteSocBasedVal 7;
BA_ "RoutingFactor" SG_ 2328016132 VCU_DteSocBasedVal 2;
BA_ "Version" SG_ 2328016132 VCU_DteSocBasedVal "20.12.04";
BA_ "Description" SG_ 2328016132 VCU_InstFuelEcoVal_Per100km "Instant Fuel Economy(kWh/100km)";
BA_ "UserSigValidity" SG_ 2328016132 VCU_InstFuelEcoVal_Per100km 7;
BA_ "RoutingFactor" SG_ 2328016132 VCU_InstFuelEcoVal_Per100km 2;
BA_ "Version" SG_ 2328016132 VCU_InstFuelEcoVal_Per100km "19.03.03";
BA_ "Description" SG_ 2328016132 VCU_InstFuelEcoVal_PerkWh "Fuel Economy in EV";
BA_ "UserSigValidity" SG_ 2328016132 VCU_InstFuelEcoVal_PerkWh 7;
BA_ "RoutingFactor" SG_ 2328016132 VCU_InstFuelEcoVal_PerkWh 2;
BA_ "Version" SG_ 2328016132 VCU_InstFuelEcoVal_PerkWh "19.03.03";
BA_ "Description" SG_ 2328016132 VCU_CO2RdcTripDistVal "Trip Distance for CO2 Reduction";
BA_ "UserSigValidity" SG_ 2328016132 VCU_CO2RdcTripDistVal 7;
BA_ "RoutingFactor" SG_ 2328016132 VCU_CO2RdcTripDistVal 2;
BA_ "Version" SG_ 2328016132 VCU_CO2RdcTripDistVal "19.03.03";
BA_ "Description" SG_ 2328016132 VCU_CO2RdcVal "CO2 Reduction Amount(Integrated Value)";
BA_ "UserSigValidity" SG_ 2328016132 VCU_CO2RdcVal 7;
BA_ "RoutingFactor" SG_ 2328016132 VCU_CO2RdcVal 2;
BA_ "Version" SG_ 2328016132 VCU_CO2RdcVal "19.03.03";
BA_ "Description" SG_ 2328016132 VCU_StopCtrlWarnMsgSta "i-Pedal Warning Message Status";
BA_ "UserSigValidity" SG_ 2328016132 VCU_StopCtrlWarnMsgSta 7;
BA_ "RoutingFactor" SG_ 2328016132 VCU_StopCtrlWarnMsgSta 2;
BA_ "Version" SG_ 2328016132 VCU_StopCtrlWarnMsgSta "21.12.02";
BA_ "Description" SG_ 2328016132 VCU_DrvModeDefault "This signal is the drive mode that needs to return to default on initial strat-up and restart. 

This signal is only used for cluster display.";
BA_ "UserSigValidity" SG_ 2328016132 VCU_DrvModeDefault 7;
BA_ "RoutingFactor" SG_ 2328016132 VCU_DrvModeDefault 2;
BA_ "Version" SG_ 2328016132 VCU_DrvModeDefault "21.09.07";
BA_ "Description" SG_ 2328016132 VCU_DrvModeLast "This signal is the drive mode that needs to maintain on restart.This signal is only used for cluster display* If BitX is 1, the drive mode remains in the last mode on restart.* If BitX is 0, the drive mode returns to default mode on restart.";
BA_ "UserSigValidity" SG_ 2328016132 VCU_DrvModeLast 7;
BA_ "RoutingFactor" SG_ 2328016132 VCU_DrvModeLast 2;
BA_ "Version" SG_ 2328016132 VCU_DrvModeLast "21.09.07";
VAL_ 694 ASAU_NotFootMsgOperStaWarn 0 "OFF" 1 "ON" 2 "Reserved" 3 "Reserved" ;
VAL_ 158 ATS_DATC_FrDrBlowerSet 0 "DATC Off" 1 "0 level (Do not use)" 2 "1 level" 3 "2 level" 4 "3level" 5 "4 level" 6 "5 level" 7 "6 level" 8 "7 level" 9 "8 level" 15 "Invalid" ;
VAL_ 158 ATS_DATC_RrDrTempUpDn 0 "Reserved" 1 "Temp Up" 2 "Temp Down" 3 "Invalid" ;
VAL_ 158 ATS_DATC_RrDrBlowerSet 0 "Off" 1 "0 level" 2 "1 level" 3 "2 level" 4 "3 level" 5 "4 level" 6 "5 level" 7 "6 level" 8 "7 level" 9 "8 level" 14 "reserved" 15 "Invalid" ;
VAL_ 158 ATS_DATC_RrDrModeSet 0 "Off" 1 "VENT" 2 "BL" 3 "FLOOR" 12 "reserved" 13 "reserved" 14 "reserved" 15 "Invalid" ;
VAL_ 158 ATS_DATC_FrDrModeSet 0 "Reserved" 1 "VENT" 2 "BL" 3 "FLOOR" 4 "MIX" 5 "reserved" 6 "reserved" 7 "7 Mode DEF VENT" 8 "reserved" 9 "MODE DEF VENT FLOOR" 10 "7 Mode DEF" 11 "Reserved" 12 "Reserved" 13 "Reserved" 14 "Reserved" 15 "Invalid" ;
VAL_ 158 ATS_DATC_RrOnOffSet 0 "Function Off" 1 "Function On" 2 "reserved" 3 "Invalid" ;
VAL_ 158 ATS_DATC_IntakeSet 0 "REC Off (Fresh On)" 1 "REC ON (Fresh Off)" 2 "reserved" 3 "Invalid" ;
VAL_ 158 ATS_DATC_OffReq 0 "Reserved" 1 "Request" 2 "reserved" 3 "Invalid" ;
VAL_ 158 ATS_DATC_FrDrAutoSet 0 "reserved" 1 "AUTO ON" 2 "reserved" 3 "Invalid" ;
VAL_ 158 ATS_DATC_FrPsTempUpDn 0 "Reserved" 1 "Temp Up" 2 "Temp Down" 3 "Invalid" ;
VAL_ 158 ATS_DATC_FrDefog 0 "Defog Off" 1 "Defog On" 2 "reserved" 3 "Invalid" ;
VAL_ 158 ATS_DATC_RrSyncSet 0 "Reserved" 1 "NOT SYNC" 2 "Rear SYNC" 3 "Invalid" ;
VAL_ 158 ATS_DATC_AcSet 0 "AC Off" 1 "AC ON" 2 "reserved" 3 "Invalid" ;
VAL_ 158 ATS_DATC_AirCleaningSet 0 "Air Cleaning System Off" 1 "Air Cleaning System On" 2 "Air Cleaning System Not Support" 3 "Invalid" ;
VAL_ 158 ATS_DATC_FrDrBlowerUpDn 0 "Reserved" 1 "Up" 2 "Down" 3 "Invalid" ;
VAL_ 158 ATS_DATC_FrDrTempUpDn 0 "Reserved" 1 "Temp Up" 2 "Temp Down" 3 "Invalid" ;
VAL_ 158 ATS_DATC_RrDrAutoSet 0 "Auto Off" 1 "Auto On" 2 "Not Used" 3 "Invalid" ;
VAL_ 157 ATS_DATC_FrDrTempSetC 0 "Blank" 1 "LO" 2 "PHY=HEX*0.5 + 14" 3 "PHY=HEX*0.5 + 14" 4 "PHY=HEX*0.5 + 14" 5 "PHY=HEX*0.5 + 14" 6 "PHY=HEX*0.5 + 14" 7 "PHY=HEX*0.5 + 14" 8 "PHY=HEX*0.5 + 14" 9 "PHY=HEX*0.5 + 14" 10 "PHY=HEX*0.5 + 14" 11 "PHY=HEX*0.5 + 14" 12 "PHY=HEX*0.5 + 14" 13 "PHY=HEX*0.5 + 14" 14 "PHY=HEX*0.5 + 14" 15 "PHY=HEX*0.5 + 14" 16 "PHY=HEX*0.5 + 14" 17 "PHY=HEX*0.5 + 14" 18 "PHY=HEX*0.5 + 14" 19 "PHY=HEX*0.5 + 14" 20 "PHY=HEX*0.5 + 14" 21 "PHY=HEX*0.5 + 14" 22 "PHY=HEX*0.5 + 14" 23 "PHY=HEX*0.5 + 14" 24 "PHY=HEX*0.5 + 14" 25 "PHY=HEX*0.5 + 14" 26 "PHY=HEX*0.5 + 14" 27 "PHY=HEX*0.5 + 14" 28 "PHY=HEX*0.5 + 14" 29 "PHY=HEX*0.5 + 14" 30 "PHY=HEX*0.5 + 14" 31 "PHY=HEX*0.5 + 14" 32 "PHY=HEX*0.5 + 14" 33 "PHY=HEX*0.5 + 14" 34 "PHY=HEX*0.5 + 14" 35 "PHY=HEX*0.5 + 14" 36 "PHY=HEX*0.5 + 14" 37 "0x25~0xFD:Reserved" 253 "0x25~0xFD:Reserved" 254 "HI" 255 "Invalid" ;
VAL_ 157 ATS_DATC_RrDrBlowerUpDn 0 "Reserved" 1 "Blower Up" 2 "Blower Down" 3 "Invalid" ;
VAL_ 157 ATS_DATC_FrSyncSet 0 "Reserved" 1 "NOT SYNC" 2 "SYNC" 3 "Invalid" ;
VAL_ 157 ATS_DATC_RrDrTempSetC 0 "Blank" 1 "LO" 2 "PHY=HEX*0.5 + 14" 3 "PHY=HEX*0.5 + 14" 4 "PHY=HEX*0.5 + 14" 5 "PHY=HEX*0.5 + 14" 6 "PHY=HEX*0.5 + 14" 7 "PHY=HEX*0.5 + 14" 8 "PHY=HEX*0.5 + 14" 9 "PHY=HEX*0.5 + 14" 10 "PHY=HEX*0.5 + 14" 11 "PHY=HEX*0.5 + 14" 12 "PHY=HEX*0.5 + 14" 13 "PHY=HEX*0.5 + 14" 14 "PHY=HEX*0.5 + 14" 15 "PHY=HEX*0.5 + 14" 16 "PHY=HEX*0.5 + 14" 17 "PHY=HEX*0.5 + 14" 18 "PHY=HEX*0.5 + 14" 19 "PHY=HEX*0.5 + 14" 20 "PHY=HEX*0.5 + 14" 21 "PHY=HEX*0.5 + 14" 22 "PHY=HEX*0.5 + 14" 23 "PHY=HEX*0.5 + 14" 24 "PHY=HEX*0.5 + 14" 25 "PHY=HEX*0.5 + 14" 26 "PHY=HEX*0.5 + 14" 27 "PHY=HEX*0.5 + 14" 28 "PHY=HEX*0.5 + 14" 29 "PHY=HEX*0.5 + 14" 30 "PHY=HEX*0.5 + 14" 31 "PHY=HEX*0.5 + 14" 32 "PHY=HEX*0.5 + 14" 33 "PHY=HEX*0.5 + 14" 34 "PHY=HEX*0.5 + 14" 35 "PHY=HEX*0.5 + 14" 36 "PHY=HEX*0.5 + 14" 37 "0x25~0xFC:Reserved" 252 "0x25~0xFC:Reserved" 254 "HI" 255 "Invalid" ;
VAL_ 157 ATS_DATC_RrDrTempSetF 0 "Blank" 1 "LO" 2 "PHY=HEX*1+56" 3 "PHY=HEX*1+56" 4 "PHY=HEX*1+56" 5 "PHY=HEX*1+56" 6 "PHY=HEX*1+56" 7 "PHY=HEX*1+56" 8 "PHY=HEX*1+56" 9 "PHY=HEX*1+56" 10 "PHY=HEX*1+56" 11 "PHY=HEX*1+56" 12 "PHY=HEX*1+56" 13 "PHY=HEX*1+56" 14 "PHY=HEX*1+56" 15 "PHY=HEX*1+56" 16 "PHY=HEX*1+56" 17 "PHY=HEX*1+56" 18 "PHY=HEX*1+56" 19 "PHY=HEX*1+56" 20 "PHY=HEX*1+56" 21 "PHY=HEX*1+56" 22 "PHY=HEX*1+56" 23 "PHY=HEX*1+56" 24 "PHY=HEX*1+56" 25 "PHY=HEX*1+56" 26 "PHY=HEX*1+56" 27 "PHY=HEX*1+56" 28 "PHY=HEX*1+56" 29 "PHY=HEX*1+56" 30 "PHY=HEX*1+56" 31 "PHY=HEX*1+56" 32 "PHY=HEX*1+56" 33 "PHY=HEX*1+56" 34 "PHY=HEX*1+56" 35 "PHY=HEX*1+56" 36 "PHY=HEX*1+56" 37 "0x25~0xFC:Reserved" 252 "0x25~0xFC:Reserved" 254 "HI" 255 "Invalid" ;
VAL_ 157 ATS_DATC_FrPsTempSetC 0 "Blank" 1 "LO" 2 "PHY=HEX*0.5 + 14" 3 "PHY=HEX*0.5 + 14" 4 "PHY=HEX*0.5 + 14" 5 "PHY=HEX*0.5 + 14" 6 "PHY=HEX*0.5 + 14" 7 "PHY=HEX*0.5 + 14" 8 "PHY=HEX*0.5 + 14" 9 "PHY=HEX*0.5 + 14" 10 "PHY=HEX*0.5 + 14" 11 "PHY=HEX*0.5 + 14" 12 "PHY=HEX*0.5 + 14" 13 "PHY=HEX*0.5 + 14" 14 "PHY=HEX*0.5 + 14" 15 "PHY=HEX*0.5 + 14" 16 "PHY=HEX*0.5 + 14" 17 "PHY=HEX*0.5 + 14" 18 "PHY=HEX*0.5 + 14" 19 "PHY=HEX*0.5 + 14" 20 "PHY=HEX*0.5 + 14" 21 "PHY=HEX*0.5 + 14" 22 "PHY=HEX*0.5 + 14" 23 "PHY=HEX*0.5 + 14" 24 "PHY=HEX*0.5 + 14" 25 "PHY=HEX*0.5 + 14" 26 "PHY=HEX*0.5 + 14" 27 "PHY=HEX*0.5 + 14" 28 "PHY=HEX*0.5 + 14" 29 "PHY=HEX*0.5 + 14" 30 "PHY=HEX*0.5 + 14" 31 "PHY=HEX*0.5 + 14" 32 "PHY=HEX*0.5 + 14" 33 "PHY=HEX*0.5 + 14" 34 "PHY=HEX*0.5 + 14" 35 "PHY=HEX*0.5 + 14" 36 "PHY=HEX*0.5 + 14" 37 "0x25~0xFD:Reserved" 253 "0x25~0xFD:Reserved" 254 "HI" 255 "Invalid" ;
VAL_ 157 ATS_DATC_FrPsTempSetF 0 "Blank" 1 "LO" 2 "PHY=HEX*1+56" 3 "PHY=HEX*1+56" 4 "PHY=HEX*1+56" 5 "PHY=HEX*1+56" 6 "PHY=HEX*1+56" 7 "PHY=HEX*1+56" 8 "PHY=HEX*1+56" 9 "PHY=HEX*1+56" 10 "PHY=HEX*1+56" 11 "PHY=HEX*1+56" 12 "PHY=HEX*1+56" 13 "PHY=HEX*1+56" 14 "PHY=HEX*1+56" 15 "PHY=HEX*1+56" 16 "PHY=HEX*1+56" 17 "PHY=HEX*1+56" 18 "PHY=HEX*1+56" 19 "PHY=HEX*1+56" 20 "PHY=HEX*1+56" 21 "PHY=HEX*1+56" 22 "PHY=HEX*1+56" 23 "PHY=HEX*1+56" 24 "PHY=HEX*1+56" 25 "PHY=HEX*1+56" 26 "PHY=HEX*1+56" 27 "PHY=HEX*1+56" 28 "PHY=HEX*1+56" 29 "PHY=HEX*1+56" 30 "PHY=HEX*1+56" 31 "PHY=HEX*1+56" 32 "PHY=HEX*1+56" 33 "PHY=HEX*1+56" 34 "PHY=HEX*1+56" 35 "PHY=HEX*1+56" 36 "PHY=HEX*1+56" 37 "0x25~0xFC:Reserved" 252 "0x25~0xFC:Reserved" 254 "HI" 255 "Invalid" ;
VAL_ 157 ATS_DATC_FrDrTempSetF 0 "Blank" 1 "LO" 2 "PHY=HEX*1 + 56" 3 "PHY=HEX*1 + 56" 4 "PHY=HEX*1 + 56" 5 "PHY=HEX*1 + 56" 6 "PHY=HEX*1 + 56" 7 "PHY=HEX*1 + 56" 8 "PHY=HEX*1 + 56" 9 "PHY=HEX*1 + 56" 10 "PHY=HEX*1 + 56" 11 "PHY=HEX*1 + 56" 12 "PHY=HEX*1 + 56" 13 "PHY=HEX*1 + 56" 14 "PHY=HEX*1 + 56" 15 "PHY=HEX*1 + 56" 16 "PHY=HEX*1 + 56" 17 "PHY=HEX*1 + 56" 18 "PHY=HEX*1 + 56" 19 "PHY=HEX*1 + 56" 20 "PHY=HEX*1 + 56" 21 "PHY=HEX*1 + 56" 22 "PHY=HEX*1 + 56" 23 "PHY=HEX*1 + 56" 24 "PHY=HEX*1 + 56" 25 "PHY=HEX*1 + 56" 26 "PHY=HEX*1 + 56" 27 "PHY=HEX*1 + 56" 28 "PHY=HEX*1 + 56" 29 "PHY=HEX*1 + 56" 30 "PHY=HEX*1 + 56" 31 "PHY=HEX*1 + 56" 32 "PHY=HEX*1 + 56" 33 "PHY=HEX*1 + 56" 34 "PHY=HEX*1 + 56" 35 "PHY=HEX*1 + 56" 36 "PHY=HEX*1 + 56" 37 "0x25~0xFD:Reserved" 253 "0x25~0xFD:Reserved" 254 "HI" 255 "Invalid" ;
VAL_ 2227254529 BAT_Crc1Val 65535 "Signal Invalid (Message with unused CRC. CRC signal is transmitted fixed value)" ;
VAL_ 2227254529 BAT_AlvCnt1Val 255 "Signal Invalid (Message with unused Alive counter. Alive counter signal is transmitted fixed value)" ;
VAL_ 2227254529 BAT_CurrVal 65535 "Error indicator" ;
VAL_ 2227254529 BAT_SocVal 255 "Error indicator" ;
VAL_ 2227254529 BAT_VoltVal 16383 "Error indicator" ;
VAL_ 2227254529 BAT_AuxBattOpt 0 "Not used" 1 "12V LFP Battery is applied" 2 "12V LFP Battery is not applied" 3 "Error indicator" ;
VAL_ 2227254530 BAT_TempVal 511 "Error indicator" ;
VAL_ 2227254530 BAT_SohVal 127 "Error indicator" ;
VAL_ 2227254530 BAT_SnsrInvldSta 0 "Valid Condition" 1 "Invalid Condition" 2 "Not used" 3 "Error indicator" ;
VAL_ 2227254530 BAT_SofVal 127 "Error indicator" ;
VAL_ 2227254530 BAT_RspErrSta 0 "Operating correctly" 1 "Response error" 2 "Not used" 3 "Error indicator" ;
VAL_ 2227254530 BAT_CapacityVal 255 "Error" ;
VAL_ 2227254530 BAT_SocErrSta 0 "Nomal State" 1 "Implausible State" 2 "Not used" 3 "Error indicator" ;
VAL_ 171 BLTN_CAM_UI_Mode_Tmt_Req 0 "Default" 1 "BLTN_CAM UI Terminate Request" 2 "Reserved" 3 "invalid" ;
VAL_ 171 BLTN_CAM_Dis_Touch_BeepSound 0 "Off" 1 "ON" 2 "Keyboard On" 3 "invalid" ;
VAL_ 171 BLTN_CAM_PopUp_Req 0 "Default" 1 "Event Video Record On by manual switch" 2 "Time Lapse Record Started" 3 "Time Lapse Record Ended" 4 "micro SD card inserted" 5 "micro SD card removed" 6 "SD Card has problem(format required or need to be replaced)" 7 "Start Parking recording" 8 "Can not Start Parking recording (SD card is removed, not recognizable, or has problem)" 9 "Can not Record Event Video (SD card is removed, not recognizable, or has problem)" 10 "RESERVED" 11 "RESERVED" 12 "RESERVED" 13 "RESERVED" 14 "RESERVED" 15 "Invalid" ;
VAL_ 171 BLTN_CAM_File_List_Renew 0 "Defalut" 1 "the file list and storage space are renewed." 2 "reserved" 3 "Invalid" ;
VAL_ 171 BLTN_CAM_Wifi_Pwd_Chg_State 0 "Default" 1 "the password is changed" 2 "Failed, wrong password, can't change password" 3 "Invalid" ;
VAL_ 2231452929 DATC_PtcRlySta 0 "PTC OFF" 1 "PTC ON Lv1" 2 "PTC ON Lv1&2" 3 "PTC ON Lv1&2&3" 4 "Not used" 5 "Not used" 6 "Not used" 7 "Error Indicator" ;
VAL_ 2231452929 DATC_ManufacturerTyp 0 "FATC Type 0 (default)" 1 "FATC Type 1 (Doowon)" 2 "FATC Type 2 (Hanon)/0X3:FATC Type 3(DENSO)" 4 "Not used" 5 "Not used" 6 "Not used" 7 "Error Indicator" ;
VAL_ 2231452929 DATC_DatcPwmSts 0 "Default" 1 "PWM Off" 2 "PWM On" 3 "Error Indicator" ;
VAL_ 2231452929 DATC_AcnCompTyp 0 "Internal Compressor" 1 "External Compressor with Comp clutch" 2 "External Compressor without Comp clutch" 3 "Fixed Compressor" 4 "electrical Compressor" 6 "Not used" 7 "Error Indicator" ;
VAL_ 2231452929 DATC_EewpRpmLvlReq 0 "MAX A/C" 1 "LOW" 2 "MID" 3 "HIGH" 4 "Not used" 5 "Not used" 6 "Not used" 7 "Error Indicator" ;
VAL_ 2231452929 DATC_Cooldown 0 "Default" 1 "Initial" 2 "Cool down" 3 "Error Indicator" ;
VAL_ 2231452929 DATC_AcnReq 0 "A/C Non-Request" 1 "A/C Request" 2 "Not used" 3 "Error Indicator" ;
VAL_ 2231452929 DATC_BlwSta 0 "Blower Off" 1 "Blower On" 2 "Not used" 3 "Error Indicator" ;
VAL_ 2231452929 DATC_BlwMaxSta 0 "NOT Max blower speed" 1 "Max blower speed" 2 "Not used" 3 "Error Indicator" ;
VAL_ 2231452929 DATC_EngStrtReq 0 "Engine Not on Request" 1 "Engine Auto Start Request" 2 "Not used" 3 "Error Indicator" ;
VAL_ 2231452929 DATC_IsgInhbtReq 0 "ISG Inhibit Request Off" 1 "ISG Inhibit Request ON" 2 "Not used" 3 "Error Indicator" ;
VAL_ 2231452929 DATC_AcnCompOnReq 0 "A/C COMP Request Off" 1 "A/C COMP Request ON" 2 "Not used" 3 "Error Indicator" ;
VAL_ 2231452929 DATC_SrvLmpReq 0 "Off" 1 "Service Lamp On" 2 "Not used" 3 "Error Indicator" ;
VAL_ 2231452929 DATC_EcvFltSta 0 "Normal(No fault)" 1 "ECV Control Fault" 2 "Not used" 3 "Error Indicator" ;
VAL_ 2231452929 DATC_CalcAcnCompTqVal 254 "Not used" 255 "Error Indicator" ;
VAL_ 2231452930 DATC_AcnECompOpSta 0 "E-Compressor Not-Operation" 1 "E-Compressor Operation" 2 "Not used" 3 "Error Indicator" ;
VAL_ 2231452930 DATC_HVCompIntlkSta 0 "Disconnect" 1 "Connect" 2 "Not used" 3 "Error Indicator" ;
VAL_ 2231452930 DATC_HVIntDischrgLkReq 0 "Not Request" 1 "Request" 2 "Not used" 3 "Error Indicator" ;
VAL_ 2231452930 DATC_AcnECompMaxReqPwrVal 1023 "Error Indicator" ;
VAL_ 2231452930 DATC_AcnCompFltSta 0 "A/C E-Compressor Normal" 1 "A/C E-Compressor Fail" 2 "Not used" 3 "Error Indicator" ;
VAL_ 2231452930 DATC_AcnECompCnsmptPwrVal 1023 "Error Indicator" ;
VAL_ 2231452930 DATC_MainRlyOffReq 0 "Non-Request" 1 "Request" 2 "Not used" 3 "Error Indicator" ;
VAL_ 2231452930 DATC_MixDfgSelSta 0 "Battery FAN Non-on Request" 1 "Battery FAN On Request" 2 "Not used" 3 "Error Indicator" ;
VAL_ 2231452930 DATC_BattChlrVlvSta 0 "Dafault" 1 "Valve Off (OPEN)" 2 "Valve On (CLOSE)" 3 "Error Indicator" ;
VAL_ 2231452930 DATC_WaterPmpOnReq 0 "Engine Water Pump Non request" 1 "Engine Water Pump On request" 2 "Not used" 3 "Error Indicator" ;
VAL_ 2231452930 DATC_AcnECompSpdVal 65534 "Not used" 65535 "Error Indicator" ;
VAL_ 2231452930 DATC_AcnCompSlpModCodVal 0 "Normal" 1 "Thermistor open" 2 "Thermister short" 4 "Over torque stall" 8 "Short circuit current" 16 "Driver voltage" 32 "Current measuring" 64 "Max Temperature Gradient" 128 "Internal Error" 255 "Error" ;
VAL_ 2231452930 DATC_RrDfgOpSta 0 "Rear Defog Off" 1 "Rear Defog On" 2 "Not used" 3 "Error Indicator" ;
VAL_ 2231452930 DATC_AcnECompCANFltSta 0 "LOCAL CAN Normal" 1 "LOCAL CAN Fail" 2 "Not used" 3 "Error Indicator" ;
VAL_ 2231452931 DATC_AcnCompWaitCodVal 0 "Normal" 1 "Low_Voltage" 2 "High_Voltage" 4 "Over_Heat_Protection" 8 "Over_Loaded" 16 "Over_Current_Protection" 32 "Abnormal(not receiving)" 64 "Missed_Restart" ;
VAL_ 2231452931 DATC_RadFanReq_Duty 254 "EMS Wake Up Req" ;
VAL_ 2231452931 DATC_OutTempSnsrVal 255 "Error" ;
VAL_ 2231452931 DATC_ActvEco 0 "Active ECO Button is not selected" 1 "Active ECO Button is selected" 2 "Not used" 3 "Error Indicator" ;
VAL_ 2231452931 DATC_AUTOActv 0 "Default" 1 "Automatic control is Active" 2 "Not used" 3 "Error Indicator" ;
VAL_ 2231452931 DATC_DfgSw 0 "FRONT DEF switch is not selected" 1 "FRONT DEF switch is selected" 2 "Not Used" 3 "Error Indicator" ;
VAL_ 2231452931 DATC_BattChlrVlv_FltCode 0 "Dafault" 1 "No Error" 2 "Error" 3 "Error Indicator" ;
VAL_ 2231452931 DATC_BattEvapVlvSta 0 "Default" 1 "Valve Off (OPEN)" 2 "Valve On (CLOSE)" 3 "Error Indicator" ;
VAL_ 2231452931 DATC_BattEvapVlv_FltCode 0 "Default" 1 "No Error" 2 "Error" 3 "Error Indicator" ;
VAL_ 2231452931 DATC_Wrmup 0 "Default" 1 "Initial" 2 "Warm Up" 3 "Error Indicator" ;
VAL_ 2231452931 DATC_SSC_EngStrtReq 0 "Normal (Default)" 1 "Engine Auto Start Request" 2 "Reserved" 3 "Error Indicator" ;
VAL_ 2231452931 DATC_AcnCompSta 1 "Initialize Mode" 2 "Standby Mode" 4 "Wait Mode" 8 "Sleep Mode" 16 "Operating Mode" 255 "Error" ;
VAL_ 2231452932 DATC_SSC_InhbtReq 0 "Normal (Default)" 1 "Inhibit Engine Stop" 2 "Reserved" 3 "Error Indicator" ;
VAL_ 2231452932 DATC_EngIdlRpmUpReq 0 "Off" 1 "A/C Off request" 2 "A/C On request" 3 "A/C On and Engine Speed 1 stage up request" 4 "A/C On and Engine Speed 2 stage up request" 5 "Warmup_Idle RPM_Up" 6 "Reserved" 7 "Error Indicator" ;
VAL_ 2231452932 DATC_MaxBlwVolt 0 "Default" 1 "OFF" 2 "ON (B+)" 3 "Error Indicator" ;
VAL_ 2231452932 DATC_HVACPmpOpSta 0 "Default" 1 "Pump Not Operation" 2 "Pump Operation" 3 "Error Indicator" ;
VAL_ 2231452932 DATC_MildCooldown 0 "Default" 1 "Initial State" 2 "Mild Cooldown" 3 "Error Indicator" ;
VAL_ 2231452932 DATC_MildWrmup 0 "Default" 1 "Initial" 2 "Mild Warm Up" 3 "Error Indicator" ;
VAL_ 2231452932 DATC_BlwrLvl 0 "OFF" 1 "0 level" 2 "1 level" 3 "2 level" 4 "3 level" 5 "4 level" 6 "5 level" 7 "6 level" 8 "7 evel" 9 "8 level" 10 "Reserved" 11 "Reserved" 12 "Reserved" 13 "Reserved" 14 "Reserved" 15 "Error Indicator" ;
VAL_ 2231452932 DATC_AAFOpenReq 0 "Default" 1 "1 st" 2 "2 nd" 3 "Open" 4 "Reserved" 5 "Reserved" 6 "Reserved" 7 "Error indicator" ;
VAL_ 2231452932 DATC_BattEwpOpReq 255 "Error Indicator" ;
VAL_ 2382594561 DATC_FrDrvModDis 0 "Off(Blank Display, ÅäÃâ¸ðµå ¹ÌÇ¥½Ã ¿¹) Auto ½Ã)" 1 "VENT" 2 "B_L" 3 "FLOOR" 4 "MIX (7 MODE DEF FLOOR)" 5 "DEF (MAX DEF)" 6 "AUTO DEFOG" 7 "7 MODE DEF VENT" 8 "MODE AUTO" 9 "7 MODE DEF VENT FLOOR" 10 "7 MODE DEF" 11 "DEF VENT (Arrow)" 12 "DEF FLOOR (Arrow)" 13 "DEF VENT FLOOR (Arrow)" 14 "DEF (Arrow)" 15 "Error Indicator" ;
VAL_ 2382594561 DATC_FrPassModDis 0 "Off(Blank Display, ÅäÃâ¸ðµå ¹ÌÇ¥½Ã ¿¹) Auto ½Ã)" 1 "VENT" 2 "B_L" 3 "FLOOR" 4 "MIX (7 MODE DEF FLOOR)" 5 "DEF (MAX DEF)" 6 "AUTO DEFOG" 7 "7 MODE DEF VENT" 8 "MODE AUTO" 9 "7 MODE DEF VENT FLOOR" 10 "7 MODE DEF" 11 "DEF VENT (Arrow)" 12 "DEF FLOOR (Arrow)" 13 "DEF VENT FLOOR (Arrow)" 14 "DEF (Arrow)" 15 "Error Indicator" ;
VAL_ 2382594561 DATC_ClmtTxtPopupOSD 0 "Default" 1 "AirCleaning SYS ON" 2 "AirCleaning SYS OFF" 3 "High Dust AirCleaning ON" 4 "High Dust AirCleaning OFF" 5 "Sensor AirCleaning SYS ON & Closing Window" 6 "Opening Warning" 7 "Auto AirCleaning SYS ON" 8 "Smart Ventilation On" 9 "Washer Intake On" 10 "Rear Climate OFF by ROA" 11 "0x0B~0xFE:Reserved" 254 "0x0B~0xFE:Reserved" 255 "Error Indicator" ;
VAL_ 2382594561 DATC_TempDispUnitSta 0 "Centigrade(¡É)" 1 "Fahrenheit(¢µ)" 2 "Not used" 3 "Error Indicator" ;
VAL_ 2382594561 DATC_DrvAutoDis 0 "AUTO Off" 1 "AUTO On" 2 "Not used" 3 "Error Indicator" ;
VAL_ 2382594561 DATC_FrChgReqDis 0 "OFF" 1 "User Input" 2 "Not used" 3 "Error Indicator" ;
VAL_ 2382594561 DATC_FrClmtScrnDis 0 "Deactived" 1 "Actived" 2 "Not used" 3 "Error Indicator" ;
VAL_ 2382594561 DATC_AcDis 0 "A/C Off" 1 "A/C ON" 2 "Not used" 3 "Error Indicator" ;
VAL_ 2382594561 DATC_IntakeSta 0 "Default" 1 "REC (Fresh off)" 2 "FRE (REC off)" 3 "Error Indicator" ;
VAL_ 2382594561 DATC_TempDrLvl 0 "Default" 1 "Max Cool" 2 "Cool2" 3 "Cool1" 4 "Warm1" 5 "Warm2" 6 "Max Hot" 7 "Not Used" 8 "Not Used" 9 "Not Used" 10 "Not Used" 11 "Not Used" 12 "Not Used" 13 "Not Used" 14 "Not Used" 15 "Error Indicator" ;
VAL_ 2424580353 DATC_StrWhlHtrSwReq 0 "Default" 1 "OFF" 2 "ON" 3 "Error Indicator" ;
VAL_ 2424580353 DATC_FRStHtrSwReq 0 "Default" 1 "OFF" 2 "ON" 3 "Error Indicator" ;
VAL_ 2424580353 DATC_FRStVentSwReq 0 "Default" 1 "OFF" 2 "ON" 3 "Error Indicator" ;
VAL_ 2424580353 DATC_RrDefSw 0 "Default" 1 "OFF" 2 "ON" 3 "Error Indicator" ;
VAL_ 2424580353 DATC_FLStOpReq 0 "Default" 1 "Integrated control OFF" 2 "OFF" 3 "Left Seat Ventilation 1st ON" 4 "Left Seat Ventilation 1st&2nd ON" 5 "Left Seat Ventilation 1st&2nd&3rd ON" 6 "Left Seat Warmer 1st ON" 7 "Left Seat Warmer 1st&2nd ON" 8 "Left Seat Warmer 1st&2nd&3rd ON" 9 "Not Used" 10 "Not Used" 11 "Not Used" 12 "Not Used" 13 "Not Used" 14 "Not Used" 15 "Error Indicator" ;
VAL_ 2424580353 DATC_FRStOpReq 0 "Default" 1 "Integrated control OFF" 2 "OFF" 3 "Right Seat Ventilation 1st ON" 4 "Right Seat Ventilation 1st&2nd ON" 5 "Right Seat Ventilation 1st&2nd&3rd ON" 6 "Right Seat Warmer 1st ON" 7 "Right Seat Warmer 1st&2nd ON" 8 "Right Seat Warmer 1st&2nd&3rd ON" 9 "Not Used" 10 "Not Used" 11 "Not Used" 12 "Not Used" 13 "Not Used" 14 "Not Used" 15 "Error Indicaotr" ;
VAL_ 2424580353 DATC_FLStHtrSwReq 0 "Default" 1 "OFF" 2 "ON" 3 "Error Indicator" ;
VAL_ 2424580353 DATC_FLStVentSwReq 0 "Default" 1 "OFF" 2 "ON" 3 "Error Indicator" ;
VAL_ 2424580353 DATC_FLStTmblrSwReq 0 "Default" 1 "Up" 2 "Down" 3 "Error Indicator" ;
VAL_ 2424580353 DATC_FRStTmblrSwReq 0 "Default" 1 "Up" 2 "Down" 3 "Error Indicator" ;
VAL_ 2424580353 DATC_RRStHtrSwReq 0 "Default" 1 "OFF" 2 "ON" 3 "Error Indicator" ;
VAL_ 2424580353 DATC_RRStVentSwReq 0 "Default" 1 "OFF" 2 "ON" 3 "Error Indicator" ;
VAL_ 2424580353 DATC_RLStHtrSwReq 0 "Default" 1 "OFF" 2 "ON" 3 "Error Indicator" ;
VAL_ 2424580353 DATC_RLStVentSwReq 0 "Default" 1 "OFF" 2 "ON" 3 "Error Indicator" ;
VAL_ 2424580353 DATC_FRWndShldHtSW 0 "Default" 1 "Off" 2 "On" 3 "Error Indicator" ;
VAL_ 2424580353 DATC_WhistlelNoise 0 "Default" 1 "Off" 2 "On (Whistle Noise Prevent)" 3 "Error Indicator" ;
VAL_ 2424580353 DATC_WdwClsReq 0 "Default" 1 "Close Request" 2 "Reserved" 3 "Error Indicator" ;
VAL_ 2424580353 DATC_RRSyncDis 0 "Rear SYNC Off" 1 "Rear SYNC On" 2 "Not used" 3 "Error Indicator" ;
VAL_ 649 DLBCU_SmartCtrl_1h 0 "Default" 1 "Group1" 2 "Group2" 3 "Group3" 4 "Group4" 5 "Group5" 6 "Group6" 7 "Group7" 8 "Group8" 9 "Group9" 10 "General Group" 11 "Unused" 12 "Unused" 13 "Unused" 14 "Unused" 15 "Invalid" ;
VAL_ 649 DLBCU_SmartCtrl_2h 0 "Default" 1 "Group1" 2 "Group2" 3 "Group3" 4 "Group4" 5 "Group5" 6 "Group6" 7 "Group7" 8 "Group8" 9 "Group9" 10 "General Group" 11 "Unused" 12 "Unused" 13 "Unused" 14 "Unused" 15 "Invalid" ;
VAL_ 649 DLBCU_SmartCtrl_Status 0 "Default" 1 "Start" 2 "Finished" 3 "Stop" 4 "Unused" 5 "Unused" 6 "Unused" 7 "Invalid" ;
VAL_ 172 BLTN_CAM_FR_VerPos_NvalueSet 0 "Mid" 1 "Upper Level (1 ~ 10)" 2 "Upper Level (1 ~ 10)" 3 "Upper Level (1 ~ 10)" 4 "Upper Level (1 ~ 10)" 5 "Upper Level (1 ~ 10)" 6 "Upper Level (1 ~ 10)" 7 "Upper Level (1 ~ 10)" 8 "Upper Level (1 ~ 10)" 9 "Upper Level (1 ~ 10)" 10 "Upper Level (1 ~ 10)" 10 "Reserved" 11 "Reserved" 12 "Reserved" 13 "Reserved" 14 "Reserved" 15 "Reserved" 16 "Reserved" 17 "Lower Level (-1 ~ -10)" 18 "Lower Level (-1 ~ -10)" 19 "Lower Level (-1 ~ -10)" 20 "Lower Level (-1 ~ -10)" 21 "Lower Level (-1 ~ -10)" 22 "Lower Level (-1 ~ -10)" 23 "Lower Level (-1 ~ -10)" 24 "Lower Level (-1 ~ -10)" 25 "Lower Level (-1 ~ -10)" 26 "Lower Level (-1 ~ -10)" 27 "Reserved" 28 "Reserved" 29 "Reserved" 30 "Reserved" 31 "Invalid" ;
VAL_ 172 BLTN_CAM_AppNoti_PEV_NvalueSet 0 "Default" 1 "Off" 2 "On" 3 "Invalid" ;
VAL_ 172 BLTN_CAM_WiFi_AutoOn_NvalueSet 0 "Default" 1 "Off" 2 "On" 3 "Invalid" ;
VAL_ 172 BLTN_CAM_StoProp_NvalueSet 0 "Normal" 1 "On While Recordings" 2 "On While Parked" 3 "Driving Events" 4 "Parked Events" 5 "Reserved" 6 "Reserved" 7 "Reserved" 8 "Reserved" 9 "Reserved" 10 "Reserved" 11 "Reserved" 12 "Reserved" 13 "Reserved" 14 "Reserved" 15 "Invalid" ;
VAL_ 172 CF_AVN_BLTN_CAM_USMReset 0 "Default" 1 "Built-in CAM USM Reset" 2 "Reserved" 3 "Invalid" ;
VAL_ 172 CF_AVN_BLTN_CAM_RecReset 0 "Default" 1 "Record Data Reset(format)" 2 "Reserved" 3 "Invalid" ;
VAL_ 172 BLTN_CAM_File_DEL_CPY_Cmd 0 "Default" 1 "Pause the operation" 2 "Cancel the operation" 3 "Continue operation" 4 "Reserved" 5 "Reserved" 6 "Reserved" 7 "Reserved" 8 "Reserved" 9 "Reserved" 10 "Reserved" 11 "Reserved" 12 "Reserved" 13 "Reserved" 14 "Reserved" 15 "Invalid" ;
VAL_ 172 BLTN_CAM_LVDS_Mode_Cmd 0 "Front and Rear Camera" 1 "Front Camera for AR Navi." 2 "Built-In Cam Engineer Mode" 3 "Reserved" ;
VAL_ 172 HU_BLTN_CAM_Disp_Touch_Pos_X 0 "0x0x0~0x77F:X position of the touch(Pixel)" 1919 "0x0x0~0x77F:X position of the touch(Pixel)" 2046 "Default" 2047 "Invalid" ;
VAL_ 172 HU_BLTN_CAM_Disp_Touch_Pos_Y 0 "0x0x0~0x3FD:Y position of the touch(Pixel)" 1021 "0x0x0~0x3FD:Y position of the touch(Pixel)" 1022 "Default" 1023 "Invalid" ;
VAL_ 172 BLTN_CAM_RR_VerPos_NvalueSet 0 "Mid" 1 "Upper Level (1 ~ 10)" 2 "Upper Level (1 ~ 10)" 3 "Upper Level (1 ~ 10)" 4 "Upper Level (1 ~ 10)" 5 "Upper Level (1 ~ 10)" 6 "Upper Level (1 ~ 10)" 7 "Upper Level (1 ~ 10)" 8 "Upper Level (1 ~ 10)" 9 "Upper Level (1 ~ 10)" 10 "Upper Level (1 ~ 10)" 10 "Reserved" 11 "Reserved" 12 "Reserved" 13 "Reserved" 14 "Reserved" 15 "Reserved" 16 "Reserved" 17 "Lower Level (-1 ~ -10)" 18 "Lower Level (-1 ~ -10)" 19 "Lower Level (-1 ~ -10)" 20 "Lower Level (-1 ~ -10)" 21 "Lower Level (-1 ~ -10)" 22 "Lower Level (-1 ~ -10)" 23 "Lower Level (-1 ~ -10)" 24 "Lower Level (-1 ~ -10)" 25 "Lower Level (-1 ~ -10)" 26 "Lower Level (-1 ~ -10)" 27 "Reserved" 28 "Reserved" 29 "Reserved" 30 "Reserved" 31 "Invalid" ;
VAL_ 1264 HU_TimeSetting 0 "not used" 1 "User Time" 2 "GPS Time" 3 "invalid" ;
VAL_ 1264 HU_DisplayMinute 0 "0 minute" 59 "59 Minute" 255 "invalid" ;
VAL_ 1264 HU_Status 0 "not used" 1 "Booting Head Unit" 2 "GPS receiving" 3 "Setting Mode" 4 "GPS Unavailable Mode" 5 "No GPS" 15 "invalid" ;
VAL_ 1264 HU_DisplaySecond 0 "0 minute" 59 "59 second" 255 "invalid" ;
VAL_ 1264 HU_DisplayMonth 0 "not used" 1 "1 month" 12 "12 month" 15 "invalid" ;
VAL_ 1264 HU_DisplayYear1 0 "19" 1 "20" 2 "21" 3 "invalid" ;
VAL_ 1264 HU_DisplayYear2 0 "0 year" 99 "99 year" 255 "invalid" ;
VAL_ 1264 HU_DisplayDay 0 "not used" 1 "1 day" 31 "31 day" 255 "invalid" ;
VAL_ 1264 HU_AM_PM_INFO 0 "Not Used" 1 "AM" 2 "PM" 3 "invalid" ;
VAL_ 1264 HU_TimeFormat 0 "Not used" 1 "12Hour" 2 "24Hour" 3 "invalid" ;
VAL_ 1264 HU_ComRefresh 0 "Not Used" 1 "Internal Clock None" 2 "Internal Clock Exist" 3 "Invalid" ;
VAL_ 1264 HU_ClockInfo 0 "Not Used" 1 "ACLOCK Refresh" 2 "Not Used" 3 "invalid" ;
VAL_ 1264 HU_DisplayHour 0 "0 Hour" 23 "23 Hour" 255 "invalid" ;
VAL_ 1266 HU_LanguageInfo 0 "Off" 1 "Korea" 2 "English(US)" 3 "English(UK)" 4 "Simplified chinese" 5 "Traditional chinese" 6 "French(EU)" 7 "Spanish(EU)" 8 "Arabic" 9 "Czech" 10 "Danish" 11 "German" 12 "Italian" 13 "Dutch" 14 "Polish" 15 "Portuguese" 16 "Russain" 17 "Slovak" 18 "Swedish" 19 "Turkish" 20 "French(US)" 21 "Spanish(US)" 22 "English(India)" 23 "Norwegian" 24 "Finnish" 25 "Indonesian" 26 "Brazilian Portuguese" 27 "Malay" 28 "Hungarian" 29 "English (Australia)" 30 "Japanese" 31 "Hindi" 32 "Hebrew" 33 "Greek" 34 "Ukrainian" 35 "Slovenian" 36 "Bulgarian" 37 "Croatian" 38 "Romanian" 39 "Bengali" 40 "Marathi" 41 "Telugu" 42 "Tamil" 43 "Gujarati" 44 "Kannada" 45 "Odia" 46 "Malayalam" 47 "Punjabi" 48 "Thai" 49 "Tagalog" 50 "Vietnamese" 51 "0x33~0xFE:Reserved" 254 "0x33~0xFE:Reserved" 255 "Invalid" ;
VAL_ 1266 HU_MuteStatus 0 "Off" 1 "Mute On" 2 "reserved" 3 "Invalid" ;
VAL_ 1266 HU_WelcomeReady 0 "Default" 1 "Ready" 2 "Reserved" 3 "Invalid" ;
VAL_ 1266 HU_UsmSupport 0 "Not support" 1 "Support" 2 "reserved" 3 "Invalid" ;
VAL_ 1266 HU_NaviStatus 0 "Booting" 1 "Normal Operation" 2 "No SD Card(Map)" 3 "Invalid" ;
VAL_ 1266 HU_NaviDisp 0 "Non_Navi" 1 "Navi" 2 "reserved" 3 "Invalid" ;
VAL_ 1266 HU_BVM_Display_Message 0 "Not Used" 1 "No Message" 2 "Rain_Warning Message" 3 "Reserved" 4 "Reserved" 5 "Reserved" 6 "Reserved" 7 "Invalid" ;
VAL_ 1266 HU_SVM_View_Display 0 "Not Used" 1 "AVM Display View OFF" 31 "Invalid" 2 "AVM Display View ON(LH)" 3 "AVM Display View ON(RH)" 4 "Reserved" 5 "Reserved" 6 "Reserved" 7 "Reserved" 8 "Reserved" 9 "Reserved" 10 "Reserved" 11 "Reserved" 12 "Reserved" 13 "Reserved" 14 "Reserved" 15 "Reserved" 16 "Reserved" 17 "Reserved" 18 "Reserved" 19 "Reserved" 20 "Reserved" 21 "Reserved" 22 "Reserved" 23 "Reserved" 24 "Reserved" 25 "Reserved" 26 "Reserved" 27 "Reserved" 28 "Reserved" 29 "Reserved" 30 "Reserved" ;
VAL_ 1266 HU_NaviCamSettingStatus 0 "Navi Camera Alert Setting Status" 1 "Navi Camera Alert Setting Status" 2 "Navi Camera Alert Setting Status" 3 "Navi Camera Alert Setting Status" 4 "Navi Camera Alert Setting Status" 5 "Navi Camera Alert Setting Status" 6 "Navi Camera Alert Setting Status" 7 "Navi Camera Alert Setting Status" 8 "Navi Camera Alert Setting Status" 9 "Navi Camera Alert Setting Status" 10 "Navi Camera Alert Setting Status" 11 "Navi Camera Alert Setting Status" 12 "Navi Camera Alert Setting Status" 13 "Navi Camera Alert Setting Status" 14 "Navi Camera Alert Setting Status" 15 "Navi Camera Alert Setting Status" 16 "Navi Camera Alert Setting Status" 17 "Navi Camera Alert Setting Status" 18 "Navi Camera Alert Setting Status" 19 "Navi Camera Alert Setting Status" 20 "Navi Camera Alert Setting Status" 21 "Navi Camera Alert Setting Status" 22 "Navi Camera Alert Setting Status" 23 "Navi Camera Alert Setting Status" 24 "Navi Camera Alert Setting Status" 25 "Navi Camera Alert Setting Status" 26 "Navi Camera Alert Setting Status" 27 "Navi Camera Alert Setting Status" 28 "Navi Camera Alert Setting Status" 29 "Navi Camera Alert Setting Status" 30 "Navi Camera Alert Setting Status" 31 "Navi Camera Alert Setting Status" 32 "0x20~0xFE:Reserved" 254 "0x20~0xFE:Reserved" 255 "Invalid" ;
VAL_ 1266 HU_EVSupport 0 "Not support" 1 "Support" 2 "Reserved" 3 "Invalid" ;
VAL_ 1266 HU_DayNightState 0 "Default" 1 "Day" 2 "Night" 3 "Invalid" ;
VAL_ 1266 HU_AutoBrightState_New 0 "Default" 1 "0x1~0x3FE:Brightness" 1022 "0x1~0x3FE:Brightness" 1023 "Invalid" ;
VAL_ 1266 HU_VolumeStatus 63 "Invalid" ;
VAL_ 1267 RSELockOnOff 0 "Unlock" 1 "LockOn" 2 "Reserved" 3 "Invalid" ;
VAL_ 1267 HU_DATC_RearLockSet 0 "Not Used" 1 "Rear Lock Off" 2 "Rear Lock On" 3 "Invalid" ;
VAL_ 1267 HU_Graphreset_Info 0 "No Action" 1 "Clear Request" 2 "Reserved" 3 "Invalid" ;
VAL_ 1267 HU_PhoneActivity 0 "Deactivated" 1 "Activated" 2 "reserved" 3 "Invalid" ;
VAL_ 1267 HU_VRActivity 0 "Deactivated" 1 "Activated" 2 "reserved" 3 "Invalid" ;
VAL_ 1267 HU_DATC_AirQuality_Info 0 "No information" 1 "level 1" 2 "level 2" 3 "level 3" 4 "level 4" 5 "level 5" 6 "level 6" 7 "reserved" 8 "reserved" 9 "reserved" 10 "reserved" 11 "reserved" 12 "reserved" 13 "reserved" 14 "reserved" 15 "invalid" ;
VAL_ 1240 HU_DistanceUnit 0 "Km" 1 "Mile" 2 "Reserved" 3 "Invalid" ;
VAL_ 1240 HU_ThemeType 0 "default" 1 "Aqua(Hyundai)" 16 "Copper" 17 "Copper Rust" 2 "Magenta(Kia)" 32 "ccIC Light" 33 "ccIC Dark" 3 "Eco White" 4 "Eco Black" 5 "Genesis(IKPE)" 6 "Magenta White" ;
VAL_ 1240 HU_MicActivity 0 "Deactivated" 1 "Activated" 2 "reserved" 3 "Invalid" ;
VAL_ 1240 HU_Scheduled_Setting 0 "Scheduled not set" 1 "Scheduled set" 2 "Reserved" 3 "Reserved" 4 "Reserved" 5 "Reserved" 6 "60% SoC Requested" 7 "70% SoC Requested" 8 "80% SoC Requested" 9 "90% SoC Requested" 10 "100% SoC Requested" 11 "Reserved" 12 "Reserved" 13 "Reserved" 14 "Reserved" 15 "Invalid" ;
VAL_ 1240 AVN_RSPA_ModeSelect 0 "None" 1 "CCP focus (1st menu on the left)" 2 "Touch or CCP confirm (1st menu on the left)" 3 "CCP focus (2nd menu on the left)" 4 "Touch or CCP confirm (2nd menu on the left)" 5 "CCP focus (1st menu on the right)" 6 "Touch or CCP confirm (1st menu on the right)" 7 "CCP focus (2nd menu on the right)" 8 "Touch or CCP confirm (2nd menu on the right)" 9 "Reserved" 10 "Reserved" 11 "Reserved" 12 "Reserved" 13 "Reserved" 14 "Reserved" 15 "Invalid" ;
VAL_ 1240 CF_HU_GPSFlt 0 "Normal" 1 "Fault operation" 2 "TimeOut" 3 "Invalid" ;
VAL_ 1240 AVN_RSPA_CancelInput 0 "Init" 1 "No Input" 2 "Cancel Input" 3 "Invalid" ;
VAL_ 1240 AVN_RSPA_Disp_Rdy 0 "Impossible to display" 1 "Possible to display" 2 "Reserved" 3 "Invalid" ;
VAL_ 1240 CF_AVN_ProfileIDRValue 0 "Default" 1 "Guest" 2 "Profile 1" 3 "Profile 2" 4 "reserved" 5 "reserved" 6 "reserved" 7 "reserved" 8 "reserved" 9 "reserved" 10 "reserved" 11 "reserved" 12 "reserved" 13 "reserved" 14 "reserved" 15 "Invalid" ;
VAL_ 1240 HazardFromHUSVM 0 "inactive" 1 "active" 2 "reserved" 3 "invalid" ;
VAL_ 1240 OMUOSMirCtrl 0 "Off" 1 "Fold" 2 "Unfold" 3 "invalid" ;
VAL_ 1240 OTAUIStatus 0 "Not Ready" 1 "Ready" 2 "Reserved" 3 "Invalid" ;
VAL_ 1240 C_TeleActiveStatus 0 "Active" 1 "Deactive" 2 "Reserved" 3 "Invalid" ;
VAL_ 1240 HU_AliveStatus 0 "Not Ready" 1 "On Mode" 2 "Head Unit Update Mode" 3 "Invalid" ;
VAL_ 1240 HU_RTCCheck 0 "Ready" 1 "Checking" 2 "Reserved" 3 "Invalid" ;
VAL_ 1265 HU_IG3_Request 0 "Off" 1 "On" 2 "Reserved" 3 "Invalid" ;
VAL_ 1265 HU_Background 0 "Default" 1 "Day" 2 "Night" 3 "Reserved" 4 "Reserved" 5 "Reserved" 6 "Reserved" 7 "Invalid" ;
VAL_ 1265 ccIC_HUD_PbackSta 0 "Stop" 1 "Play 1" 2 "Play 2" 3 "Health Care IMS" 4 "Profile 1" 5 "Profile 2" 6 "Guest" 7 "Invalid" ;
VAL_ 1265 HU_BackgroundFadeInOut 0 "0x0x0~0x3E8:0.0~100.0%" 1000 "0x0x0~0x3E8:0.0~100.0%" 1001 "Reserved" 1002 "Reserved" 1003 "Reserved" 1004 "Reserved" 1005 "Reserved" 1006 "Reserved" 1007 "Reserved" 1008 "Reserved" 1009 "Reserved" 1010 "Reserved" 1011 "Reserved" 1012 "Reserved" 1013 "Reserved" 1014 "Reserved" 1015 "Reserved" 1016 "Reserved" 1017 "Reserved" 1018 "Reserved" 1019 "Reserved" 1020 "Reserved" 1021 "Reserved" 1022 "Default" 1023 "Invalid" ;
VAL_ 1265 CF_AVN_AutoWashModeSta 0 "Default" 1 "Non Auto Wash Mode" 2 "Auto Wash Mode" 3 "RESERVED" 4 "RESERVED" 5 "RESERVED" 6 "RESERVED" 7 "Invalid" ;
VAL_ 1247 Navi_ParkingLot 0 "Unknown" 1 "Parking Garage (Æó¼âÇü ÁÖÂ÷Àå)" 2 "Reserved" 3 "Invalid" ;
VAL_ 1247 Navi_AirConditionWarning 0 "Unknown" 1 "On(Close)" 2 "Off" 3 "Invalid" ;
VAL_ 1247 Navi_AirConditionType 0 "None" 1 "Defined Value" 2 "Defined Value" 3 "Defined Value" 4 "Defined Value" 5 "Defined Value" 6 "Defined Value" 7 "Defined Value" 8 "Defined Value" 9 "Defined Value" 10 "Defined Value" 11 "Defined Value" 12 "Defined Value" 13 "Defined Value" 14 "Defined Value" 15 "Defined Value" 16 "Defined Value" 17 "Defined Value" 18 "Defined Value" 19 "Defined Value" 20 "Defined Value" 21 "Defined Value" 22 "Defined Value" 23 "Defined Value" 24 "Defined Value" 25 "Defined Value" 26 "Defined Value" 27 "Defined Value" 28 "Defined Value" 29 "Defined Value" 30 "Defined Value" 31 "Defined Value" 32 "Defined Value" 33 "Defined Value" 34 "Defined Value" 35 "Defined Value" 36 "Defined Value" 37 "Defined Value" 38 "Defined Value" 39 "Defined Value" 40 "Defined Value" 41 "Defined Value" 42 "Defined Value" 43 "Defined Value" 44 "Defined Value" 45 "Defined Value" 46 "Defined Value" 47 "Defined Value" 48 "Defined Value" 49 "Defined Value" 50 "Defined Value" 51 "Defined Value" 52 "Defined Value" 53 "Defined Value" 54 "Defined Value" 55 "Defined Value" 56 "Defined Value" 57 "Defined Value" 58 "Defined Value" 59 "Defined Value" 60 "Defined Value" 61 "Defined Value" 62 "Defined Value" 63 "Invalid" ;
VAL_ 1251 IAU_EsyAcsProfileID 0 "Default" 1 "Profile 1" 2 "Profile 2" 3 "Guest" ;
VAL_ 1251 IAU_SmrtPhnID 0 "None" 1 "ID1" 2 "ID2" 3 "ID3" 4 "ID4" 5 "ID5" 6 "ID6" 7 "ID7" 8 "ID8" 9 "Reseved" 10 "Reseved" 11 "Reseved" 12 "Reseved" 13 "Reseved" 14 "Reseved" 15 "Reseved" ;
VAL_ 1251 IAU_SmrtPhnCmd 0 "None" 1 "Reserved" 2 "Reserved" 3 "Reserved" 4 "Reserved" 5 "Reserved" 6 "Reserved" 7 "Tele Cranking Stop" 8 "Reserved" 9 "Forward (RSPA)" 10 "Backward/Parking (RSPA)" 11 "Pause (RSPA)" 12 "PL Lft Out" 13 "PL Rt Out" 14 "Reserved" 15 "Reserved" ;
VAL_ 1251 IAUwFRU_ISK_LearningReq 0 "Default (Normal)" 1 "Start with PSK #1" 2 "Start with PSK #2" 3 "Start with PSK #3" 4 "Start with PSK #4" 5 "Start with PSK #5" 6 "Stop" 7 "Neutral" 8 "Reserved" 9 "Reserved" 10 "Reserved" 11 "Reserved" 12 "Reserved" 13 "Reserved" 14 "Reserved" 15 "Invalid" ;
VAL_ 1251 IAUwFPM_ISK_LearningReq 0 "Default" 1 "Start with PSK #1" 2 "Start with PSK #2" 3 "Start with PSK #3" 4 "Start with PSK #4" 5 "Start with PSK #5" 6 "Stop" 7 "Neutral" 8 "Reserved" 9 "Reserved" 10 "Reserved" 11 "Reserved" 12 "Reserved" 13 "Reserved" 14 "Reserved" 15 "Invalid" ;
VAL_ 1251 IAU2FRU_ISKLearnFdbck 0 "Default" 1 "Positive" 2 "Negative" 3 "Invalid" ;
VAL_ 1251 IAU2FPM_ISKLearnFdbck 0 "Default" 1 "Positive" 2 "Negative" 3 "Invalid" ;
VAL_ 2172675329 IEB_SrvLmpDis 0 "AHB Service Lamp is Off" 1 "AHB Service Lamp is On" 2 "AHB Service Lamp is BLINKING(2HZ)" 3 "Error Indicator" ;
VAL_ 2172675329 IEB_DfctvSta 0 "AHB is normal mode" 1 "AHB is degraded mode" 2 "AHB is defective mode" 3 "Error Indicator" ;
VAL_ 2172675329 IEB_ActvSta 0 "All Control Inactive" 1 "Charging Active" 2 "AHB Control Active" 3 "Chaging Active + AHB Control Active" ;
VAL_ 2172675329 IEB_DiagSta 0 "AHB is not diagnostic mode" 1 "AHB is diagnostic mode" 2 "Not used" 3 "Error Indicator" ;
VAL_ 2172675329 IEB_WrngLmpDis 0 "AHB Warning Lamp is Off" 1 "AHB Warning Lamp is On" 2 "Not used" 3 "Error Indicator" ;
VAL_ 2172675329 IEB_MILReq 0 "No Request" 1 "MIL On Request" 2 "Reserved" 3 "Reserved" ;
VAL_ 2172675329 IEB_BrkActvSta 0 "ECU does not support this function." 1 "Brake switch is not pressed (OFF)" 2 "Brake switch is pressed (ON)" 3 "Brake switch failure" ;
VAL_ 2172675329 IEB_PdlTrvlSnsrFailSta 0 "Normal" 1 "Fail" 2 "Not used" 3 "Error Indicator" ;
VAL_ 2172675329 IEB_PdlCalibSta 0 "Not complete" 1 "Complete" 2 "Not used" 3 "Error Indicator" ;
VAL_ 2172675329 IEB_BzrSta 0 "Buzzer is Off" 1 "Buzzer is On" 2 "Not used" 3 "Error Indicator" ;
VAL_ 2172675330 IEB_Sta 0 "Not Ready" 1 "Ready" 2 "Ready (Front only) & Not Ready(Rear)" 3 "Ready (Rear only) & Not Ready(Front)" ;
VAL_ 2172675330 IEB_SnsrFailSta 0 "Normal" 1 "Fail" 2 "Not used" 3 "Error Indicator" ;
VAL_ 2172675330 IEB_RbsWrngLmpSta 0 "RBS Warning Lamp OFF" 1 "RBS Warning Lamp ON" 2 "Not used" 3 "Error Indicator" ;
VAL_ 2172675330 IEB_AbsNGearReq 0 "Inactive" 1 "N Gear position Request Active" 2 "Not used" 3 "Error Indicator" ;
VAL_ 2172675330 IEB_EstBrkPdlValVldSta 0 "Invalid" 1 "Valid" 2 "Not used" 3 "Error Indicator" ;
VAL_ 2172675330 IEB_VacSysDfctvSta 0 "Vacuum pump NOT defective" 1 "Vacuum pump defective (failed)" 2 "Not used" 3 "Error Indicator" ;
VAL_ 2172675330 IEB_InhbtTrnstnTo4wd_Req 0 "No Request" 1 "Inhibit Transition To 4WD" 2 "Not used" 3 "Not used" ;
VAL_ 2172675331 IEB_DrvWhlSlipFlg_Frnt 0 "No slip occurred at the driving wheels" 1 "Slip occurred at the driving wheels" ;
VAL_ 2172675331 IEB_TCS_Req 0 "TCS control is not active" 1 "TCS control is active by requested TORQUE based" 2 "TCS control is active by requested RPM based" 3 "Not used" ;
VAL_ 2172675331 IEB_RSC_Req 0 "RSC is not active" 1 "RSC is active" 2 "RESERVED" 3 "RESERVED" ;
VAL_ 2172675331 TCS_TqFlag_Frnt 0 "Positive" 1 "Negative" ;
VAL_ 2172675331 TCS_TqFlag_Rear 0 "Positive" 1 "Negative" ;
VAL_ 2172675331 RSC_TqFlag_Frnt 0 "Positive" 1 "Negative" ;
VAL_ 2172675331 RSC_TqFlag_Rear 0 "Positive" 1 "Negative" ;
VAL_ 2172675332 TCS_MtrTrgtRpm_Flag_Frnt 0 "Positive" 1 "Negative" ;
VAL_ 2172675332 TCS_MtrTrgtRpm_Flag_Rear 0 "Positive" 1 "Negative" ;
VAL_ 2172675332 TCS_MtrTrgtRpm_Rear 0 "0x0x000~0xFFE:Motor RPM Target" 4094 "0x0x000~0xFFE:Motor RPM Target" 4095 "Error Value" ;
VAL_ 2172675332 IEB_DriftModeSta 0 "Default" 1 "Drift Mode Activate (ON)" 2 "Drift Mode Deactivate (OFF)" 3 "Defective" ;
VAL_ 2172675332 IEB_DriftModeActSta 0 "Default" 1 "Drift Mode ON" 2 "Drift Mode OFF" 3 "Reserved" ;
VAL_ 2172675332 IEB_EstBrkSacFrcNmVal 0 "0x0x0~0xFFFF:friction brake torque for stop assist control" 65535 "0x0x0~0xFFFF:friction brake torque for stop assist control" ;
VAL_ 2172675332 TCS_MtrTrgtRpm_Frnt 0 "0x0x000~0xFFE:Motor RPM Target" 4094 "0x0x000~0xFFE:Motor RPM Target" 4095 "Error Value" ;
VAL_ 1252 RKE_BtnReq 0 "None" 1 "Lock" 2 "Unlock" 3 "Trunk(Or Tail Gate)" 4 "Panic" 5 "Panic Stop" 6 "Two Step Unlock Warning or India Door Lock/Unlock Sound ON/OFF Set" 7 "Remote Cranking Stop" 8 "Remote Cranking Start" 9 "Forward(RSPA)" 10 "Backward/Parking(RSPA)" 11 "Pause(RSPA)" 12 "Front Trunk" 13 "Reserved" 14 "Charge Door / ImmeChg" 15 "Error Indicator" ;
VAL_ 1252 RKE_PsdBtnReq 0 "Off" 1 "LH On" 2 "RH On" 3 "PanicStop_PSD LH" 4 "PanicStop_PSD RH" 5 "Reseved" 6 "Reseved" 7 "Reserved" 8 "Reserved" 9 "Reserved" 10 "Reserved" 11 "Reserved" 12 "Reserved" 13 "Reserved" 14 "Not Used" 15 "Error Indicator" ;
VAL_ 1252 RKE_WdwUpDnReq 0 "None" 1 "Remote Window Open" 2 "Remote Window Close" 3 "Remote Window Stop" 4 "Reseved" 5 "Reseved" 6 "Not Used" 7 "Error Indicator" ;
VAL_ 1252 RKE_TrnkTlgtBtnReq 0 "Default" 1 "TailgateTrunkOn" 2 "Off" 3 "Reserved" 4 "Reserved" 5 "Reseved" 6 "Reseved" 7 "Error Indiator" ;
VAL_ 1252 RKE_ID 0 "None" 1 "ID1" 2 "ID2" 3 "ID3" 4 "ID4" 5 "Reseved" 6 "Not Used" 7 "Error Indicator" ;
VAL_ 1252 RKE_PwrDrAllOpnClsReq 0 "None" 1 "Open" 2 "Close" 3 "Stop" 4 "Reserved" 5 "Reserved" 6 "Reserved" 7 "Reserved" ;
VAL_ 191 RL_SHVU_DTCdisplay 0 "DTC is not exist(Fail is not exist)" 1 "IGN2 Fuse Open Detection" 2 "Switch Input Detection at Same Time" 3 "NTC/Heating wire Open Detection" 4 "NTC+/NTC- Terminal Short Detection" 5 "NTC+/Heater+ Terminal Short Detection" 6 "NTC+/Heater-, Heater+/Heater-, Heater+/NTC- Terminal Short Detection" 7 "NTC+/Heater- Wiring Short Detection" 8 "NTC+/Heater-, Heater+/Heater-, Heater+/NTC- Wiring Short Detection" 9 "Target Temperature Dissatisfied" 10 "Blower+/Blower- Short, Blower+/Blower Speed, Blower-/Blower Speed Wiring Short Detection" 11 "Blower+/Blower RPM, Blower-/Blower RPM, Blower Speed/Blower RPM Short Detection" 12 "Blower+, Blower-, Blower Speed Signal open Detection" 13 "Blower RPM signal Open Detection" 14 "0xE~0xFD:Unused" 253 "0xE~0xFD:Unused" 254 "No Display" 255 "Invalid" ;
VAL_ 191 RL_SHVU_DiagMode 0 "Default" 1 "DTC Mode" 2 "Normal Mode" 3 "Invalid" ;
VAL_ 2328016132 VCU_StopCtrlWarnMsgSta 0 "None" 1 "i-Pedal On Popup Request" 2 "i-Pedal Off Popup Request" 3 "i-Pedal Forced Off Popup Request" 4 "SAC Off Popup Request" 5 "Reserved" 6 "Reserved" 7 "Reserved" ;
VAL_ 2328016132 VCU_DrvModeDefault 0 "No Data" 1 "Normal (Comfort)" 2 "ECO" 3 "Reserved" ;
